VERSION "HNNBNNNYNNNNNNNNNNNNNNNNNNNNNNNNNNNNNNNNNN/4/%%%/4/'%**4NNN///"

NS_ :

BS_:

BU_: AWC BAP_Tester BMC_MLBevo BMS_MV BMS_NV DCDC_800V_PAG DCDC_HV DCDC_HV_02 DCDC_IHEV FCU_MLBevo_FCEV Gateway Gateway_PAG Ladegeraet_2 Ladegeraet_Konzern LE1 LE2 LE2_3_MLBevo_LB LE_MLBevo LE_MLBevo_LB Sub_Gateway TME

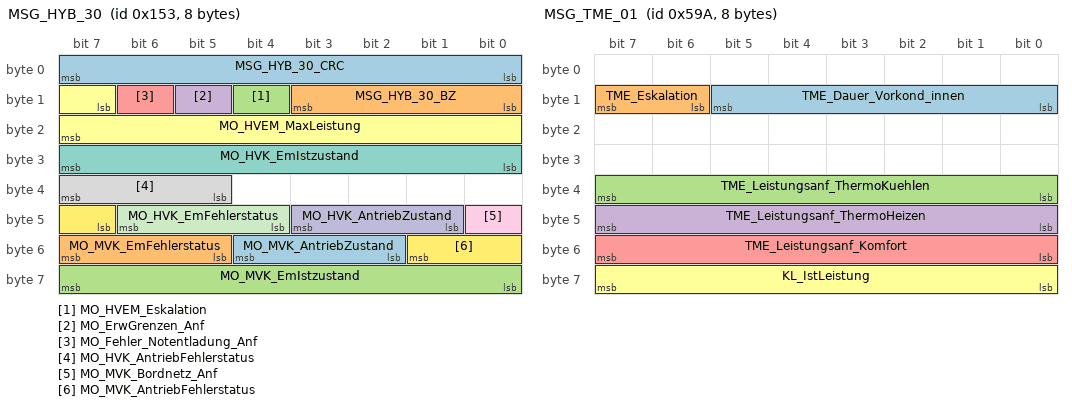
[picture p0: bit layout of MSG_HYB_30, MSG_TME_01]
BO_ 339 MSG_HYB_30: 8 Gateway
 SG_ MSG_HYB_30_CRC : 0|8@1+ (1,0) [0|255] ""  Ladegeraet_Konzern
 SG_ MSG_HYB_30_BZ : 8|4@1+ (1,0) [0|15] ""  Ladegeraet_Konzern
 SG_ MO_HVEM_Eskalation : 12|1@1+ (1,0) [0|1] "" Vector__XXX
 SG_ MO_ErwGrenzen_Anf : 13|1@1+ (1,0) [0|1] ""  BMC_MLBevo
 SG_ MO_Fehler_Notentladung_Anf : 14|1@1+ (1,0) [0|1] "" Vector__XXX
 SG_ MO_HVEM_MaxLeistung : 15|9@1+ (50,0) [0|25450] "Unit_Watt" Vector__XXX
 SG_ MO_HVK_EmIstzustand : 24|8@1+ (1,0) [0|255] "" Vector__XXX
 SG_ MO_HVK_AntriebFehlerstatus : 37|3@1+ (1,0) [0|7] "" Vector__XXX
 SG_ MO_MVK_Bordnetz_Anf : 40|1@1+ (1,0) [0|1] "" Vector__XXX
 SG_ MO_HVK_AntriebZustand : 41|3@1+ (1,0) [0|7] ""  TME
 SG_ MO_HVK_EmFehlerstatus : 44|3@1+ (1,0) [0|7] "" Vector__XXX
 SG_ MO_MVK_AntriebFehlerstatus : 47|3@1+ (1,0) [0|7] "" Vector__XXX
 SG_ MO_MVK_AntriebZustand : 50|3@1+ (1,0) [0|7] "" Vector__XXX
 SG_ MO_MVK_EmFehlerstatus : 53|3@1+ (1,0) [0|7] "" Vector__XXX
 SG_ MO_MVK_EmIstzustand : 56|8@1+ (1,0) [0|255] "" Vector__XXX

BO_ 1434 MSG_TME_01: 8 TME
 SG_ TME_Dauer_Vorkond_innen : 8|6@1+ (1,0) [0|60] "Unit_Minut"  Ladegeraet_Konzern
 SG_ TME_Eskalation : 14|2@1+ (1,0) [0|3] "" Vector__XXX
 SG_ TME_Leistungsanf_ThermoKuehlen : 32|8@1+ (50,0) [0|12650] "Unit_Watt" Vector__XXX
 SG_ TME_Leistungsanf_ThermoHeizen : 40|8@1+ (50,0) [0|12650] "Unit_Watt" Vector__XXX
 SG_ TME_Leistungsanf_Komfort : 48|8@1+ (50,0) [0|12650] "Unit_Watt" Vector__XXX
 SG_ KL_IstLeistung : 56|8@1+ (50,0) [0|12650] "Unit_Watt"  FCU_MLBevo_FCEV,Gateway,Gateway_PAG,Ladegeraet_Konzern

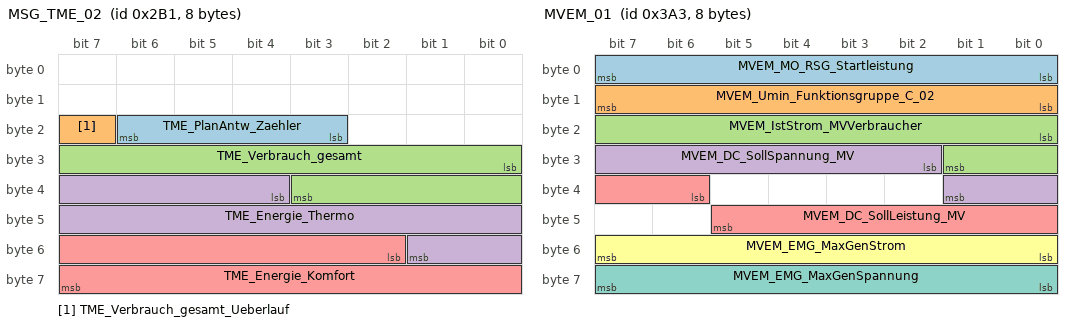
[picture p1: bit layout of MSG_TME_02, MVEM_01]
BO_ 689 MSG_TME_02: 8 TME
 SG_ TME_PlanAntw_Zaehler : 19|4@1+ (1,0) [0|13] "Unit_None"  Gateway,Gateway_PAG,Ladegeraet_2,Ladegeraet_Konzern
 SG_ TME_Verbrauch_gesamt_Ueberlauf : 23|1@1+ (1,0) [0|1] ""  Gateway,Gateway_PAG
 SG_ TME_Verbrauch_gesamt : 24|12@1+ (1,0) [0|4095] "Unit_WattSecond"  Gateway,Gateway_PAG
 SG_ TME_Energie_Thermo : 36|14@1+ (5,0) [0|63250] "Unit_WattHour"  Gateway,Gateway_PAG,Ladegeraet_Konzern
 SG_ TME_Energie_Komfort : 50|14@1+ (5,0) [0|63250] "Unit_WattHour"  Gateway,Gateway_PAG,Ladegeraet_Konzern

BO_ 931 MVEM_01: 8 Gateway
 SG_ MVEM_MO_RSG_Startleistung : 0|8@1+ (500,0) [0|126500] "Unit_Watt" Vector__XXX
 SG_ MVEM_Umin_Funktionsgruppe_C_02 : 8|8@1+ (0.25,0) [0|63.25] "Unit_Volt" Vector__XXX
 SG_ MVEM_IstStrom_MVVerbraucher : 16|10@1+ (1,-511) [-511|510] "Unit_Amper" Vector__XXX
 SG_ MVEM_DC_SollSpannung_MV : 26|8@1+ (0.25,0) [0|63.25] "Unit_Volt"  DCDC_800V_PAG,DCDC_IHEV
 SG_ MVEM_DC_SollLeistung_MV : 38|8@1+ (25,-6325) [-6325|0] "Unit_Watt"  DCDC_800V_PAG,DCDC_IHEV
 SG_ MVEM_EMG_MaxGenStrom : 48|8@1+ (2,0) [0|506] "Unit_Amper" Vector__XXX
 SG_ MVEM_EMG_MaxGenSpannung : 56|8@1+ (0.25,0) [0|63.25] "Unit_Volt" Vector__XXX

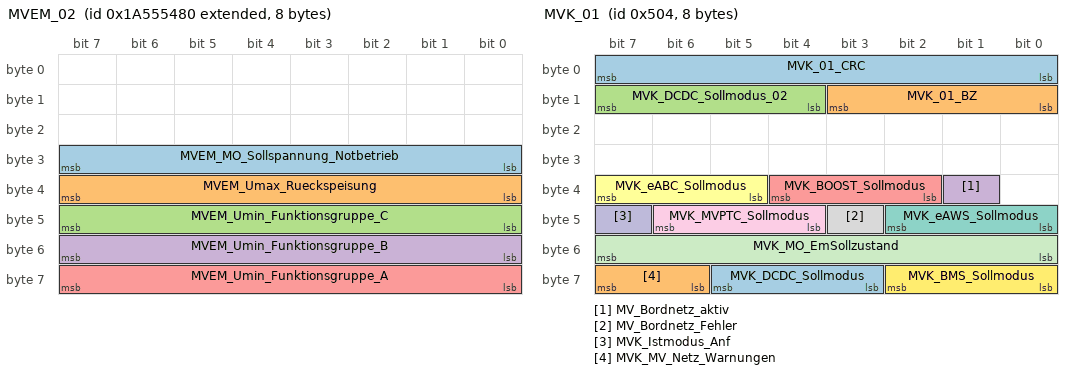
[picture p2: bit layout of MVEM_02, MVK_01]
BO_ 2589283456 MVEM_02: 8 Gateway
 SG_ MVEM_MO_Sollspannung_Notbetrieb : 24|8@1+ (0.25,0) [0|63.25] "Unit_Volt" Vector__XXX
 SG_ MVEM_Umax_Rueckspeisung : 32|8@1+ (0.25,0) [0|63.25] "Unit_Volt" Vector__XXX
 SG_ MVEM_Umin_Funktionsgruppe_C : 40|8@1+ (0.25,0) [0|63.25] "Unit_Volt" Vector__XXX
 SG_ MVEM_Umin_Funktionsgruppe_B : 48|8@1+ (0.25,0) [0|63.25] "Unit_Volt" Vector__XXX
 SG_ MVEM_Umin_Funktionsgruppe_A : 56|8@1+ (0.25,0) [0|63.25] "Unit_Volt"  DCDC_800V_PAG,DCDC_IHEV

BO_ 1284 MVK_01: 8 Gateway
 SG_ MVK_01_CRC : 0|8@1+ (1,0) [0|255] "" Vector__XXX
 SG_ MVK_01_BZ : 8|4@1+ (1,0) [0|15] "" Vector__XXX
 SG_ MVK_DCDC_Sollmodus_02 : 12|4@1+ (1,0) [0|15] ""  DCDC_IHEV
 SG_ MV_Bordnetz_aktiv : 33|1@1+ (1,0) [0|1] "" Vector__XXX
 SG_ MVK_BOOST_Sollmodus : 34|3@1+ (1,0) [0|7] "" Vector__XXX
 SG_ MVK_eABC_Sollmodus : 37|3@1+ (1,0) [0|7] "" Vector__XXX
 SG_ MVK_eAWS_Sollmodus : 40|3@1+ (1,0) [0|7] "" Vector__XXX
 SG_ MV_Bordnetz_Fehler : 43|1@1+ (1,0) [0|1] ""  TME
 SG_ MVK_MVPTC_Sollmodus : 44|3@1+ (1,0) [0|7] ""  TME
 SG_ MVK_Istmodus_Anf : 47|1@1+ (1,0) [0|1] ""  DCDC_IHEV
 SG_ MVK_MO_EmSollzustand : 48|8@1+ (1,0) [0|255] ""  DCDC_800V_PAG,DCDC_IHEV
 SG_ MVK_BMS_Sollmodus : 56|3@1+ (1,0) [0|7] "" Vector__XXX
 SG_ MVK_DCDC_Sollmodus : 59|3@1+ (1,0) [0|7] ""  DCDC_800V_PAG,DCDC_IHEV
 SG_ MVK_MV_Netz_Warnungen : 62|2@1+ (1,0) [0|3] "" Vector__XXX

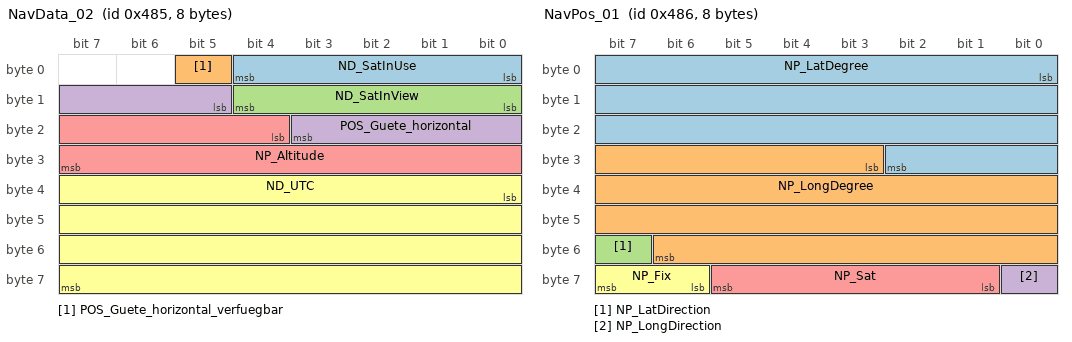
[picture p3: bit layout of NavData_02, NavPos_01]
BO_ 1157 NavData_02: 8 Gateway
 SG_ ND_SatInUse : 0|5@1+ (1,0) [0|29] ""  Sub_Gateway,TME
 SG_ POS_Guete_horizontal_verfuegbar : 5|1@1+ (1,0) [0|1] ""  Sub_Gateway
 SG_ ND_SatInView : 8|5@1+ (1,0) [0|29] ""  Sub_Gateway
 SG_ POS_Guete_horizontal : 13|7@1+ (2,0) [0|246] "Unit_Meter"  Sub_Gateway
 SG_ NP_Altitude : 20|12@1+ (2,-500) [-500|7686] "Unit_Meter"  Sub_Gateway,TME
 SG_ ND_UTC : 32|32@1+ (1,0) [0|4294967293] "Unit_Secon"  Ladegeraet_Konzern,Sub_Gateway

BO_ 1158 NavPos_01: 8 Gateway
 SG_ NP_LatDegree : 0|27@1+ (1E-006,0) [0|90] "Unit_DegreOfArc"  Sub_Gateway
 SG_ NP_LongDegree : 27|28@1+ (1E-006,0) [0|180] "Unit_DegreOfArc"  Sub_Gateway
 SG_ NP_LatDirection : 55|1@1+ (1,0) [0|1] ""  Sub_Gateway
 SG_ NP_LongDirection : 56|1@1+ (1,0) [0|1] ""  Sub_Gateway
 SG_ NP_Sat : 57|5@1+ (1,0) [0|29] ""  Sub_Gateway
 SG_ NP_Fix : 62|2@1+ (1,0) [0|3] ""  Sub_Gateway

BO_ 2589283496 NavPos_02_Map_Matched: 8 Gateway
 SG_ POS_MUX M : 0|2@1+ (1,0) [0|3] ""  Sub_Gateway
 SG_ POS_ODD_EVEN : 2|1@1+ (1,0) [0|1] ""  Sub_Gateway
 SG_ POS_PosStati m0 : 3|4@1+ (1,0) [0|15] ""  Sub_Gateway
 SG_ POS_Heading m1 : 4|12@1+ (0.1,0) [0|409.5] "Unit_DegreOfArc"  Sub_Gateway
 SG_ POS_LatDirection m0 : 7|1@1+ (1,0) [0|1] ""  Sub_Gateway
 SG_ POS_LatDegree m0 : 8|27@1+ (1E-006,0) [0|90] "Unit_DegreOfArc"  Sub_Gateway
 SG_ POS_Last_GPS_Sync m1 : 16|14@1+ (1,0) [0|16383] "Unit_Secon"  Sub_Gateway
 SG_ POS_Heading_Trust m1 : 30|2@1+ (1,0) [0|3] ""  Sub_Gateway
 SG_ POS_UTC_REF m1 : 32|32@1+ (1,0) [0|4294967295] "Unit_Secon"  Sub_Gateway
 SG_ POS_LongDirection m0 : 35|1@1+ (1,0) [0|1] ""  Sub_Gateway
 SG_ POS_LongDegree m0 : 36|28@1+ (1E-006,0) [0|180] "Unit_DegreOfArc"  Sub_Gateway

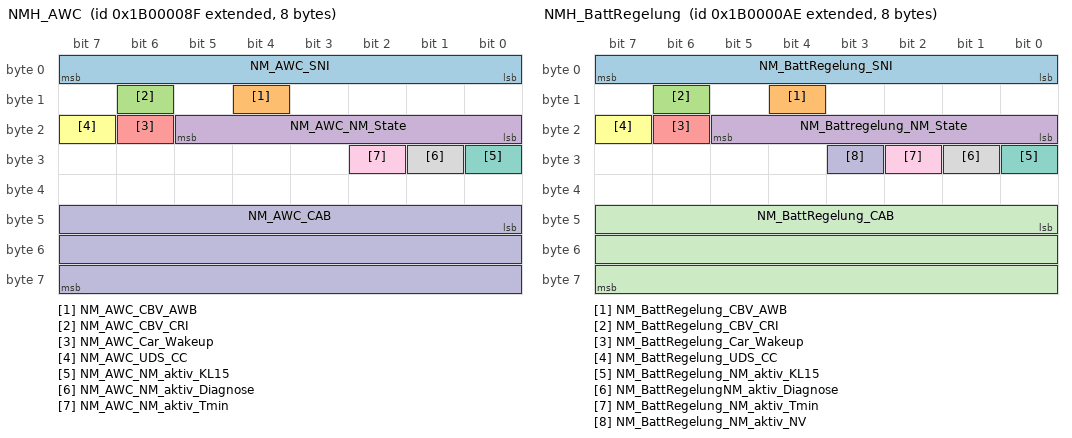
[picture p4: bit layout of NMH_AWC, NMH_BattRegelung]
BO_ 2600468623 NMH_AWC: 8 AWC
 SG_ NM_AWC_SNI : 0|8@1+ (1,0) [0|255] ""  BMC_MLBevo,BMS_MV,BMS_NV,DCDC_800V_PAG,DCDC_HV,DCDC_HV_02,DCDC_IHEV,FCU_MLBevo_FCEV,Gateway,Gateway_PAG,Ladegeraet_2,Ladegeraet_Konzern,LE1,LE2,LE_MLBevo,Sub_Gateway,TME
 SG_ NM_AWC_CBV_AWB : 12|1@1+ (1,0) [0|1] ""  Gateway,Gateway_PAG
 SG_ NM_AWC_CBV_CRI : 14|1@1+ (1,0) [0|1] ""  BMC_MLBevo,BMS_MV,BMS_NV,DCDC_800V_PAG,DCDC_HV,DCDC_HV_02,DCDC_IHEV,FCU_MLBevo_FCEV,Gateway,Gateway_PAG,Ladegeraet_2,Ladegeraet_Konzern,LE1,LE2,LE_MLBevo,Sub_Gateway,TME
 SG_ NM_AWC_NM_State : 16|6@1+ (1,0) [0|63] "" Vector__XXX
 SG_ NM_AWC_Car_Wakeup : 22|1@1+ (1,0) [0|1] ""  Gateway,Gateway_PAG
 SG_ NM_AWC_UDS_CC : 23|1@1+ (1,0) [0|1] "" Vector__XXX
 SG_ NM_AWC_NM_aktiv_KL15 : 24|1@1+ (1,0) [0|1] "" Vector__XXX
 SG_ NM_AWC_NM_aktiv_Diagnose : 25|1@1+ (1,0) [0|1] "" Vector__XXX
 SG_ NM_AWC_NM_aktiv_Tmin : 26|1@1+ (1,0) [0|1] "" Vector__XXX
 SG_ NM_AWC_CAB : 40|24@1+ (1,0) [0|16777215] ""  BMC_MLBevo,BMS_MV,BMS_NV,DCDC_800V_PAG,DCDC_HV,DCDC_HV_02,DCDC_IHEV,FCU_MLBevo_FCEV,Gateway,Gateway_PAG,Ladegeraet_2,Ladegeraet_Konzern,LE1,LE2,LE_MLBevo,Sub_Gateway,TME

BO_ 2600468654 NMH_BattRegelung: 8 BMS_NV
 SG_ NM_BattRegelung_SNI : 0|8@1+ (1,0) [0|255] ""  AWC,BMC_MLBevo,BMS_MV,DCDC_800V_PAG,DCDC_HV,DCDC_HV_02,DCDC_IHEV,FCU_MLBevo_FCEV,Gateway,Gateway_PAG,Ladegeraet_2,Ladegeraet_Konzern,LE1,LE2,LE2_3_MLBevo_LB,LE_MLBevo,Sub_Gateway,TME
 SG_ NM_BattRegelung_CBV_AWB : 12|1@1+ (1,0) [0|1] ""  Gateway,Gateway_PAG
 SG_ NM_BattRegelung_CBV_CRI : 14|1@1+ (1,0) [0|1] ""  AWC,BMC_MLBevo,BMS_MV,DCDC_800V_PAG,DCDC_HV,DCDC_HV_02,DCDC_IHEV,FCU_MLBevo_FCEV,Gateway,Gateway_PAG,Ladegeraet_2,Ladegeraet_Konzern,LE1,LE2,LE2_3_MLBevo_LB,LE_MLBevo,Sub_Gateway,TME
 SG_ NM_Battregelung_NM_State : 16|6@1+ (1,0) [0|63] "" Vector__XXX
 SG_ NM_BattRegelung_Car_Wakeup : 22|1@1+ (1,0) [0|1] ""  Gateway
 SG_ NM_BattRegelung_UDS_CC : 23|1@1+ (1,0) [0|1] "" Vector__XXX
 SG_ NM_BattRegelung_NM_aktiv_KL15 : 24|1@1+ (1,0) [0|1] "" Vector__XXX
 SG_ NM_BattRegelungNM_aktiv_Diagnose : 25|1@1+ (1,0) [0|1] "" Vector__XXX
 SG_ NM_BattRegelung_NM_aktiv_Tmin : 26|1@1+ (1,0) [0|1] "" Vector__XXX
 SG_ NM_BattRegelung_NM_aktiv_NV : 27|1@1+ (1,0) [0|1] "" Vector__XXX
 SG_ NM_BattRegelung_CAB : 40|24@1+ (1,0) [0|16777215] ""  AWC,BMC_MLBevo,BMS_MV,DCDC_800V_PAG,DCDC_HV,DCDC_HV_02,DCDC_IHEV,FCU_MLBevo_FCEV,Gateway,Gateway_PAG,Ladegeraet_2,Ladegeraet_Konzern,LE1,LE2,LE2_3_MLBevo_LB,LE_MLBevo,Sub_Gateway,TME

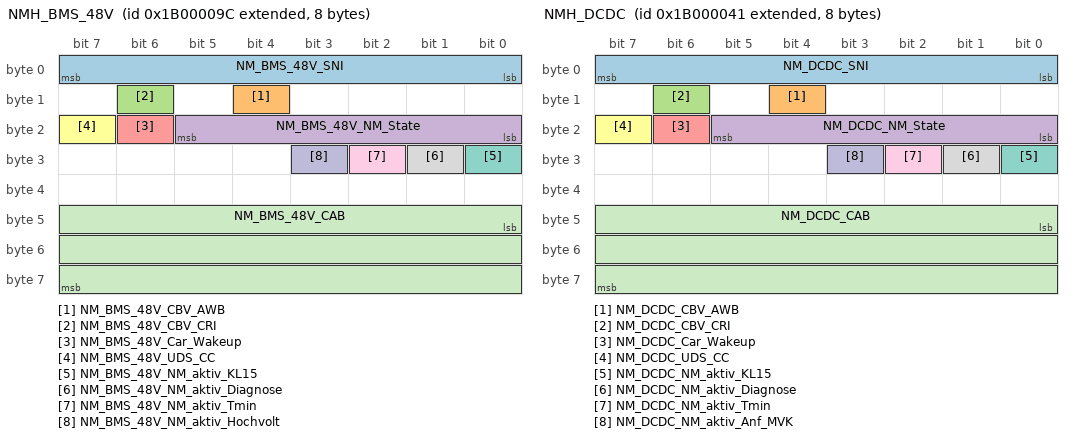
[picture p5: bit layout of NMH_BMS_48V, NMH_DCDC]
BO_ 2600468636 NMH_BMS_48V: 8 BMS_MV
 SG_ NM_BMS_48V_SNI : 0|8@1+ (1,0) [0|255] ""  AWC,BMC_MLBevo,BMS_NV,DCDC_800V_PAG,DCDC_HV,DCDC_HV_02,DCDC_IHEV,Gateway,Gateway_PAG,Ladegeraet_2,Ladegeraet_Konzern,LE1,LE2,LE2_3_MLBevo_LB,LE_MLBevo,Sub_Gateway,TME
 SG_ NM_BMS_48V_CBV_AWB : 12|1@1+ (1,0) [0|1] ""  Gateway,Gateway_PAG
 SG_ NM_BMS_48V_CBV_CRI : 14|1@1+ (1,0) [0|1] ""  AWC,BMC_MLBevo,BMS_NV,DCDC_800V_PAG,DCDC_HV,DCDC_HV_02,DCDC_IHEV,Gateway,Gateway_PAG,Ladegeraet_2,Ladegeraet_Konzern,LE1,LE2,LE2_3_MLBevo_LB,LE_MLBevo,Sub_Gateway,TME
 SG_ NM_BMS_48V_NM_State : 16|6@1+ (1,0) [0|63] "" Vector__XXX
 SG_ NM_BMS_48V_Car_Wakeup : 22|1@1+ (1,0) [0|1] ""  Gateway,Gateway_PAG
 SG_ NM_BMS_48V_UDS_CC : 23|1@1+ (1,0) [0|1] "" Vector__XXX
 SG_ NM_BMS_48V_NM_aktiv_KL15 : 24|1@1+ (1,0) [0|1] "" Vector__XXX
 SG_ NM_BMS_48V_NM_aktiv_Diagnose : 25|1@1+ (1,0) [0|1] "" Vector__XXX
 SG_ NM_BMS_48V_NM_aktiv_Tmin : 26|1@1+ (1,0) [0|1] "" Vector__XXX
 SG_ NM_BMS_48V_NM_aktiv_Hochvolt : 27|1@1+ (1,0) [0|1] "" Vector__XXX
 SG_ NM_BMS_48V_CAB : 40|24@1+ (1,0) [0|16777215] ""  AWC,BMC_MLBevo,BMS_NV,DCDC_800V_PAG,DCDC_HV,DCDC_HV_02,DCDC_IHEV,Gateway,Gateway_PAG,Ladegeraet_2,Ladegeraet_Konzern,LE1,LE2,LE2_3_MLBevo_LB,LE_MLBevo,Sub_Gateway,TME

BO_ 2600468545 NMH_DCDC: 8 DCDC_IHEV
 SG_ NM_DCDC_SNI : 0|8@1+ (1,0) [0|255] ""  AWC,BMC_MLBevo,BMS_MV,BMS_NV,DCDC_HV,DCDC_HV_02,FCU_MLBevo_FCEV,Gateway,Gateway_PAG,Ladegeraet_2,Ladegeraet_Konzern,LE1,LE2,LE2_3_MLBevo_LB,LE_MLBevo,Sub_Gateway,TME
 SG_ NM_DCDC_CBV_AWB : 12|1@1+ (1,0) [0|1] ""  Gateway,Gateway_PAG
 SG_ NM_DCDC_CBV_CRI : 14|1@1+ (1,0) [0|1] ""  AWC,BMC_MLBevo,BMS_MV,BMS_NV,DCDC_HV,DCDC_HV_02,FCU_MLBevo_FCEV,Gateway,Gateway_PAG,Ladegeraet_2,Ladegeraet_Konzern,LE1,LE2,LE2_3_MLBevo_LB,LE_MLBevo,Sub_Gateway,TME
 SG_ NM_DCDC_NM_State : 16|6@1+ (1,0) [0|63] "" Vector__XXX
 SG_ NM_DCDC_Car_Wakeup : 22|1@1+ (1,0) [0|1] ""  Gateway
 SG_ NM_DCDC_UDS_CC : 23|1@1+ (1,0) [0|1] "" Vector__XXX
 SG_ NM_DCDC_NM_aktiv_KL15 : 24|1@1+ (1,0) [0|1] "" Vector__XXX
 SG_ NM_DCDC_NM_aktiv_Diagnose : 25|1@1+ (1,0) [0|1] "" Vector__XXX
 SG_ NM_DCDC_NM_aktiv_Tmin : 26|1@1+ (1,0) [0|1] "" Vector__XXX
 SG_ NM_DCDC_NM_aktiv_Anf_MVK : 27|1@1+ (1,0) [0|1] "" Vector__XXX
 SG_ NM_DCDC_CAB : 40|24@1+ (1,0) [0|16777215] ""  AWC,BMC_MLBevo,BMS_MV,BMS_NV,DCDC_HV,DCDC_HV_02,FCU_MLBevo_FCEV,Gateway,Gateway_PAG,Ladegeraet_2,Ladegeraet_Konzern,LE1,LE2,LE2_3_MLBevo_LB,LE_MLBevo,Sub_Gateway,TME

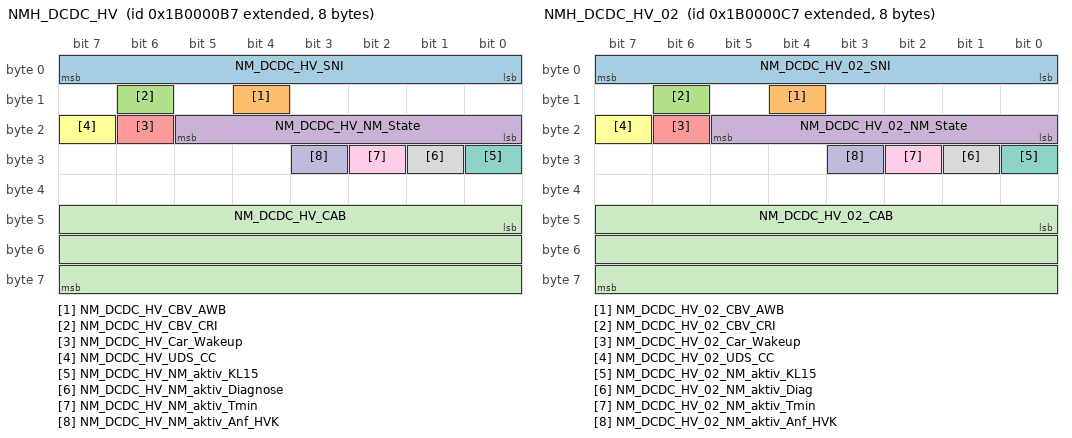
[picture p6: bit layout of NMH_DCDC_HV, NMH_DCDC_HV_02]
BO_ 2600468663 NMH_DCDC_HV: 8 DCDC_800V_PAG
 SG_ NM_DCDC_HV_SNI : 0|8@1+ (1,0) [0|255] ""  AWC,BMC_MLBevo,BMS_MV,BMS_NV,DCDC_HV_02,DCDC_IHEV,Gateway,Gateway_PAG,Ladegeraet_2,Ladegeraet_Konzern,LE1,LE2,LE2_3_MLBevo_LB,LE_MLBevo,Sub_Gateway,TME
 SG_ NM_DCDC_HV_CBV_AWB : 12|1@1+ (1,0) [0|1] ""  Gateway,Gateway_PAG
 SG_ NM_DCDC_HV_CBV_CRI : 14|1@1+ (1,0) [0|1] ""  AWC,BMC_MLBevo,BMS_MV,BMS_NV,DCDC_HV_02,DCDC_IHEV,Gateway,Gateway_PAG,Ladegeraet_2,Ladegeraet_Konzern,LE1,LE2,LE2_3_MLBevo_LB,LE_MLBevo,Sub_Gateway,TME
 SG_ NM_DCDC_HV_NM_State : 16|6@1+ (1,0) [0|63] "" Vector__XXX
 SG_ NM_DCDC_HV_Car_Wakeup : 22|1@1+ (1,0) [0|1] ""  Gateway,Gateway_PAG
 SG_ NM_DCDC_HV_UDS_CC : 23|1@1+ (1,0) [0|1] "" Vector__XXX
 SG_ NM_DCDC_HV_NM_aktiv_KL15 : 24|1@1+ (1,0) [0|1] "" Vector__XXX
 SG_ NM_DCDC_HV_NM_aktiv_Diagnose : 25|1@1+ (1,0) [0|1] "" Vector__XXX
 SG_ NM_DCDC_HV_NM_aktiv_Tmin : 26|1@1+ (1,0) [0|1] "" Vector__XXX
 SG_ NM_DCDC_HV_NM_aktiv_Anf_HVK : 27|1@1+ (1,0) [0|1] "" Vector__XXX
 SG_ NM_DCDC_HV_CAB : 40|24@1+ (1,0) [0|16777215] ""  AWC,BMC_MLBevo,BMS_MV,BMS_NV,DCDC_HV_02,DCDC_IHEV,Gateway,Gateway_PAG,Ladegeraet_2,Ladegeraet_Konzern,LE1,LE2,LE2_3_MLBevo_LB,LE_MLBevo,Sub_Gateway,TME

BO_ 2600468679 NMH_DCDC_HV_02: 8 DCDC_HV_02
 SG_ NM_DCDC_HV_02_SNI : 0|8@1+ (1,0) [0|255] ""  AWC,BMC_MLBevo,BMS_MV,BMS_NV,DCDC_800V_PAG,DCDC_HV,DCDC_IHEV,FCU_MLBevo_FCEV,Gateway,Gateway_PAG,Ladegeraet_2,Ladegeraet_Konzern,LE1,LE2,LE2_3_MLBevo_LB,LE_MLBevo,Sub_Gateway,TME
 SG_ NM_DCDC_HV_02_CBV_AWB : 12|1@1+ (1,0) [0|1] ""  Gateway,Gateway_PAG
 SG_ NM_DCDC_HV_02_CBV_CRI : 14|1@1+ (1,0) [0|1] ""  AWC,BMC_MLBevo,BMS_MV,BMS_NV,DCDC_800V_PAG,DCDC_HV,DCDC_IHEV,FCU_MLBevo_FCEV,Gateway,Gateway_PAG,Ladegeraet_2,Ladegeraet_Konzern,LE1,LE2,LE2_3_MLBevo_LB,LE_MLBevo,Sub_Gateway,TME
 SG_ NM_DCDC_HV_02_NM_State : 16|6@1+ (1,0) [0|63] "" Vector__XXX
 SG_ NM_DCDC_HV_02_Car_Wakeup : 22|1@1+ (1,0) [0|1] ""  Gateway,Gateway_PAG
 SG_ NM_DCDC_HV_02_UDS_CC : 23|1@1+ (1,0) [0|1] "" Vector__XXX
 SG_ NM_DCDC_HV_02_NM_aktiv_KL15 : 24|1@1+ (1,0) [0|1] "" Vector__XXX
 SG_ NM_DCDC_HV_02_NM_aktiv_Diag : 25|1@1+ (1,0) [0|1] "" Vector__XXX
 SG_ NM_DCDC_HV_02_NM_aktiv_Tmin : 26|1@1+ (1,0) [0|1] "" Vector__XXX
 SG_ NM_DCDC_HV_02_NM_aktiv_Anf_HVK : 27|1@1+ (1,0) [0|1] "" Vector__XXX
 SG_ NM_DCDC_HV_02_CAB : 40|24@1+ (1,0) [0|16777215] ""  AWC,BMC_MLBevo,BMS_MV,BMS_NV,DCDC_800V_PAG,DCDC_HV,DCDC_IHEV,FCU_MLBevo_FCEV,Gateway,Gateway_PAG,Ladegeraet_2,Ladegeraet_Konzern,LE1,LE2,LE2_3_MLBevo_LB,LE_MLBevo,Sub_Gateway,TME

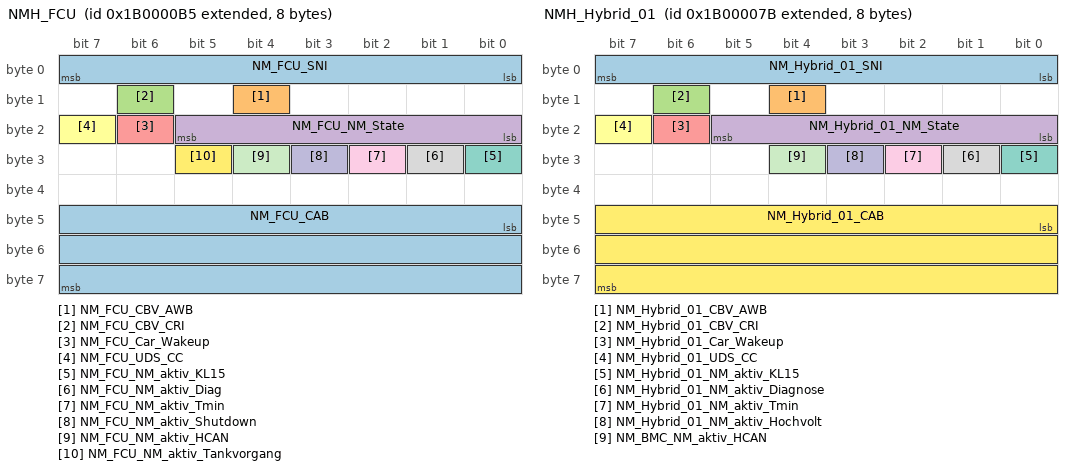
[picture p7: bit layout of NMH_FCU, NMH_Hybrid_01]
BO_ 2600468661 NMH_FCU: 8 FCU_MLBevo_FCEV
 SG_ NM_FCU_SNI : 0|8@1+ (1,0) [0|255] ""  Gateway
 SG_ NM_FCU_CBV_AWB : 12|1@1+ (1,0) [0|1] "" Vector__XXX
 SG_ NM_FCU_CBV_CRI : 14|1@1+ (1,0) [0|1] ""  Gateway
 SG_ NM_FCU_NM_State : 16|6@1+ (1,0) [0|63] "" Vector__XXX
 SG_ NM_FCU_Car_Wakeup : 22|1@1+ (1,0) [0|1] ""  Gateway
 SG_ NM_FCU_UDS_CC : 23|1@1+ (1,0) [0|1] "" Vector__XXX
 SG_ NM_FCU_NM_aktiv_KL15 : 24|1@1+ (1,0) [0|1] "" Vector__XXX
 SG_ NM_FCU_NM_aktiv_Diag : 25|1@1+ (1,0) [0|1] "" Vector__XXX
 SG_ NM_FCU_NM_aktiv_Tmin : 26|1@1+ (1,0) [0|1] "" Vector__XXX
 SG_ NM_FCU_NM_aktiv_Shutdown : 27|1@1+ (1,0) [0|1] "" Vector__XXX
 SG_ NM_FCU_NM_aktiv_HCAN : 28|1@1+ (1,0) [0|1] "" Vector__XXX
 SG_ NM_FCU_NM_aktiv_Tankvorgang : 29|1@1+ (1,0) [0|1] "" Vector__XXX
 SG_ NM_FCU_CAB : 40|24@1+ (1,0) [0|16777215] ""  Gateway

BO_ 2600468496 NMH_Gateway: 8 Gateway
 SG_ NM_Gateway_SNI : 0|8@1+ (1,0) [0|255] ""  AWC,BMC_MLBevo,BMS_MV,BMS_NV,DCDC_800V_PAG,DCDC_HV,DCDC_HV_02,DCDC_IHEV,FCU_MLBevo_FCEV,Ladegeraet_2,Ladegeraet_Konzern,LE1,LE2,LE2_3_MLBevo_LB,LE_MLBevo,Sub_Gateway,TME
 SG_ NM_Gateway_CBV_AWB : 12|1@1+ (1,0) [0|1] "" Vector__XXX
 SG_ NM_Gateway_CBV_CRI : 14|1@1+ (1,0) [0|1] ""  AWC,BMC_MLBevo,BMS_MV,BMS_NV,DCDC_800V_PAG,DCDC_HV,DCDC_HV_02,DCDC_IHEV,FCU_MLBevo_FCEV,Ladegeraet_2,Ladegeraet_Konzern,LE1,LE2,LE2_3_MLBevo_LB,LE_MLBevo,Sub_Gateway,TME
 SG_ NM_Gateway_NM_State : 16|6@1+ (1,0) [0|63] "" Vector__XXX
 SG_ NM_Gateway_Car_Wakeup : 22|1@1+ (1,0) [0|1] "" Vector__XXX
 SG_ NM_Gateway_UDS_CC : 23|1@1+ (1,0) [0|1] "" Vector__XXX
 SG_ NM_Gateway_NM_aktiv_KL15 : 24|1@1+ (1,0) [0|1] "" Vector__XXX
 SG_ NM_Gateway_NM_aktiv_Diagnose : 25|1@1+ (1,0) [0|1] "" Vector__XXX
 SG_ NM_Gateway_NM_aktiv_Tmin : 26|1@1+ (1,0) [0|1] "" Vector__XXX
 SG_ NM_Gateway_NM_aktiv_CWU : 27|1@1+ (1,0) [0|1] "" Vector__XXX
 SG_ NM_Gateway_NM_aktiv_FC : 28|1@1+ (1,0) [0|1] "" Vector__XXX
 SG_ NM_Gateway_NM_aktiv_Connect : 29|1@1+ (1,0) [0|1] "" Vector__XXX
 SG_ NM_Gateway_NM_aktiv_EM : 30|1@1+ (1,0) [0|1] "" Vector__XXX
 SG_ NM_Gateway_NM_aktiv_OBDC : 31|1@1+ (1,0) [0|1] "" Vector__XXX
 SG_ NM_Gateway_NM_aktiv_Buskopplung : 32|1@1+ (1,0) [0|1] "" Vector__XXX
 SG_ NM_Gateway_NM_aktiv_LIN2 : 33|1@1+ (1,0) [0|1] "" Vector__XXX
 SG_ NM_Gateway_CAB : 40|24@1+ (1,0) [0|16777215] ""  AWC,BMC_MLBevo,BMS_MV,BMS_NV,DCDC_800V_PAG,DCDC_HV,DCDC_HV_02,DCDC_IHEV,FCU_MLBevo_FCEV,Ladegeraet_2,Ladegeraet_Konzern,LE1,LE2,LE2_3_MLBevo_LB,LE_MLBevo,Sub_Gateway,TME

BO_ 2600468603 NMH_Hybrid_01: 8 BMC_MLBevo
 SG_ NM_Hybrid_01_SNI : 0|8@1+ (1,0) [0|255] ""  AWC,BMS_MV,BMS_NV,DCDC_800V_PAG,DCDC_HV,DCDC_HV_02,DCDC_IHEV,FCU_MLBevo_FCEV,Gateway,Gateway_PAG,Ladegeraet_2,Ladegeraet_Konzern,LE1,LE2,LE2_3_MLBevo_LB,LE_MLBevo,Sub_Gateway,TME
 SG_ NM_Hybrid_01_CBV_AWB : 12|1@1+ (1,0) [0|1] ""  Gateway,Gateway_PAG
 SG_ NM_Hybrid_01_CBV_CRI : 14|1@1+ (1,0) [0|1] ""  AWC,BMS_MV,BMS_NV,DCDC_800V_PAG,DCDC_HV,DCDC_HV_02,DCDC_IHEV,FCU_MLBevo_FCEV,Gateway,Gateway_PAG,Ladegeraet_2,Ladegeraet_Konzern,LE1,LE2,LE2_3_MLBevo_LB,LE_MLBevo,Sub_Gateway,TME
 SG_ NM_Hybrid_01_NM_State : 16|6@1+ (1,0) [0|63] "" Vector__XXX
 SG_ NM_Hybrid_01_Car_Wakeup : 22|1@1+ (1,0) [0|1] ""  Gateway
 SG_ NM_Hybrid_01_UDS_CC : 23|1@1+ (1,0) [0|1] "" Vector__XXX
 SG_ NM_Hybrid_01_NM_aktiv_KL15 : 24|1@1+ (1,0) [0|1] "" Vector__XXX
 SG_ NM_Hybrid_01_NM_aktiv_Diagnose : 25|1@1+ (1,0) [0|1] "" Vector__XXX
 SG_ NM_Hybrid_01_NM_aktiv_Tmin : 26|1@1+ (1,0) [0|1] "" Vector__XXX
 SG_ NM_Hybrid_01_NM_aktiv_Hochvolt : 27|1@1+ (1,0) [0|1] "" Vector__XXX
 SG_ NM_BMC_NM_aktiv_HCAN : 28|1@1+ (1,0) [0|1] "" Vector__XXX
 SG_ NM_Hybrid_01_CAB : 40|24@1+ (1,0) [0|16777215] ""  AWC,BMS_MV,BMS_NV,DCDC_800V_PAG,DCDC_HV,DCDC_HV_02,DCDC_IHEV,FCU_MLBevo_FCEV,Gateway,Gateway_PAG,Ladegeraet_2,Ladegeraet_Konzern,LE1,LE2,LE2_3_MLBevo_LB,LE_MLBevo,Sub_Gateway,TME

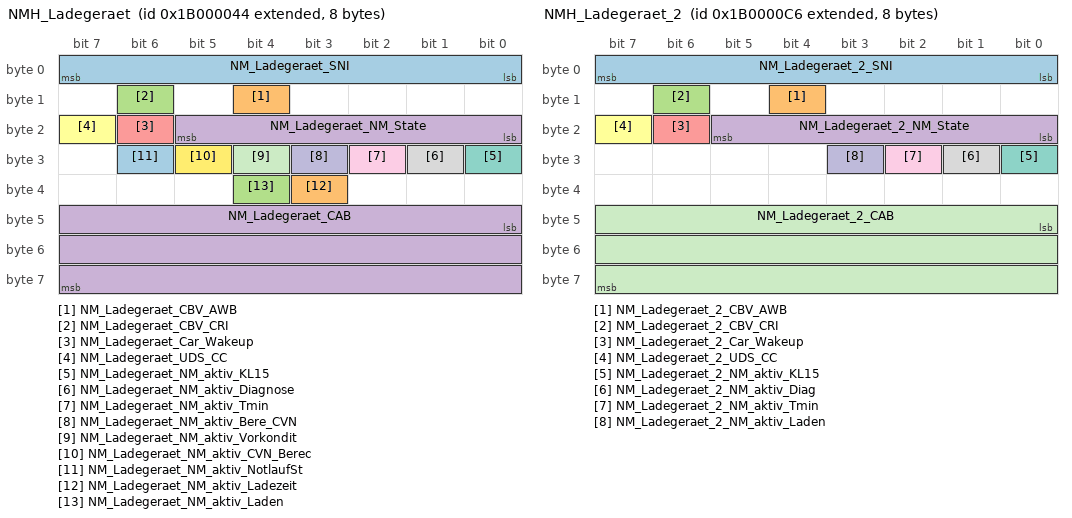
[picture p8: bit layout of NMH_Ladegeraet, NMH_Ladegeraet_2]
BO_ 2600468548 NMH_Ladegeraet: 8 Ladegeraet_Konzern
 SG_ NM_Ladegeraet_SNI : 0|8@1+ (1,0) [0|255] ""  AWC,BMC_MLBevo,BMS_MV,BMS_NV,DCDC_800V_PAG,DCDC_HV,DCDC_HV_02,DCDC_IHEV,FCU_MLBevo_FCEV,Gateway,Gateway_PAG,Ladegeraet_2,LE1,LE2,LE2_3_MLBevo_LB,LE_MLBevo,Sub_Gateway,TME
 SG_ NM_Ladegeraet_CBV_AWB : 12|1@1+ (1,0) [0|1] ""  Gateway,Gateway_PAG
 SG_ NM_Ladegeraet_CBV_CRI : 14|1@1+ (1,0) [0|1] ""  AWC,BMC_MLBevo,BMS_MV,BMS_NV,DCDC_800V_PAG,DCDC_HV,DCDC_HV_02,DCDC_IHEV,FCU_MLBevo_FCEV,Gateway,Gateway_PAG,Ladegeraet_2,LE1,LE2,LE2_3_MLBevo_LB,LE_MLBevo,Sub_Gateway,TME
 SG_ NM_Ladegeraet_NM_State : 16|6@1+ (1,0) [0|63] "" Vector__XXX
 SG_ NM_Ladegeraet_Car_Wakeup : 22|1@1+ (1,0) [0|1] ""  Gateway
 SG_ NM_Ladegeraet_UDS_CC : 23|1@1+ (1,0) [0|1] "" Vector__XXX
 SG_ NM_Ladegeraet_NM_aktiv_KL15 : 24|1@1+ (1,0) [0|1] "" Vector__XXX
 SG_ NM_Ladegeraet_NM_aktiv_Diagnose : 25|1@1+ (1,0) [0|1] "" Vector__XXX
 SG_ NM_Ladegeraet_NM_aktiv_Tmin : 26|1@1+ (1,0) [0|1] "" Vector__XXX
 SG_ NM_Ladegeraet_NM_aktiv_Bere_CVN : 27|1@1+ (1,0) [0|1] "" Vector__XXX
 SG_ NM_Ladegeraet_NM_aktiv_Vorkondit : 28|1@1+ (1,0) [0|1] "" Vector__XXX
 SG_ NM_Ladegeraet_NM_aktiv_CVN_Berec : 29|1@1+ (1,0) [0|1] "" Vector__XXX
 SG_ NM_Ladegeraet_NM_aktiv_NotlaufSt : 30|1@1+ (1,0) [0|1] "" Vector__XXX
 SG_ NM_Ladegeraet_NM_aktiv_Ladezeit : 35|1@1+ (1,0) [0|1] "" Vector__XXX
 SG_ NM_Ladegeraet_NM_aktiv_Laden : 36|1@1+ (1,0) [0|1] "" Vector__XXX
 SG_ NM_Ladegeraet_CAB : 40|24@1+ (1,0) [0|16777215] ""  AWC,BMC_MLBevo,BMS_MV,BMS_NV,DCDC_800V_PAG,DCDC_HV,DCDC_HV_02,DCDC_IHEV,FCU_MLBevo_FCEV,Gateway,Gateway_PAG,Ladegeraet_2,LE1,LE2,LE2_3_MLBevo_LB,LE_MLBevo,Sub_Gateway,TME

BO_ 2600468678 NMH_Ladegeraet_2: 8 Ladegeraet_2
 SG_ NM_Ladegeraet_2_SNI : 0|8@1+ (1,0) [0|255] ""  AWC,BMC_MLBevo,BMS_MV,BMS_NV,DCDC_800V_PAG,DCDC_HV,DCDC_HV_02,DCDC_IHEV,FCU_MLBevo_FCEV,Gateway,Gateway_PAG,Ladegeraet_2,Ladegeraet_Konzern,LE1,LE2,LE2_3_MLBevo_LB,LE_MLBevo,Sub_Gateway,TME
 SG_ NM_Ladegeraet_2_CBV_AWB : 12|1@1+ (1,0) [0|1] ""  Gateway,Gateway_PAG
 SG_ NM_Ladegeraet_2_CBV_CRI : 14|1@1+ (1,0) [0|1] ""  AWC,BMC_MLBevo,BMS_MV,BMS_NV,DCDC_800V_PAG,DCDC_HV,DCDC_HV_02,DCDC_IHEV,FCU_MLBevo_FCEV,Gateway,Gateway_PAG,Ladegeraet_2,Ladegeraet_Konzern,LE1,LE2,LE2_3_MLBevo_LB,LE_MLBevo,Sub_Gateway,TME
 SG_ NM_Ladegeraet_2_NM_State : 16|6@1+ (1,0) [0|63] "" Vector__XXX
 SG_ NM_Ladegeraet_2_Car_Wakeup : 22|1@1+ (1,0) [0|1] ""  Gateway,Gateway_PAG
 SG_ NM_Ladegeraet_2_UDS_CC : 23|1@1+ (1,0) [0|1] ""  Gateway,Gateway_PAG
 SG_ NM_Ladegeraet_2_NM_aktiv_KL15 : 24|1@1+ (1,0) [0|1] "" Vector__XXX
 SG_ NM_Ladegeraet_2_NM_aktiv_Diag : 25|1@1+ (1,0) [0|1] "" Vector__XXX
 SG_ NM_Ladegeraet_2_NM_aktiv_Tmin : 26|1@1+ (1,0) [0|1] ""  Gateway_PAG
 SG_ NM_Ladegeraet_2_NM_aktiv_Laden : 27|1@1+ (1,0) [0|1] "" Vector__XXX
 SG_ NM_Ladegeraet_2_CAB : 40|24@1+ (1,0) [0|16777215] ""  AWC,BMC_MLBevo,BMS_MV,BMS_NV,DCDC_800V_PAG,DCDC_HV,DCDC_HV_02,DCDC_IHEV,FCU_MLBevo_FCEV,Gateway,Gateway_PAG,Ladegeraet_2,Ladegeraet_Konzern,LE1,LE2,LE2_3_MLBevo_LB,LE_MLBevo,Sub_Gateway,TME

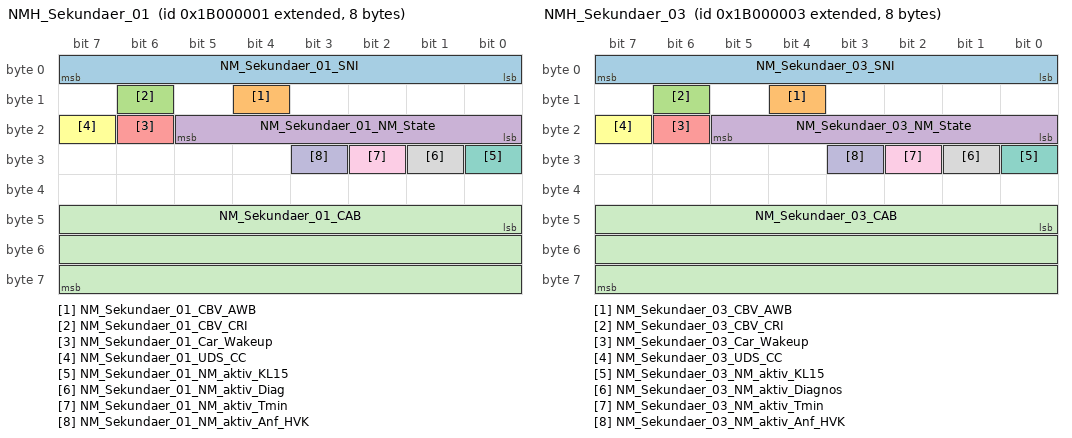
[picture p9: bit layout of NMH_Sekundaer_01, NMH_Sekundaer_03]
BO_ 2600468481 NMH_Sekundaer_01: 8 LE2
 SG_ NM_Sekundaer_01_SNI : 0|8@1+ (1,0) [0|255] ""  AWC,BMC_MLBevo,BMS_MV,BMS_NV,DCDC_800V_PAG,DCDC_HV,DCDC_HV_02,DCDC_IHEV,Gateway,Gateway_PAG,Ladegeraet_2,Ladegeraet_Konzern,LE1,LE_MLBevo,Sub_Gateway,TME
 SG_ NM_Sekundaer_01_CBV_AWB : 12|1@1+ (1,0) [0|1] ""  Gateway
 SG_ NM_Sekundaer_01_CBV_CRI : 14|1@1+ (1,0) [0|1] ""  AWC,BMC_MLBevo,BMS_MV,BMS_NV,DCDC_800V_PAG,DCDC_HV,DCDC_HV_02,DCDC_IHEV,Gateway,Gateway_PAG,Ladegeraet_2,Ladegeraet_Konzern,LE1,LE_MLBevo,Sub_Gateway,TME
 SG_ NM_Sekundaer_01_NM_State : 16|6@1+ (1,0) [0|63] "" Vector__XXX
 SG_ NM_Sekundaer_01_Car_Wakeup : 22|1@1+ (1,0) [0|1] ""  Gateway
 SG_ NM_Sekundaer_01_UDS_CC : 23|1@1+ (1,0) [0|1] "" Vector__XXX
 SG_ NM_Sekundaer_01_NM_aktiv_KL15 : 24|1@1+ (1,0) [0|1] "" Vector__XXX
 SG_ NM_Sekundaer_01_NM_aktiv_Diag : 25|1@1+ (1,0) [0|1] "" Vector__XXX
 SG_ NM_Sekundaer_01_NM_aktiv_Tmin : 26|1@1+ (1,0) [0|1] "" Vector__XXX
 SG_ NM_Sekundaer_01_NM_aktiv_Anf_HVK : 27|1@1+ (1,0) [0|1] "" Vector__XXX
 SG_ NM_Sekundaer_01_CAB : 40|24@1+ (1,0) [0|16777215] ""  AWC,BMC_MLBevo,BMS_MV,BMS_NV,DCDC_800V_PAG,DCDC_HV,DCDC_HV_02,DCDC_IHEV,Gateway,Gateway_PAG,Ladegeraet_2,Ladegeraet_Konzern,LE1,LE_MLBevo,Sub_Gateway,TME

BO_ 2600468483 NMH_Sekundaer_03: 8 LE1
 SG_ NM_Sekundaer_03_SNI : 0|8@1+ (1,0) [0|255] ""  AWC,BMC_MLBevo,BMS_MV,BMS_NV,DCDC_800V_PAG,DCDC_HV,DCDC_HV_02,DCDC_IHEV,Gateway,Gateway_PAG,Ladegeraet_2,Ladegeraet_Konzern,LE2,LE2_3_MLBevo_LB,Sub_Gateway,TME
 SG_ NM_Sekundaer_03_CBV_AWB : 12|1@1+ (1,0) [0|1] ""  Gateway,Gateway_PAG
 SG_ NM_Sekundaer_03_CBV_CRI : 14|1@1+ (1,0) [0|1] ""  AWC,BMC_MLBevo,BMS_MV,BMS_NV,DCDC_800V_PAG,DCDC_HV,DCDC_HV_02,DCDC_IHEV,Gateway,Gateway_PAG,Ladegeraet_2,Ladegeraet_Konzern,LE2,LE2_3_MLBevo_LB,Sub_Gateway,TME
 SG_ NM_Sekundaer_03_NM_State : 16|6@1+ (1,0) [0|63] "" Vector__XXX
 SG_ NM_Sekundaer_03_Car_Wakeup : 22|1@1+ (1,0) [0|1] "" Vector__XXX
 SG_ NM_Sekundaer_03_UDS_CC : 23|1@1+ (1,0) [0|1] "" Vector__XXX
 SG_ NM_Sekundaer_03_NM_aktiv_KL15 : 24|1@1+ (1,0) [0|1] "" Vector__XXX
 SG_ NM_Sekundaer_03_NM_aktiv_Diagnos : 25|1@1+ (1,0) [0|1] "" Vector__XXX
 SG_ NM_Sekundaer_03_NM_aktiv_Tmin : 26|1@1+ (1,0) [0|1] "" Vector__XXX
 SG_ NM_Sekundaer_03_NM_aktiv_Anf_HVK : 27|1@1+ (1,0) [0|1] "" Vector__XXX
 SG_ NM_Sekundaer_03_CAB : 40|24@1+ (1,0) [0|16777215] ""  AWC,BMC_MLBevo,BMS_MV,BMS_NV,DCDC_800V_PAG,DCDC_HV,DCDC_HV_02,DCDC_IHEV,Gateway,Gateway_PAG,Ladegeraet_2,Ladegeraet_Konzern,LE2,LE2_3_MLBevo_LB,Sub_Gateway,TME

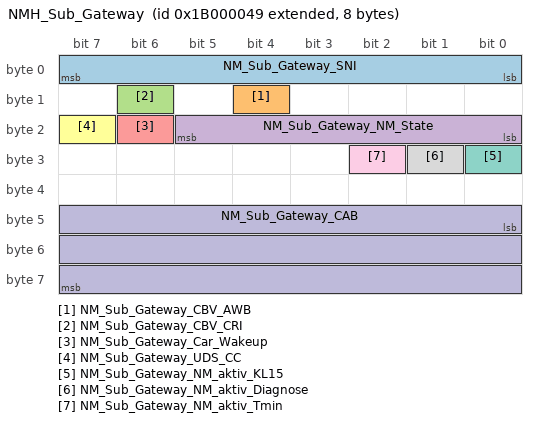
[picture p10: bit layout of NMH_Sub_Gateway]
BO_ 2600468553 NMH_Sub_Gateway: 8 Sub_Gateway
 SG_ NM_Sub_Gateway_SNI : 0|8@1+ (1,0) [0|255] ""  AWC,BMC_MLBevo,BMS_MV,BMS_NV,DCDC_800V_PAG,DCDC_HV,DCDC_HV_02,DCDC_IHEV,FCU_MLBevo_FCEV,Gateway,Ladegeraet_2,Ladegeraet_Konzern,LE1,LE2,LE2_3_MLBevo_LB,LE_MLBevo,TME
 SG_ NM_Sub_Gateway_CBV_AWB : 12|1@1+ (1,0) [0|1] ""  Gateway
 SG_ NM_Sub_Gateway_CBV_CRI : 14|1@1+ (1,0) [0|1] ""  AWC,BMC_MLBevo,BMS_MV,BMS_NV,DCDC_800V_PAG,DCDC_HV,DCDC_HV_02,DCDC_IHEV,FCU_MLBevo_FCEV,Gateway,Ladegeraet_2,Ladegeraet_Konzern,LE1,LE2,LE2_3_MLBevo_LB,LE_MLBevo,TME
 SG_ NM_Sub_Gateway_NM_State : 16|6@1+ (1,0) [0|63] "" Vector__XXX
 SG_ NM_Sub_Gateway_Car_Wakeup : 22|1@1+ (1,0) [0|1] ""  Gateway
 SG_ NM_Sub_Gateway_UDS_CC : 23|1@1+ (1,0) [0|1] "" Vector__XXX
 SG_ NM_Sub_Gateway_NM_aktiv_KL15 : 24|1@1+ (1,0) [0|1] "" Vector__XXX
 SG_ NM_Sub_Gateway_NM_aktiv_Diagnose : 25|1@1+ (1,0) [0|1] "" Vector__XXX
 SG_ NM_Sub_Gateway_NM_aktiv_Tmin : 26|1@1+ (1,0) [0|1] "" Vector__XXX
 SG_ NM_Sub_Gateway_CAB : 40|24@1+ (1,0) [0|16777215] ""  AWC,BMC_MLBevo,BMS_MV,BMS_NV,DCDC_800V_PAG,DCDC_HV,DCDC_HV_02,DCDC_IHEV,FCU_MLBevo_FCEV,Gateway,Ladegeraet_2,Ladegeraet_Konzern,LE1,LE2,LE2_3_MLBevo_LB,LE_MLBevo,TME

BO_TX_BU_ 339 : Gateway,Gateway_PAG;
BO_TX_BU_ 931 : Gateway,Gateway_PAG;
BO_TX_BU_ 2589283456 : Gateway,Gateway_PAG;
BO_TX_BU_ 1284 : Gateway,Gateway_PAG;
BO_TX_BU_ 1157 : Gateway,Gateway_PAG;
BO_TX_BU_ 1158 : Gateway,Gateway_PAG;
BO_TX_BU_ 2589283496 : Gateway,Gateway_PAG;
BO_TX_BU_ 2600468663 : DCDC_800V_PAG,DCDC_HV;
BO_TX_BU_ 2600468496 : Gateway,Gateway_PAG;
BO_TX_BU_ 2600468481 : LE2,LE2_3_MLBevo_LB;
BO_TX_BU_ 2600468483 : LE1,LE_MLBevo;
CM_ BO_ 339 "CAN-Botschaft";
CM_ SG_ 339 MSG_HYB_30_CRC "CRC für die Botschaft MSG_HYB_30";
CM_ SG_ 339 MSG_HYB_30_BZ "BZ für die Botschaft MSG_HYB_30
Botschaft asynchron geroutet. Zählerwert kann springen.";
CM_ SG_ 339 MO_HVEM_Eskalation "Eskalationsbit, mit diesem zusammen darf MO_HVEM_MaxLeistung < der minimal angeforderten Leistung sein und ist durch das HVEM durch Ergreifung aller Eskalationsmaßnahmen umzusetzen (Bei neg. Ladebilanz z.B. im Leerlauf nötig, um die HVBatt vor Entladung e";
CM_ SG_ 339 MO_ErwGrenzen_Anf "temporäre Anforderung erweiterter Leistungsgrenzen
0 = normaler Betrieb angefordert
1 = erweiterte Leistungsgrenzen angefordert
BMS und EMS liefern ggf. erweiterte Leistungsgrenzen, um VKM-Start auch unter schwierigen Bedingungen gewährleisten zu könne";
CM_ SG_ 339 MO_Fehler_Notentladung_Anf "Aufforderung zur schnellstmöglichen Entladeung des HV-Zwischenkreises aufgrund Crash-Erkennung / Abriss Pilotlinie";
CM_ SG_ 339 MO_HVEM_MaxLeistung "Maximal zulässige Leistung, die das HVEM einzustellen hat. 
Ohne Eskalationsbit ist diese Anforderung >= der Minimal benötigten Leistung des HVEM

Hinweis: Ehemaliger Fehlerwert 0x1FF wird senderseitig nicht unterstützt. Diesen Wert aus Kompatibilitäts";
CM_ SG_ 339 MO_HVK_EmIstzustand "Aktueller Istzustand der Elm_State
0 : HvOff              
1 : HvStbyReq          
2 : HvStbyOk         
3 : HvBattOnReq        
4 : HvBattOnOk       
10 : HvOnIdle          
18 : HvOnDrvReq        
19 : HvOnDrvOk       
20 : HvOnDrvRdy          ";
CM_ SG_ 339 MO_HVK_AntriebFehlerstatus "aktueller Fehlerstatus des Antriebs
0: Komponente IO (keine HVK relevanter Fehler)
1 - 5: reserve
6: Keine Komponentenfunktion (Aus)
7: Init";
CM_ SG_ 339 MO_MVK_Bordnetz_Anf "Explizite Anforderung des Motors zur Aktivierung bzw. Aufrechterhaltung des Mittelvolt-Bordnetzes für die Ausführung von Motorfunktionen";
CM_ SG_ 339 MO_HVK_AntriebZustand "Aktueller Zustand des Antriebs:
0 : Antrieb_AUS               
1 : Antrieb_Startphase        
2 : E-Fahren                  
3 : Hybrid-Fahren             
4 : reserve                   
5 : reserve                   
6 : Keine_Komponentenfunktion ";
CM_ SG_ 339 MO_HVK_EmFehlerstatus "aktueller Fehlerstatus des elektrischen Antriebes (E-Maschine und PWR)

0: Komponente IO (keine HVK relevanter Fehler)
1: Eingeschränkter Betrieb wg. Teilbetrieb
2: reserve
3: Eingeschr_KompFkt_Interlock
4 - 5: reserve
6: Keine Komponentenfunktion ";
CM_ SG_ 339 MO_MVK_AntriebFehlerstatus "aktueller Fehlerstatus des Antriebs
0: Komponente IO (keine MVK relevanter Fehler)
1 - 5: reserve
6: Keine Komponentenfunktion (Aus)
7: Init";
CM_ SG_ 339 MO_MVK_AntriebZustand "Aktueller Zustand des Antriebs:
0 : Antrieb_AUS               
1 : Antrieb_Startphase        
2 : FreilaufMotorAus                  
3 : reserve             
4 : reserve                   
5 : reserve                   
6 : Keine_Komponentenfunktio";
CM_ SG_ 339 MO_MVK_EmFehlerstatus "aktueller Fehlerstatus der elektrischen Maschine (RSG)

0: Komponente IO (keine MVK relevanter Fehler)
1: Eingeschränkter Betrieb wg. Teilbetrieb
2: reserve
3 - 5: reserve
6: Keine Komponentenfunktion (Aus)
7: Init";
CM_ SG_ 339 MO_MVK_EmIstzustand "Aktueller Istzustand der Elm_State
0 : MvOff              
1 : MvStbyReq          
2 : MvStbyOk         
3 : MvBattOnReq        
4 : MvBattOnOk       
10 : MvOnIdle          
18 : MvOnDrvReq        
19 : MvOnDrvOk       
20 : MvOnDrv           
";
CM_ SG_ 1434 TME_Dauer_Vorkond_innen "Geschätzte Dauer für die Vorkonditionierung";
CM_ SG_ 1434 TME_Eskalation "Anfrage um zusätzliche Leistung während des Ladens / Leistungsreduzierung des Komfortbereichs während der Fahrt zu erlauben ";
CM_ SG_ 1434 TME_Leistungsanf_ThermoKuehlen "Leistungsanforderung Thermomanagement für das Kühlen von Komponenten";
CM_ SG_ 1434 TME_Leistungsanf_ThermoHeizen "Leistungsanforderung Thermomanagement für das Heizen von Komponenten";
CM_ SG_ 1434 TME_Leistungsanf_Komfort "Leistungsanforderung für den Komfort-Bereich (Innenraum kühlen/heizen)";
CM_ SG_ 1434 KL_IstLeistung "Gesamt-Ist-Leistung für Komfort- und Thermomanagement";
CM_ SG_ 689 TME_PlanAntw_Zaehler "TME Antwort-Zähler der Ladeplan-Anfragen des ILF";
CM_ SG_ 689 TME_Verbrauch_gesamt_Ueberlauf "Überlauf-Bit für das Signal TME_Verbrauch_gesamt";
CM_ SG_ 689 TME_Verbrauch_gesamt "Energieverbrauch vom TME für Komfort- und Thermo-Bereich";
CM_ SG_ 689 TME_Energie_Thermo "Energieverbrauch für die Temperierung der Bauteile (beim Laden)";
CM_ SG_ 689 TME_Energie_Komfort "Energieverbrauch für die Vorkonditionierung des Innenraums (beim Laden)";
CM_ SG_ 931 MVEM_MO_RSG_Startleistung "Verfügbare Leistungvorgabe von MVEM an MSG:
Leistungsvorgabe für Freigabe Start-Stopp und Freilaufmotor-Aus";
CM_ SG_ 931 MVEM_Umin_Funktionsgruppe_C_02 "Systeme der Funktionsgruppe C müssen bei Unterschreitung der Spannungsgrenze ihren Leistungsbedarf dynamisch abregeln.";
CM_ SG_ 931 MVEM_IstStrom_MVVerbraucher "Iststrom-Aufnahme der 48V-Verbraucher (inkl 48V-DC/DC-Wandler) im 48V-Netz

Verbrauch - positiv
Rückspeisung - negativ";
CM_ SG_ 931 MVEM_DC_SollSpannung_MV "Soll-Ausgangspannung des DC/DC-Wandlers MV-Spannungssseitig (48V-seitig).";
CM_ SG_ 931 MVEM_DC_SollLeistung_MV "Soll-Leistung des DC/DC-Wandlers Höherspannungsseitig (48V-seitig).

Hochsetzen - negativ";
CM_ SG_ 931 MVEM_EMG_MaxGenStrom "Maximaler Strom des RSGs im spannungsgeregeltem Betrieb. ";
CM_ SG_ 931 MVEM_EMG_MaxGenSpannung "max. Spannung des 48V-RSG im generatorischen Betrieb.";
CM_ SG_ 2589283456 MVEM_MO_Sollspannung_Notbetrieb "Im eingeschränkten Betrieb des 48V Systems und Fehlerfälle der 48V Batterie.";
CM_ SG_ 2589283456 MVEM_Umax_Rueckspeisung "Systeme, die rückspeisefähig sind, müssen vor Erreichen der oberen Spannungsgrenze ihren Leistungsbedarf dynamisch abregeln.";
CM_ SG_ 2589283456 MVEM_Umin_Funktionsgruppe_C "Systeme der Funktionsgruppe C müssen bei Unterschreitung der Spannungsgrenze ihren Leistungsbedarf dynamisch abregeln.";
CM_ SG_ 2589283456 MVEM_Umin_Funktionsgruppe_B "Systeme der Funktionsgruppe B müssen bei Unterschreitung der Spannungsgrenze ihren Leistungsbedarf dynamisch abregeln.";
CM_ SG_ 2589283456 MVEM_Umin_Funktionsgruppe_A "Systeme der Funktionsgruppe A müssen bei Unterschreitung der Spannungsgrenze ihren Leistungsbedarf dynamisch abregeln.";
CM_ SG_ 1284 MVK_01_CRC "Für MLB:
Berechnung siehe Lastenheft 'Kommunikationsabsicherung für FlexRay und CAN'
Ab MQB und MLBevo:
Berechnung siehe Lastenheft 'End-to-End Kommunikationsabsicherung'

Endwerte siehe Begleitdokument 'S-PDU Kennungsfolgen'";
CM_ SG_ 1284 MVK_01_BZ "4bit Botschaftszähler, wird mit jeder Sendebotschaft inkrementiert";
CM_ SG_ 1284 MVK_DCDC_Sollmodus_02 "Angeforderte Soll-Betriebsart des 48V DC/DC-Wandlers: 
0: Standby; Kommunikation aktiv
1: MvOn (48V-Netz ist aktiv)
2: Tiefsetzen (48V --> BN12)
3: Hochsetzen (BN12 --> 48V)
4: Startunterstuetzung_48V (Stützung des 48V-BN im Startvorgang)
5: nicht v";
CM_ SG_ 1284 MV_Bordnetz_aktiv "Signalisiert ein aktives MV-Bordnetz. MV-Schütze geschlossen. Im Fehlerfall wird das Bit nicht gesetzt.(Klemmende Schütze)";
CM_ SG_ 1284 MVK_BOOST_Sollmodus "Sollmodus eBooster auf 48V
0 : keine Freigabe
1 : Freigabe
2 : nicht belegbar
3 : nicht belegbar
4 : nicht belegbar
5 : nicht belegbar
6 : nicht belegbar
7 : Init   (CAN-Initialisierung)   

Info: 'nicht belegbar' d.h. Sollmodus nicht relevant f";
CM_ SG_ 1284 MVK_eABC_Sollmodus "Sollmodus eABC auf 48V
0 : keine Freigabe
1 : Freigabe
2 : nicht belegbar
3 : nicht belegbar
4 : nicht belegbar
5 : nicht belegbar
6 : nicht belegbar
7 : Init   (CAN-Initialisierung)   

Info: 'nicht belegbar' d.h. Sollmodus nicht relevant für M";
CM_ SG_ 1284 MVK_eAWS_Sollmodus "Sollmodus eAWS auf 48V
0 : keine Freigabe
1 : Freigabe
2 : nicht belegbar
3 : nicht belegbar
4 : nicht belegbar
5 : nicht belegbar
6 : nicht belegbar
7 : Init   (CAN-Initialisierung)   

Info: 'nicht belegbar' d.h. Sollmodus nicht relevant für M";
CM_ SG_ 1284 MV_Bordnetz_Fehler "Status ob im  MV-Netz ein Fehler detektiert wurde.";
CM_ SG_ 1284 MVK_MVPTC_Sollmodus "Sollmodus MV-PTC
0 : keine Freigabe
1 : Freigabe
2 : nicht belegbar
3 : nicht belegbar
4 : nicht belegbar
5 : nicht belegbar
6 : nicht belegbar
7 : Init   (CAN-Initialisierung)   

Info: 'nicht belegbar' d.h. Sollmodus nicht relevant für MVK";
CM_ SG_ 1284 MVK_Istmodus_Anf "MVK-Anforderung an alle 48V-Komponenten deren Istmodus im schnellen Zyklus (Inhibitzeit) zu senden.";
CM_ SG_ 1284 MVK_MO_EmSollzustand "Anforderung vom MVK Sollzustand der Elm_State
0 = MvOff              
1 = MvStbyReq          
2 = MvStbyWait         
3 = MvBattOnReq        
4 = MvBattOnWait       
10 = MvOnIdle          
18 = MvOnDrvReq        
19 = MvOnDrvWait       
20 = MvO";
CM_ SG_ 1284 MVK_BMS_Sollmodus "Angeforderter Sollmodus der MV-Batterie:
0 : MV_Off                                
1 : MV_On (HS geschlossen)                
2 : nicht belegbar                        
3 : nicht belegbar                        
4 : nicht belegbar 
5 : nicht belegb";
CM_ SG_ 1284 MVK_DCDC_Sollmodus "angeforderte Soll-Betriebsart des 48V DC/DC-Wandlers: 
0: Standby; Kommunikation aktiv
1: MvOn (48V-Netz ist aktiv)
2: Tiefsetzen (48V --> BN 14,4V)
3: Hochsetzen (BN 14,4V --> 48V)
4: Startunterstuetzung_48V (Stützung des 48V-BN im Startvorgang)
5:";
CM_ SG_ 1284 MVK_MV_Netz_Warnungen "Anforderung Warnung/Fehler MV-System im Kombi
0: Keine Warnung/Init
1:Anforderung_Anzeige_Warnung_MV-Netz (gelbes Symbol)
2:Anforderung_Anzeige_Fehler_MV-Netz (rotes Symbol)
3:Anforderung_Anzeige_Warnung_Kein_Wiederstart_möglich";
CM_ SG_ 1157 ND_SatInUse "Anzahl der zur Berechnung verwendeten Satelliten";
CM_ SG_ 1157 POS_Guete_horizontal_verfuegbar "Bei gesetztem Bit wird das Signal POS_Guete_horizontal befüllt und ist verfügbar.";
CM_ SG_ 1157 ND_SatInView "Anzahl der sichtbaren Satelliten";
CM_ SG_ 1157 POS_Guete_horizontal "Horizontale Genauigkeit der Position in der Botschaft NavPos_02_MapMatched (Signale
POS_LatDegree, POS_LongDegree)

Abhängig vom Signal
POS_Guete_horizontal_verfuegbar";
CM_ SG_ 1157 NP_Altitude "Hoehe ueber NN
0xFFF = Fehler bei der Berechnung der Höhe über NN";
CM_ SG_ 1157 ND_UTC "UTC-Zeit, verstrichene Sekunden seit 01.01.1970 00:00
0xFFFFFFFE = Init
0xFFFFFFFF = Fehler bei Berechnung der UTC-Time";
CM_ SG_ 1158 NP_LatDegree "Latitude (Nord-Süd Wert)";
CM_ SG_ 1158 NP_LongDegree "Longitude (Ost-West Wert)";
CM_ SG_ 1158 NP_LatDirection "Hemisphäre Nord/Süd";
CM_ SG_ 1158 NP_LongDirection "Hemisphäre Ost/West";
CM_ SG_ 1158 NP_Sat "Nummer der verwendeten Sateliten beim letzten Fix";
CM_ SG_ 2589283496 POS_MUX "Multiplex-Signal zum schalten des Signals der Positionen von der Navigation.
MUX(0/1)";
CM_ SG_ 2589283496 POS_ODD_EVEN "Synchronisation der MUX Pos Signale
MUX(0/1)";
CM_ SG_ 2589283496 POS_PosStati "Aktueller Status der Navgation:
MUX(0)
0   init
1   no nav available (ready_4_nav)
2   no map available (sd_removed, not_enabled)
3   nav booting
4   nav error
5   nav calibrating
6   nav no gps resync since 1h
7   nav offroad  parkgarage ramp of";
CM_ SG_ 2589283496 POS_Heading "Heading of current position
MUX(1)";
CM_ SG_ 2589283496 POS_LatDirection "latitude direction nav position
MUX(0)";
CM_ SG_ 2589283496 POS_LatDegree "latitude - position data of navigation
MUX(0)";
CM_ SG_ 2589283496 POS_Last_GPS_Sync "Letztes bekannte GPS Sync in [s]
MUX(1)";
CM_ SG_ 2589283496 POS_Heading_Trust "Vertrauenswert Heading 
MUX(1) ";
CM_ SG_ 2589283496 POS_UTC_REF "Zeitstempel der Nav
MUX(1)

UTC-Zeit, verstrichene Sekunden seit 01.01.1970 00:00
0xFFFFFFFE = Init
0xFFFFFFFF = Fehler bei Berechnung der UTC-Time

Signal wird nur bei aktiver Navigation-Funktion zyklisch gesendet.";
CM_ SG_ 2589283496 POS_LongDirection "longitude direction nav position
MUX(0)";
CM_ SG_ 2589283496 POS_LongDegree "long - position data of navigation
MUX(0)";
CM_ SG_ 2600468623 NM_AWC_SNI "Source Node-Identifier (SNI) identifiziert den Sender der NM-Botschaft (Knotenadresse) eindeutig im Fahrzeug";
CM_ SG_ 2600468623 NM_AWC_CBV_AWB "Das Signal ist zu setzen, wenn das SG aktiv den Bus geweckt hat";
CM_ SG_ 2600468623 NM_AWC_CBV_CRI "Das Signal ist dauerhaft gesetzt, wenn das NM-Layout dem neuen NM-Layout für Teilnetzbetrieb entspricht";
CM_ SG_ 2600468623 NM_AWC_NM_State "1 = Zustand Repeat Message (<-- Bus-Sleep Mode)
2 = Zustand Repeat Message (<-- Prepare Bus-Sleep Mode)
4 = Zustand Normal Operation (<-- Repeat Message)
8 = Zustand Normal Operation (<-- Ready Sleep)
16 = Zustand Repeat Message (<-- Ready Sleep)
32 ";
CM_ SG_ 2600468623 NM_AWC_Car_Wakeup "Car Wakeup (Gateway wertet aus)";
CM_ SG_ 2600468623 NM_AWC_UDS_CC "Funktionseinschränkung aufgrund aktivem UDS-Communication Control; siehe VW80124";
CM_ SG_ 2600468623 NM_AWC_NM_aktiv_KL15 "Steuergeraet hat KL15-EIN erkannt";
CM_ SG_ 2600468623 NM_AWC_NM_aktiv_Diagnose "Diagnose befindet sich nach VW80124 in einer NonDefaultDiagnostic-Session, z.B. ExtendedDiagnostic-Session";
CM_ SG_ 2600468623 NM_AWC_NM_aktiv_Tmin "Mindestaktivzeit ist noch nicht abgelaufen (bei jedem Weckereignis wird die Mindestaktivzeit neu gestartet)";
CM_ SG_ 2600468623 NM_AWC_CAB "CAB = Clusteraktivbits";
CM_ SG_ 2600468654 NM_BattRegelung_SNI "Source Node-Identifier (SNI) identifiziert den Sender der NM-Botschaft (Knotenadresse) eindeutig im Fahrzeug";
CM_ SG_ 2600468654 NM_BattRegelung_CBV_AWB "Das Signal ist zu setzen, wenn das SG aktiv den Bus geweckt hat";
CM_ SG_ 2600468654 NM_BattRegelung_CBV_CRI "Das Signal ist dauerhaft gesetzt, wenn das NM-Layout dem neuen NM-Layout für Teilnetzbetrieb entspricht";
CM_ SG_ 2600468654 NM_Battregelung_NM_State "1 = Zustand Repeat Message (<-- Bus-Sleep Mode)
2 = Zustand Repeat Message (<-- Prepare Bus-Sleep Mode)
4 = Zustand Normal Operation (<-- Repeat Message)
8 = Zustand Normal Operation (<-- Ready Sleep)";
CM_ SG_ 2600468654 NM_BattRegelung_Car_Wakeup "Car Wakeup (Gateway wertet aus)";
CM_ SG_ 2600468654 NM_BattRegelung_UDS_CC "Funktionseinschränkung aufgrund aktivem UDS-Communication Control; siehe VW80124";
CM_ SG_ 2600468654 NM_BattRegelung_NM_aktiv_KL15 "Steuergerät hat KL15-EIN erkannt";
CM_ SG_ 2600468654 NM_BattRegelungNM_aktiv_Diagnose "Diagnose befindet sich nach VW80124 in einer NonDefaultDiagnostic-Session, z.B. ExtendedDiagnostic-Session";
CM_ SG_ 2600468654 NM_BattRegelung_NM_aktiv_Tmin "Mindestaktivzeit ist noch nicht abgelaufen (bei jedem Weckereignis wird die Mindestaktivzeit neu gestartet)";
CM_ SG_ 2600468654 NM_BattRegelung_NM_aktiv_NV "Niedervoltspeicher_angefordert";
CM_ SG_ 2600468654 NM_BattRegelung_CAB "CAB = Clusteraktivbits";
CM_ SG_ 2600468636 NM_BMS_48V_SNI "Source Node-Identifier (SNI) identifiziert den Sender der NM-Botschaft (Knotenadresse) eindeutig im Fahrzeug";
CM_ SG_ 2600468636 NM_BMS_48V_CBV_AWB "Das Signal ist zu setzen, wenn das SG aktiv den Bus geweckt hat";
CM_ SG_ 2600468636 NM_BMS_48V_CBV_CRI "Das Signal ist dauerhaft gesetzt, wenn das NM-Layout dem neuen NM-Layout für Teilnetzbetrieb entspricht";
CM_ SG_ 2600468636 NM_BMS_48V_NM_State "1 = Zustand Repeat Message (<-- Bus-Sleep Mode)
2 = Zustand Repeat Message (<-- Prepare Bus-Sleep Mode)
4 = Zustand Normal Operation (<-- Repeat Message)
8 = Zustand Normal Operation (<-- Ready Sleep)";
CM_ SG_ 2600468636 NM_BMS_48V_Car_Wakeup "Car Wakeup (Gateway wertet aus)";
CM_ SG_ 2600468636 NM_BMS_48V_UDS_CC "Funktionseinschraenkung aufgrund aktivem UDS-Communication Control; siehe VW80124";
CM_ SG_ 2600468636 NM_BMS_48V_NM_aktiv_KL15 "Steuergeraet hat KL15-EIN erkannt";
CM_ SG_ 2600468636 NM_BMS_48V_NM_aktiv_Diagnose "Diagnose befindet sich nach VW80124 in einer NonDefaultDiagnostic-Session, z.B. ExtendedDiagnostic-Session";
CM_ SG_ 2600468636 NM_BMS_48V_NM_aktiv_Tmin "Mindestaktivzeit ist noch nicht abgelaufen (bei jedem Weckereignis wird die Mindestaktivzeit neu gestartet)";
CM_ SG_ 2600468636 NM_BMS_48V_NM_aktiv_Hochvolt "Hochvolt aktiv";
CM_ SG_ 2600468636 NM_BMS_48V_CAB "CAB = Clusteraktivbits";
CM_ SG_ 2600468545 NM_DCDC_SNI "Source Node-Identifier (SNI) identifiziert den Sender der NM-Botschaft (Knotenadresse) eindeutig im Fahrzeug";
CM_ SG_ 2600468545 NM_DCDC_CBV_AWB "Das Signal ist zu setzen, wenn das SG aktiv den Bus geweckt hat";
CM_ SG_ 2600468545 NM_DCDC_CBV_CRI "Das Signal ist dauerhaft gesetzt, wenn das NM-Layout dem neuen NM-Layout für Teilnetzbetrieb entspricht";
CM_ SG_ 2600468545 NM_DCDC_NM_State "1 = Zustand Repeat Message (<-- Bus-Sleep Mode)
2 = Zustand Repeat Message (<-- Prepare Bus-Sleep Mode)
4 = Zustand Normal Operation (<-- Repeat Message)
8 = Zustand Normal Operation (<-- Ready Sleep)
16 = Zustand Repeat Message (<-- Ready Sleep)
32 ";
CM_ SG_ 2600468545 NM_DCDC_Car_Wakeup "Car Wakeup (Gateway wertet aus)
";
CM_ SG_ 2600468545 NM_DCDC_UDS_CC "Funktionseinschränkung aufgrund aktivem UDS-Communication Control; siehe VW80124";
CM_ SG_ 2600468545 NM_DCDC_NM_aktiv_KL15 "Steuergerät hat KL15-EIN erkannt";
CM_ SG_ 2600468545 NM_DCDC_NM_aktiv_Diagnose "Diagnose befindet sich nach VW80124 in einer NonDefaultDiagnostic-Session, z.B. ExtendedDiagnostic-Session";
CM_ SG_ 2600468545 NM_DCDC_NM_aktiv_Tmin "Mindestaktivzeit ist noch nicht abgelaufen (bei jedem Weckereignis wird die Mindestaktivzeit neu gestartet)";
CM_ SG_ 2600468545 NM_DCDC_NM_aktiv_Anf_MVK "Anforderung MVK (Nachlaufursache, SG nicht im NM-Zustand 'Ready to Sleep')";
CM_ SG_ 2600468545 NM_DCDC_CAB "CAB = Clusteraktivbits";
CM_ SG_ 2600468663 NM_DCDC_HV_SNI "Source Node-Identifier (SNI) identifiziert den Sender der NM-Botschaft (Knotenadresse) eindeutig im Fahrzeug";
CM_ SG_ 2600468663 NM_DCDC_HV_CBV_AWB "Das Signal ist zu setzen, wenn das SG aktiv den Bus geweckt hat";
CM_ SG_ 2600468663 NM_DCDC_HV_CBV_CRI "Das Signal ist dauerhaft gesetzt, wenn das NM-Layout dem neuen NM-Layout für Teilnetzbetrieb entspricht";
CM_ SG_ 2600468663 NM_DCDC_HV_NM_State "1 = Zustand Repeat Message (<-- Bus-Sleep Mode)
2 = Zustand Repeat Message (<-- Prepare Bus-Sleep Mode)
4 = Zustand Normal Operation (<-- Repeat Message)
8 = Zustand Normal Operation (<-- Ready Sleep)";
CM_ SG_ 2600468663 NM_DCDC_HV_Car_Wakeup "Car Wakeup (Gateway wertet aus)";
CM_ SG_ 2600468663 NM_DCDC_HV_UDS_CC "Funktionseinschränkung aufgrund aktivem UDS-Communication Control; siehe VW80124";
CM_ SG_ 2600468663 NM_DCDC_HV_NM_aktiv_KL15 "Steuergerät hat KL15-EIN erkannt";
CM_ SG_ 2600468663 NM_DCDC_HV_NM_aktiv_Diagnose "Diagnose befindet sich nach VW80124 in einer NonDefaultDiagnostic-Session, z.B. ExtendedDiagnostic-Session";
CM_ SG_ 2600468663 NM_DCDC_HV_NM_aktiv_Tmin "Mindestaktivzeit ist noch nicht abgelaufen (bei jedem Weckereignis wird die Mindestaktivzeit neu gestartet)";
CM_ SG_ 2600468663 NM_DCDC_HV_NM_aktiv_Anf_HVK "Anforderung HVK (Nachlaufursache, SG nicht im NM-Zustand 'Ready to Sleep')";
CM_ SG_ 2600468663 NM_DCDC_HV_CAB "CAB = Clusteraktivbits";
CM_ SG_ 2600468679 NM_DCDC_HV_02_SNI "Source Node-Identifier (SNI) identifiziert den Sender der NM-Botschaft (Knotenadresse) eindeutig im Fahrzeug";
CM_ SG_ 2600468679 NM_DCDC_HV_02_CBV_AWB "Das Signal ist zu setzen, wenn das SG aktiv den Bus geweckt hat";
CM_ SG_ 2600468679 NM_DCDC_HV_02_CBV_CRI "Das Signal ist dauerhaft gesetzt, wenn das NM-Layout dem neuen NM-Layout für Teilnetzbetrieb entspricht";
CM_ SG_ 2600468679 NM_DCDC_HV_02_NM_State "1 = Zustand Repeat Message (<-- Bus-Sleep Mode)
2 = Zustand Repeat Message (<-- Prepare Bus-Sleep Mode)
4 = Zustand Normal Operation (<-- Repeat Message)
8 = Zustand Normal Operation (<-- Ready Sleep)";
CM_ SG_ 2600468679 NM_DCDC_HV_02_Car_Wakeup "Car Wakeup (Gateway wertet aus)";
CM_ SG_ 2600468679 NM_DCDC_HV_02_UDS_CC "Funktionseinschränkung aufgrund aktivem UDS-Communication Control; siehe VW80124";
CM_ SG_ 2600468679 NM_DCDC_HV_02_NM_aktiv_KL15 "Steuergerät hat KL15-EIN erkannt";
CM_ SG_ 2600468679 NM_DCDC_HV_02_NM_aktiv_Diag "Diagnose befindet sich nach VW80124 in einer NonDefaultDiagnostic-Session, z.B. ExtendedDiagnostic-Session";
CM_ SG_ 2600468679 NM_DCDC_HV_02_NM_aktiv_Tmin "Mindestaktivzeit ist noch nicht abgelaufen (bei jedem Weckereignis wird die Mindestaktivzeit neu gestartet)";
CM_ SG_ 2600468679 NM_DCDC_HV_02_NM_aktiv_Anf_HVK "Anforderung HVK (Nachlaufursache, SG nicht im NM-Zustand 'Ready to Sleep')";
CM_ SG_ 2600468679 NM_DCDC_HV_02_CAB "CAB = Clusteraktivbits";
CM_ SG_ 2600468661 NM_FCU_SNI "Source Node-Identifier (SNI) identifiziert den Sender der NM-Botschaft (Knotenadresse) eindeutig im Fahrzeug";
CM_ SG_ 2600468661 NM_FCU_CBV_AWB "Das Signal ist zu setzen, wenn das SG aktiv den Bus geweckt hat";
CM_ SG_ 2600468661 NM_FCU_CBV_CRI "Das Signal ist dauerhaft gesetzt, wenn das NM-Layout dem neuen NM-Layout für Teilnetzbetrieb entspricht";
CM_ SG_ 2600468661 NM_FCU_NM_State "1 = Zustand Repeat Message (<-- Bus-Sleep Mode)
2 = Zustand Repeat Message (<-- Prepare Bus-Sleep Mode)
4 = Zustand Normal Operation (<-- Repeat Message)
8 = Zustand Normal Operation (<-- Ready Sleep)";
CM_ SG_ 2600468661 NM_FCU_Car_Wakeup "Car Wakeup (Gateway wertet aus)";
CM_ SG_ 2600468661 NM_FCU_UDS_CC "Funktionseinschränkung aufgrund aktivem UDS-Communication Control; siehe VW80124";
CM_ SG_ 2600468661 NM_FCU_NM_aktiv_KL15 "Steuergerät hat KL15-EIN erkannt";
CM_ SG_ 2600468661 NM_FCU_NM_aktiv_Diag "Diagnose befindet sich nach VW80124 in einer NonDefaultDiagnostic-Session, z.B. ExtendedDiagnostic-Session";
CM_ SG_ 2600468661 NM_FCU_NM_aktiv_Tmin "Mindestaktivzeit ist noch nicht abgelaufen (bei jedem Weckereignis wird die Mindestaktivzeit neu gestartet)";
CM_ SG_ 2600468661 NM_FCU_NM_aktiv_Shutdown "Beim Shutdown muss die Restenergie im System abgebaut werden. Bei kalten Temperaturen muss davor zunächst die Zelle getrocknet werden.";
CM_ SG_ 2600468661 NM_FCU_NM_aktiv_HCAN "Buskopplung - SubCAN aktiv wenn Hauptbus (HCAN) aktiv";
CM_ SG_ 2600468661 NM_FCU_NM_aktiv_Tankvorgang "Busnachlauf aufgrund aktivem Tankvorgang oder Tankvorbereitung";
CM_ SG_ 2600468661 NM_FCU_CAB "CAB = Clusteraktivbits";
CM_ SG_ 2600468496 NM_Gateway_SNI "Source Node-Identifier (SNI) identifiziert den Sender der NM-Botschaft (Knotenadresse) eindeutig im Fahrzeug";
CM_ SG_ 2600468496 NM_Gateway_CBV_AWB "Das Signal ist zu setzen, wenn das SG aktiv den Bus geweckt hat";
CM_ SG_ 2600468496 NM_Gateway_CBV_CRI "Das Signal ist dauerhaft gesetzt, wenn das NM-Layout dem neuen NM-Layout für Teilnetzbetrieb entspricht";
CM_ SG_ 2600468496 NM_Gateway_NM_State "1 = Zustand Repeat Message (<-- Bus-Sleep Mode)
2 = Zustand Repeat Message (<-- Prepare Bus-Sleep Mode)
4 = Zustand Normal Operation (<-- Repeat Message)
8 = Zustand Normal Operation (<-- Ready Sleep)
16 = Zustand Repeat Message (<-- Ready Sleep)
32 ";
CM_ SG_ 2600468496 NM_Gateway_Car_Wakeup "Car Wakeup (Subbusmaster wertet aus)

MQB: 
-Diagnose- oder Komponentenschutzmaster-Funktion weckt den schlafenden Subbus (z.B. MOST)

E3_1_1:
- Diagnose aktiv -aktive Diagnosekommunikation am OBD-Stecker

E3_1_2:
- Diagnose aktiv -aktive Diagnos";
CM_ SG_ 2600468496 NM_Gateway_UDS_CC "Funktionseinschränkung aufgrund aktivem UDS-Communication Control; siehe VW80124";
CM_ SG_ 2600468496 NM_Gateway_NM_aktiv_KL15 "Steuergerät hat KL15-EIN erkannt";
CM_ SG_ 2600468496 NM_Gateway_NM_aktiv_Diagnose "Diagnose befindet sich nach VW80124 in einer NonDefaultDiagnostic-Session, z.B. ExtendedDiagnostic-Session";
CM_ SG_ 2600468496 NM_Gateway_NM_aktiv_Tmin "Mindestaktivzeit ist noch nicht abgelaufen (bei jedem Weckereignis wird die Mindestaktivzeit neu gestartet)";
CM_ SG_ 2600468496 NM_Gateway_NM_aktiv_CWU "Nachlauf aufgrund CWU Anforderung";
CM_ SG_ 2600468496 NM_Gateway_NM_aktiv_FC "Nachlauf aufgrund Funktionscluster Anforderung";
CM_ SG_ 2600468496 NM_Gateway_NM_aktiv_Connect "Nachlauf aufgrund Connect";
CM_ SG_ 2600468496 NM_Gateway_NM_aktiv_EM "Nachlauf aufgrund Energiemanagement";
CM_ SG_ 2600468496 NM_Gateway_NM_aktiv_OBDC "Nachlauf aufgrund OBDC";
CM_ SG_ 2600468496 NM_Gateway_NM_aktiv_Buskopplung "Nachlauf aufgrund Kopplung zweier Busse. z.B. K-CAN und K2-CAN";
CM_ SG_ 2600468496 NM_Gateway_NM_aktiv_LIN2 "Bus aktiv aufgrund aktivem LIN2 (Hupe betätigt)";
CM_ SG_ 2600468496 NM_Gateway_CAB "CAB = Clusteraktivbits";
CM_ SG_ 2600468603 NM_Hybrid_01_SNI "Source Node-Identifier (SNI) identifiziert den Sender der NM-Botschaft (Knotenadresse) eindeutig im Fahrzeug";
CM_ SG_ 2600468603 NM_Hybrid_01_CBV_AWB "Das Signal ist zu setzen, wenn das SG aktiv den Bus geweckt hat";
CM_ SG_ 2600468603 NM_Hybrid_01_CBV_CRI "Das Signal ist dauerhaft gesetzt, wenn das NM-Layout dem neuen NM-Layout für Teilnetzbetrieb entspricht";
CM_ SG_ 2600468603 NM_Hybrid_01_NM_State "1 = Zustand Repeat Message (<-- Bus-Sleep Mode)
2 = Zustand Repeat Message (<-- Prepare Bus-Sleep Mode)
4 = Zustand Normal Operation (<-- Repeat Message)
8 = Zustand Normal Operation (<-- Ready Sleep)";
CM_ SG_ 2600468603 NM_Hybrid_01_Car_Wakeup "Car Wakeup (Gateway wertet aus)
";
CM_ SG_ 2600468603 NM_Hybrid_01_UDS_CC "Funktionseinschränkung aufgrund aktivem UDS-Communication Control; siehe VW80124";
CM_ SG_ 2600468603 NM_Hybrid_01_NM_aktiv_KL15 "Steuergerät hat KL15-EIN erkannt";
CM_ SG_ 2600468603 NM_Hybrid_01_NM_aktiv_Diagnose "Diagnose befindet sich nach VW80124 in einer NonDefaultDiagnostic-Session, z.B. ExtendedDiagnostic-Session";
CM_ SG_ 2600468603 NM_Hybrid_01_NM_aktiv_Tmin "Mindestaktivzeit ist noch nicht abgelaufen (bei jedem Weckereignis wird die Mindestaktivzeit neu gestartet)";
CM_ SG_ 2600468603 NM_Hybrid_01_NM_aktiv_Hochvolt "Hochvolt aktiv";
CM_ SG_ 2600468603 NM_BMC_NM_aktiv_HCAN "BMC-Subcan wird wachhgehalten, solange H-CAN aktiv ist.";
CM_ SG_ 2600468603 NM_Hybrid_01_CAB "CAB = Clusteraktivbits";
CM_ SG_ 2600468548 NM_Ladegeraet_SNI "Source Node-Identifier (SNI) identifiziert den Sender der NM-Botschaft (Knotenadresse) eindeutig im Fahrzeug";
CM_ SG_ 2600468548 NM_Ladegeraet_CBV_AWB "Das Signal ist zu setzen, wenn das SG aktiv den Bus geweckt hat";
CM_ SG_ 2600468548 NM_Ladegeraet_CBV_CRI "Das Signal ist dauerhaft gesetzt, wenn das NM-Layout dem neuen NM-Layout für Teilnetzbetrieb entspricht";
CM_ SG_ 2600468548 NM_Ladegeraet_NM_State "1 = Zustand Repeat Message (<-- Bus-Sleep Mode)
2 = Zustand Repeat Message (<-- Prepare Bus-Sleep Mode)
4 = Zustand Normal Operation (<-- Repeat Message)
8 = Zustand Normal Operation (<-- Ready Sleep)";
CM_ SG_ 2600468548 NM_Ladegeraet_Car_Wakeup "Car Wakeup (Gateway wertet aus)
MQB: Ladestecker gesteckt, entfernt, verriegelt oder entriegelt";
CM_ SG_ 2600468548 NM_Ladegeraet_UDS_CC "Funktionseinschränkung aufgrund aktivem UDS-Communication Control; siehe VW80124";
CM_ SG_ 2600468548 NM_Ladegeraet_NM_aktiv_KL15 "Steuergerät hat KL15-EIN erkannt";
CM_ SG_ 2600468548 NM_Ladegeraet_NM_aktiv_Diagnose "Diagnose befindet sich nach VW80124 in einer NonDefaultDiagnostic-Session, z.B. ExtendedDiagnostic-Session";
CM_ SG_ 2600468548 NM_Ladegeraet_NM_aktiv_Tmin "Mindestaktivzeit ist noch nicht abgelaufen (bei jedem Weckereignis wird die Mindestaktivzeit neu gestartet)";
CM_ SG_ 2600468548 NM_Ladegeraet_NM_aktiv_Bere_CVN "Aktiver Nachlauf aufgrund Berechnung des CVN, bei jedem Klemme 15 Wechsel von AUS-->AN 
Dauer ca. 30s";
CM_ SG_ 2600468548 NM_Ladegeraet_NM_aktiv_Vorkondit "Wachhalten aufgrund Vorkonditionierung";
CM_ SG_ 2600468548 NM_Ladegeraet_NM_aktiv_CVN_Berec "Berechnung CVN ist aktiv";
CM_ SG_ 2600468548 NM_Ladegeraet_NM_aktiv_NotlaufSt "Lokaler Nachlauf bei Kl15EIN durch aktivierten Notlauf bei gestecktem oder defekten Steckerkontakt";
CM_ SG_ 2600468548 NM_Ladegeraet_NM_aktiv_Ladezeit "Bus gefordert bei Ladezeitberechnung";
CM_ SG_ 2600468548 NM_Ladegeraet_NM_aktiv_Laden "Bus gefordert bei aktivem Ladevorgang";
CM_ SG_ 2600468548 NM_Ladegeraet_CAB "CAB = Clusteraktivbits";
CM_ SG_ 2600468678 NM_Ladegeraet_2_SNI "Source Node-Identifier (SNI) identifiziert den Sender der NM-Botschaft (Knotenadresse) eindeutig im Fahrzeug";
CM_ SG_ 2600468678 NM_Ladegeraet_2_CBV_AWB "Das Signal ist zu setzen, wenn das SG aktiv den Bus geweckt hat";
CM_ SG_ 2600468678 NM_Ladegeraet_2_CBV_CRI "Das Signal ist dauerhaft gesetzt, wenn das NM-Layout dem neuen NM-Layout für Teilnetzbetrieb entspricht";
CM_ SG_ 2600468678 NM_Ladegeraet_2_NM_State "1 = Zustand Repeat Message (<-- Bus-Sleep Mode)
2 = Zustand Repeat Message (<-- Prepare Bus-Sleep Mode)
4 = Zustand Normal Operation (<-- Repeat Message)
8 = Zustand Normal Operation (<-- Ready Sleep)";
CM_ SG_ 2600468678 NM_Ladegeraet_2_Car_Wakeup "Car Wakeup (Gateway wertet aus)
MQB: Ladestecker gesteckt, entfernt, verriegelt oder entriegelt";
CM_ SG_ 2600468678 NM_Ladegeraet_2_UDS_CC "Funktionseinschränkung aufgrund aktivem UDS-Communication Control; siehe VW80124";
CM_ SG_ 2600468678 NM_Ladegeraet_2_NM_aktiv_KL15 "Steuergerät hat KL15-EIN erkannt";
CM_ SG_ 2600468678 NM_Ladegeraet_2_NM_aktiv_Diag "Diagnose befindet sich nach VW80124 in einer NonDefaultDiagnostic-Session, z.B. ExtendedDiagnostic-Session";
CM_ SG_ 2600468678 NM_Ladegeraet_2_NM_aktiv_Tmin "Mindestaktivzeit ist noch nicht abgelaufen (bei jedem Weckereignis wird die Mindestaktivzeit neu gestartet)";
CM_ SG_ 2600468678 NM_Ladegeraet_2_NM_aktiv_Laden "Bus gefordert bei aktivem Ladevorgang";
CM_ SG_ 2600468678 NM_Ladegeraet_2_CAB "CAB = Clusteraktivbits";
CM_ SG_ 2600468481 NM_Sekundaer_01_SNI "Source Node-Identifier (SNI) identifiziert den Sender der NM-Botschaft (Knotenadresse) eindeutig im Fahrzeug";
CM_ SG_ 2600468481 NM_Sekundaer_01_CBV_AWB "Das Signal ist zu setzen, wenn das SG aktiv den Bus geweckt hat";
CM_ SG_ 2600468481 NM_Sekundaer_01_CBV_CRI "Das Signal ist dauerhaft gesetzt, wenn das NM-Layout dem neuen NM-Layout für Teilnetzbetrieb entspricht";
CM_ SG_ 2600468481 NM_Sekundaer_01_NM_State "1 = Zustand Repeat Message (<-- Bus-Sleep Mode)
2 = Zustand Repeat Message (<-- Prepare Bus-Sleep Mode)
4 = Zustand Normal Operation (<-- Repeat Message)
8 = Zustand Normal Operation (<-- Ready Sleep)
16 = Zustand Repeat Message (<-- Normal Operation)";
CM_ SG_ 2600468481 NM_Sekundaer_01_Car_Wakeup "Car Wakeup (Gateway wertet aus)";
CM_ SG_ 2600468481 NM_Sekundaer_01_UDS_CC "Funktionseinschränkung aufgrund aktivem UDS-Communication Control; siehe VW80124";
CM_ SG_ 2600468481 NM_Sekundaer_01_NM_aktiv_KL15 "Steuergerät hat KL15-EIN erkannt";
CM_ SG_ 2600468481 NM_Sekundaer_01_NM_aktiv_Diag "Diagnose befindet sich nach VW80124 in einer NonDefaultDiagnostic-Session, z.B. ExtendedDiagnostic-Session";
CM_ SG_ 2600468481 NM_Sekundaer_01_NM_aktiv_Tmin "Mindestaktivzeit ist noch nicht abgelaufen (bei jedem Weckereignis wird die Mindestaktivzeit neu gestartet)";
CM_ SG_ 2600468481 NM_Sekundaer_01_NM_aktiv_Anf_HVK "Anforderung HVK (Nachlaufursache, SG nicht im NM-Zustand 'Ready to Sleep')";
CM_ SG_ 2600468481 NM_Sekundaer_01_CAB "CAB = Clusteraktivbits";
CM_ SG_ 2600468483 NM_Sekundaer_03_SNI "Source Node-Identifier (SNI) identifiziert den Sender der NM-Botschaft (Knotenadresse) eindeutig im Fahrzeug";
CM_ SG_ 2600468483 NM_Sekundaer_03_CBV_AWB "Das Signal ist zu setzen, wenn das SG aktiv den Bus geweckt hat";
CM_ SG_ 2600468483 NM_Sekundaer_03_CBV_CRI "Das Signal ist dauerhaft gesetzt, wenn das NM-Layout dem neuen NM-Layout für Teilnetzbetrieb entspricht";
CM_ SG_ 2600468483 NM_Sekundaer_03_NM_State "1 = Zustand Repeat Message (<-- Bus-Sleep Mode)
2 = Zustand Repeat Message (<-- Prepare Bus-Sleep Mode)
4 = Zustand Normal Operation (<-- Repeat Message)
8 = Zustand Normal Operation (<-- Ready Sleep)
16 = Zustand Repeat Message (<-- Normal Operation)";
CM_ SG_ 2600468483 NM_Sekundaer_03_Car_Wakeup "Car Wakeup (Gateway wertet aus)";
CM_ SG_ 2600468483 NM_Sekundaer_03_UDS_CC "Funktionseinschränkung aufgrund aktivem UDS-Communication Control; siehe VW80124";
CM_ SG_ 2600468483 NM_Sekundaer_03_NM_aktiv_KL15 "Steuergerät hat KL15-EIN erkannt";
CM_ SG_ 2600468483 NM_Sekundaer_03_NM_aktiv_Diagnos "Diagnose befindet sich nach VW80124 in einer NonDefaultDiagnostic-Session, z.B. ExtendedDiagnostic-Session";
CM_ SG_ 2600468483 NM_Sekundaer_03_NM_aktiv_Tmin "Mindestaktivzeit ist noch nicht abgelaufen (bei jedem Weckereignis wird die Mindestaktivzeit neu gestartet)";
CM_ SG_ 2600468483 NM_Sekundaer_03_NM_aktiv_Anf_HVK "Anforderung HVK (Nachlaufursache, SG nicht im NM-Zustand 'Ready to Sleep')";
CM_ SG_ 2600468483 NM_Sekundaer_03_CAB "CAB = Clusteraktivbits";
CM_ SG_ 2600468553 NM_Sub_Gateway_SNI "Source Node-Identifier (SNI) identifiziert den Sender der NM-Botschaft (Knotenadresse) eindeutig im Fahrzeug";
CM_ SG_ 2600468553 NM_Sub_Gateway_CBV_AWB "Das Signal ist zu setzen, wenn das SG aktiv den Bus geweckt hat";
CM_ SG_ 2600468553 NM_Sub_Gateway_CBV_CRI "Das Signal ist dauerhaft gesetzt, wenn das NM-Layout dem neuen NM-Layout für Teilnetzbetrieb entspricht";
CM_ SG_ 2600468553 NM_Sub_Gateway_NM_State "1 = Zustand Repeat Message (<-- Bus-Sleep Mode)
2 = Zustand Repeat Message (<-- Prepare Bus-Sleep Mode)
4 = Zustand Normal Operation (<-- Repeat Message)
8 = Zustand Normal Operation (<-- Ready Sleep)
16 = Zustand Repeat Message (<-- Ready Sleep)
32 ";
CM_ SG_ 2600468553 NM_Sub_Gateway_Car_Wakeup "Car Wakeup (Gateway wertet aus)";
CM_ SG_ 2600468553 NM_Sub_Gateway_UDS_CC "Funktionseinschränkung aufgrund aktivem UDS-Communication Control; siehe VW80124";
CM_ SG_ 2600468553 NM_Sub_Gateway_NM_aktiv_KL15 "Steuergerät hat KL15-EIN erkannt";
CM_ SG_ 2600468553 NM_Sub_Gateway_NM_aktiv_Diagnose "Diagnose befindet sich nach VW80124 in einer NonDefaultDiagnostic-Session, z.B. ExtendedDiagnostic-Session";
CM_ SG_ 2600468553 NM_Sub_Gateway_NM_aktiv_Tmin "Mindestaktivzeit ist noch nicht abgelaufen (bei jedem Weckereignis wird die Mindestaktivzeit neu gestartet)";
CM_ SG_ 2600468553 NM_Sub_Gateway_CAB "CAB = Clusteraktivbits";
BA_DEF_ BO_  "DiagRequest" ENUM  "No","Yes";
BA_DEF_ BO_  "DiagResponse" ENUM  "No","Yes";
BA_DEF_ BO_  "DiagState" ENUM  "No","Yes";
BA_DEF_ BO_  "GenMsgChkConstant" HEX 0 4095;
BA_DEF_ BO_  "GenMsgCycleTime" INT 0 65535;
BA_DEF_ BO_  "GenMsgCycleTimeFast" INT 0 65535;
BA_DEF_ BO_  "GenMsgDelayTime" INT 0 100000;
BA_DEF_ BO_  "GenMsgILSupport" ENUM  "No","Yes";
BA_DEF_ BO_  "GenMsgNrOfRepetition" INT 0 100;
BA_DEF_ BO_  "GenMsgPDUConstants" STRING ;
BA_DEF_ BO_  "GenMsgSendType" ENUM  "Cyclic","not_used","not_used","not_used","not_used","not_used","not_used","IfActive","NoMsgSendType";
BA_DEF_ BO_  "GenMsgStartDelayTime" INT 0 100000;
BA_DEF_ BO_  "NmMessage" ENUM  "No","Yes";
BA_DEF_ BO_  "NmhMessage" ENUM  "No","Yes";
BA_DEF_ BO_  "MsgType" ENUM  "Application","NM ","NMH","TP2.0","ISO-TP ","BAP","EID","KS","XCP_PRE_CONFIGURED","XCP_RUNTIME_CONFIGURED";
BA_DEF_ BO_  "VAGTP20_API" HEX 0 255;
BA_DEF_ BO_  "VAGTP20_DynConnection" ENUM  "No","Yes";
BA_DEF_ BO_  "VAGTP20_DynSetup" ENUM  "No","Yes";
BA_DEF_ BO_  "VAGTP20_StatConnection" ENUM  "No","Yes";
BA_DEF_ SG_  "GenSigActiveRepetitions" INT -2147483648 2147483647;
BA_DEF_ SG_  "GenSigInactiveValue" INT -2147483648 2147483647;
BA_DEF_ SG_  "GenSigSendType" ENUM  "Cyclic","OnWrite","OnWriteWithRepetition","OnChange","OnChangeWithRepetition","IfActive","IfActiveWithRepetition","NoSigSendType","OnChangeAndIfActive","OnChangeAndIfActiveWithRepetition";
BA_DEF_ SG_  "GenSigStartValue" INT -2147483648 2147483647;
BA_DEF_ SG_  "NWM-WakeupAllowed" ENUM  "No","Yes";
BA_DEF_ SG_  "GenSigFuncType" ENUM  "NoFunction","MsgCounter","CRC-8","XOR","XOR-2","DatedBit","SW-Kl15","CHK","Constant","Protocol","CRC-8-SAE_J1850","CRC-32","DataLength","DataID","MsgCounter16","SOK-Signatur","Cluster";
BA_DEF_ SG_  "GenSigSwitchedByIgnition" ENUM  "No","Yes";
BA_DEF_ SG_  "Fehlerwert" HEX 0 2147483647;
BA_DEF_ SG_  "GenSigMissingSourceValue" HEX 0 2147483647;
BA_DEF_REL_ BU_SG_REL_  "GenSigTimeoutTime" INT 0 65535;
BA_DEF_DEF_REL_ "GenSigTimeoutTime" 0;
BA_DEF_DEF_  "DiagRequest" "No";
BA_DEF_DEF_  "DiagResponse" "No";
BA_DEF_DEF_  "DiagState" "No";
BA_DEF_DEF_  "GenMsgChkConstant" 0;
BA_DEF_DEF_  "GenMsgCycleTime" 0;
BA_DEF_DEF_  "GenMsgCycleTimeFast" 0;
BA_DEF_DEF_  "GenMsgDelayTime" 0;
BA_DEF_DEF_  "GenMsgILSupport" "No";
BA_DEF_DEF_  "GenMsgNrOfRepetition" 0;
BA_DEF_DEF_  "GenMsgPDUConstants" "";
BA_DEF_DEF_  "GenMsgSendType" "NoMsgSendType";
BA_DEF_DEF_  "GenMsgStartDelayTime" 0;
BA_DEF_DEF_  "NmMessage" "No";
BA_DEF_DEF_  "NmhMessage" "No";
BA_DEF_DEF_  "MsgType" "Application";
BA_DEF_DEF_  "VAGTP20_API" 0;
BA_DEF_DEF_  "VAGTP20_DynConnection" "No";
BA_DEF_DEF_  "VAGTP20_DynSetup" "No";
BA_DEF_DEF_  "VAGTP20_StatConnection" "No";
BA_DEF_DEF_  "GenSigActiveRepetitions" 0;
BA_DEF_DEF_  "GenSigInactiveValue" 0;
BA_DEF_DEF_  "GenSigSendType" "NoSigSendType";
BA_DEF_DEF_  "GenSigStartValue" 0;
BA_DEF_DEF_  "NWM-WakeupAllowed" "No";
BA_DEF_DEF_  "GenSigFuncType" "NoFunction";
BA_DEF_DEF_  "GenSigSwitchedByIgnition" "Yes";
BA_DEF_DEF_  "Fehlerwert" 0;
BA_DEF_DEF_  "GenSigMissingSourceValue" 0;
BA_ "GenMsgStartDelayTime" BO_ 339 20;
BA_ "GenMsgSendType" BO_ 339 0;
BA_ "GenMsgPDUConstants" BO_ 339 "0x03,0x13,0x23,0x7a,0x40,0x51,0x68,0xba,0xa8,0xbe,0x55,0x02,0x11,0x31,0x76,0xec";
BA_ "GenMsgILSupport" BO_ 339 1;
BA_ "GenMsgDelayTime" BO_ 339 10;
BA_ "GenMsgCycleTime" BO_ 339 200;
BA_ "GenMsgSendType" BO_ 1434 0;
BA_ "GenMsgILSupport" BO_ 1434 1;
BA_ "GenMsgCycleTime" BO_ 1434 80;
BA_ "GenMsgSendType" BO_ 689 0;
BA_ "GenMsgILSupport" BO_ 689 1;
BA_ "GenMsgCycleTime" BO_ 689 40;
BA_ "GenMsgStartDelayTime" BO_ 931 320;
BA_ "GenMsgSendType" BO_ 931 0;
BA_ "GenMsgILSupport" BO_ 931 1;
BA_ "GenMsgCycleTime" BO_ 931 80;
BA_ "GenMsgStartDelayTime" BO_ 2589283456 50;
BA_ "GenMsgSendType" BO_ 2589283456 0;
BA_ "GenMsgILSupport" BO_ 2589283456 1;
BA_ "GenMsgCycleTime" BO_ 2589283456 320;
BA_ "GenMsgStartDelayTime" BO_ 1284 10;
BA_ "GenMsgSendType" BO_ 1284 0;
BA_ "GenMsgPDUConstants" BO_ 1284 "0x03,0x63,0x3e,0x04,0xf9,0xb4,0x4f,0x32,0x25,0x56,0x1e,0xc1,0x83,0xfa,0x31,0x97";
BA_ "GenMsgILSupport" BO_ 1284 1;
BA_ "GenMsgDelayTime" BO_ 1284 10;
BA_ "GenMsgCycleTime" BO_ 1284 100;
BA_ "GenMsgSendType" BO_ 1157 0;
BA_ "GenMsgILSupport" BO_ 1157 1;
BA_ "GenMsgCycleTime" BO_ 1157 1000;
BA_ "GenMsgSendType" BO_ 1158 0;
BA_ "GenMsgILSupport" BO_ 1158 1;
BA_ "GenMsgCycleTime" BO_ 1158 1000;
BA_ "GenMsgSendType" BO_ 2589283496 0;
BA_ "GenMsgILSupport" BO_ 2589283496 1;
BA_ "GenMsgCycleTime" BO_ 2589283496 500;
BA_ "MsgType" BO_ 2600468623 2;
BA_ "NmhMessage" BO_ 2600468623 1;
BA_ "GenMsgSendType" BO_ 2600468623 7;
BA_ "GenMsgCycleTimeFast" BO_ 2600468623 10;
BA_ "GenMsgCycleTime" BO_ 2600468623 200;
BA_ "MsgType" BO_ 2600468654 2;
BA_ "NmhMessage" BO_ 2600468654 1;
BA_ "GenMsgSendType" BO_ 2600468654 7;
BA_ "GenMsgCycleTimeFast" BO_ 2600468654 10;
BA_ "GenMsgCycleTime" BO_ 2600468654 200;
BA_ "MsgType" BO_ 2600468636 2;
BA_ "NmhMessage" BO_ 2600468636 1;
BA_ "GenMsgSendType" BO_ 2600468636 7;
BA_ "GenMsgCycleTimeFast" BO_ 2600468636 10;
BA_ "GenMsgCycleTime" BO_ 2600468636 200;
BA_ "MsgType" BO_ 2600468545 2;
BA_ "NmhMessage" BO_ 2600468545 1;
BA_ "GenMsgSendType" BO_ 2600468545 7;
BA_ "GenMsgCycleTimeFast" BO_ 2600468545 10;
BA_ "GenMsgCycleTime" BO_ 2600468545 200;
BA_ "MsgType" BO_ 2600468663 2;
BA_ "NmhMessage" BO_ 2600468663 1;
BA_ "GenMsgSendType" BO_ 2600468663 7;
BA_ "GenMsgCycleTimeFast" BO_ 2600468663 10;
BA_ "GenMsgCycleTime" BO_ 2600468663 200;
BA_ "MsgType" BO_ 2600468679 2;
BA_ "NmhMessage" BO_ 2600468679 1;
BA_ "GenMsgSendType" BO_ 2600468679 7;
BA_ "GenMsgCycleTimeFast" BO_ 2600468679 10;
BA_ "GenMsgCycleTime" BO_ 2600468679 200;
BA_ "MsgType" BO_ 2600468661 2;
BA_ "NmhMessage" BO_ 2600468661 1;
BA_ "GenMsgSendType" BO_ 2600468661 7;
BA_ "GenMsgCycleTimeFast" BO_ 2600468661 10;
BA_ "GenMsgCycleTime" BO_ 2600468661 200;
BA_ "MsgType" BO_ 2600468496 2;
BA_ "NmhMessage" BO_ 2600468496 1;
BA_ "GenMsgSendType" BO_ 2600468496 7;
BA_ "GenMsgCycleTimeFast" BO_ 2600468496 10;
BA_ "GenMsgCycleTime" BO_ 2600468496 200;
BA_ "MsgType" BO_ 2600468603 2;
BA_ "NmhMessage" BO_ 2600468603 1;
BA_ "GenMsgSendType" BO_ 2600468603 7;
BA_ "GenMsgCycleTimeFast" BO_ 2600468603 10;
BA_ "GenMsgCycleTime" BO_ 2600468603 200;
BA_ "MsgType" BO_ 2600468548 2;
BA_ "NmhMessage" BO_ 2600468548 1;
BA_ "GenMsgSendType" BO_ 2600468548 7;
BA_ "GenMsgCycleTimeFast" BO_ 2600468548 10;
BA_ "GenMsgCycleTime" BO_ 2600468548 200;
BA_ "MsgType" BO_ 2600468678 2;
BA_ "NmhMessage" BO_ 2600468678 1;
BA_ "GenMsgSendType" BO_ 2600468678 7;
BA_ "GenMsgCycleTimeFast" BO_ 2600468678 10;
BA_ "GenMsgCycleTime" BO_ 2600468678 200;
BA_ "MsgType" BO_ 2600468481 2;
BA_ "NmhMessage" BO_ 2600468481 1;
BA_ "GenMsgSendType" BO_ 2600468481 7;
BA_ "GenMsgCycleTimeFast" BO_ 2600468481 10;
BA_ "GenMsgCycleTime" BO_ 2600468481 200;
BA_ "MsgType" BO_ 2600468483 2;
BA_ "NmhMessage" BO_ 2600468483 1;
BA_ "GenMsgSendType" BO_ 2600468483 7;
BA_ "GenMsgCycleTimeFast" BO_ 2600468483 10;
BA_ "GenMsgCycleTime" BO_ 2600468483 200;
BA_ "MsgType" BO_ 2600468553 2;
BA_ "NmhMessage" BO_ 2600468553 1;
BA_ "GenMsgSendType" BO_ 2600468553 7;
BA_ "GenMsgCycleTimeFast" BO_ 2600468553 10;
BA_ "GenMsgCycleTime" BO_ 2600468553 200;
BA_ "GenSigSwitchedByIgnition" SG_ 339 MSG_HYB_30_CRC 0;
BA_ "GenSigFuncType" SG_ 339 MSG_HYB_30_CRC 2;
BA_ "GenSigSendType" SG_ 339 MSG_HYB_30_CRC 0;
BA_ "GenSigSwitchedByIgnition" SG_ 339 MSG_HYB_30_BZ 0;
BA_ "GenSigFuncType" SG_ 339 MSG_HYB_30_BZ 1;
BA_ "GenSigSendType" SG_ 339 MSG_HYB_30_BZ 0;
BA_ "GenSigSwitchedByIgnition" SG_ 339 MO_HVEM_Eskalation 0;
BA_ "GenSigSendType" SG_ 339 MO_HVEM_Eskalation 0;
BA_ "GenSigSwitchedByIgnition" SG_ 339 MO_ErwGrenzen_Anf 0;
BA_ "GenSigSendType" SG_ 339 MO_ErwGrenzen_Anf 3;
BA_ "GenSigSwitchedByIgnition" SG_ 339 MO_Fehler_Notentladung_Anf 0;
BA_ "GenSigSendType" SG_ 339 MO_Fehler_Notentladung_Anf 0;
BA_ "GenSigSwitchedByIgnition" SG_ 339 MO_HVEM_MaxLeistung 0;
BA_ "GenSigStartValue" SG_ 339 MO_HVEM_MaxLeistung 510;
BA_ "GenSigSendType" SG_ 339 MO_HVEM_MaxLeistung 0;
BA_ "GenSigSwitchedByIgnition" SG_ 339 MO_HVK_EmIstzustand 0;
BA_ "GenSigStartValue" SG_ 339 MO_HVK_EmIstzustand 255;
BA_ "GenSigSendType" SG_ 339 MO_HVK_EmIstzustand 0;
BA_ "GenSigSwitchedByIgnition" SG_ 339 MO_HVK_AntriebFehlerstatus 0;
BA_ "GenSigStartValue" SG_ 339 MO_HVK_AntriebFehlerstatus 7;
BA_ "GenSigSendType" SG_ 339 MO_HVK_AntriebFehlerstatus 0;
BA_ "GenSigSwitchedByIgnition" SG_ 339 MO_MVK_Bordnetz_Anf 0;
BA_ "GenSigSendType" SG_ 339 MO_MVK_Bordnetz_Anf 0;
BA_ "GenSigSwitchedByIgnition" SG_ 339 MO_HVK_AntriebZustand 0;
BA_ "GenSigStartValue" SG_ 339 MO_HVK_AntriebZustand 7;
BA_ "GenSigSendType" SG_ 339 MO_HVK_AntriebZustand 3;
BA_ "GenSigSwitchedByIgnition" SG_ 339 MO_HVK_EmFehlerstatus 0;
BA_ "GenSigStartValue" SG_ 339 MO_HVK_EmFehlerstatus 7;
BA_ "GenSigSendType" SG_ 339 MO_HVK_EmFehlerstatus 0;
BA_ "GenSigSwitchedByIgnition" SG_ 339 MO_MVK_AntriebFehlerstatus 0;
BA_ "GenSigStartValue" SG_ 339 MO_MVK_AntriebFehlerstatus 7;
BA_ "GenSigSendType" SG_ 339 MO_MVK_AntriebFehlerstatus 0;
BA_ "GenSigSwitchedByIgnition" SG_ 339 MO_MVK_AntriebZustand 0;
BA_ "GenSigStartValue" SG_ 339 MO_MVK_AntriebZustand 7;
BA_ "GenSigSendType" SG_ 339 MO_MVK_AntriebZustand 0;
BA_ "GenSigSwitchedByIgnition" SG_ 339 MO_MVK_EmFehlerstatus 0;
BA_ "GenSigStartValue" SG_ 339 MO_MVK_EmFehlerstatus 7;
BA_ "GenSigSendType" SG_ 339 MO_MVK_EmFehlerstatus 0;
BA_ "GenSigSwitchedByIgnition" SG_ 339 MO_MVK_EmIstzustand 0;
BA_ "GenSigStartValue" SG_ 339 MO_MVK_EmIstzustand 255;
BA_ "GenSigSendType" SG_ 339 MO_MVK_EmIstzustand 0;
BA_ "Fehlerwert" SG_ 1434 TME_Dauer_Vorkond_innen 63;
BA_ "GenSigSwitchedByIgnition" SG_ 1434 TME_Dauer_Vorkond_innen 0;
BA_ "GenSigStartValue" SG_ 1434 TME_Dauer_Vorkond_innen 62;
BA_ "GenSigSendType" SG_ 1434 TME_Dauer_Vorkond_innen 0;
BA_ "Fehlerwert" SG_ 1434 TME_Eskalation 3;
BA_ "GenSigStartValue" SG_ 1434 TME_Eskalation 2;
BA_ "GenSigSendType" SG_ 1434 TME_Eskalation 0;
BA_ "Fehlerwert" SG_ 1434 TME_Leistungsanf_ThermoKuehlen 255;
BA_ "GenSigStartValue" SG_ 1434 TME_Leistungsanf_ThermoKuehlen 254;
BA_ "GenSigSendType" SG_ 1434 TME_Leistungsanf_ThermoKuehlen 0;
BA_ "Fehlerwert" SG_ 1434 TME_Leistungsanf_ThermoHeizen 255;
BA_ "GenSigStartValue" SG_ 1434 TME_Leistungsanf_ThermoHeizen 254;
BA_ "GenSigSendType" SG_ 1434 TME_Leistungsanf_ThermoHeizen 0;
BA_ "Fehlerwert" SG_ 1434 TME_Leistungsanf_Komfort 255;
BA_ "GenSigStartValue" SG_ 1434 TME_Leistungsanf_Komfort 254;
BA_ "GenSigSendType" SG_ 1434 TME_Leistungsanf_Komfort 0;
BA_ "Fehlerwert" SG_ 1434 KL_IstLeistung 255;
BA_ "GenSigSwitchedByIgnition" SG_ 1434 KL_IstLeistung 0;
BA_ "GenSigStartValue" SG_ 1434 KL_IstLeistung 254;
BA_ "GenSigSendType" SG_ 1434 KL_IstLeistung 0;
BA_ "Fehlerwert" SG_ 689 TME_PlanAntw_Zaehler 15;
BA_ "GenSigSwitchedByIgnition" SG_ 689 TME_PlanAntw_Zaehler 0;
BA_ "GenSigStartValue" SG_ 689 TME_PlanAntw_Zaehler 14;
BA_ "GenSigSendType" SG_ 689 TME_PlanAntw_Zaehler 0;
BA_ "GenSigSwitchedByIgnition" SG_ 689 TME_Verbrauch_gesamt_Ueberlauf 0;
BA_ "GenSigSendType" SG_ 689 TME_Verbrauch_gesamt_Ueberlauf 0;
BA_ "GenSigSwitchedByIgnition" SG_ 689 TME_Verbrauch_gesamt 0;
BA_ "GenSigSendType" SG_ 689 TME_Verbrauch_gesamt 0;
BA_ "Fehlerwert" SG_ 689 TME_Energie_Thermo 16383;
BA_ "GenSigSwitchedByIgnition" SG_ 689 TME_Energie_Thermo 0;
BA_ "GenSigStartValue" SG_ 689 TME_Energie_Thermo 16382;
BA_ "GenSigSendType" SG_ 689 TME_Energie_Thermo 0;
BA_ "Fehlerwert" SG_ 689 TME_Energie_Komfort 16383;
BA_ "GenSigSwitchedByIgnition" SG_ 689 TME_Energie_Komfort 0;
BA_ "GenSigStartValue" SG_ 689 TME_Energie_Komfort 16382;
BA_ "GenSigSendType" SG_ 689 TME_Energie_Komfort 0;
BA_ "Fehlerwert" SG_ 931 MVEM_MO_RSG_Startleistung 255;
BA_ "GenSigSwitchedByIgnition" SG_ 931 MVEM_MO_RSG_Startleistung 0;
BA_ "GenSigStartValue" SG_ 931 MVEM_MO_RSG_Startleistung 254;
BA_ "GenSigSendType" SG_ 931 MVEM_MO_RSG_Startleistung 0;
BA_ "Fehlerwert" SG_ 931 MVEM_Umin_Funktionsgruppe_C_02 255;
BA_ "GenSigSwitchedByIgnition" SG_ 931 MVEM_Umin_Funktionsgruppe_C_02 0;
BA_ "GenSigStartValue" SG_ 931 MVEM_Umin_Funktionsgruppe_C_02 254;
BA_ "GenSigSendType" SG_ 931 MVEM_Umin_Funktionsgruppe_C_02 0;
BA_ "Fehlerwert" SG_ 931 MVEM_IstStrom_MVVerbraucher 1023;
BA_ "GenSigSwitchedByIgnition" SG_ 931 MVEM_IstStrom_MVVerbraucher 0;
BA_ "GenSigStartValue" SG_ 931 MVEM_IstStrom_MVVerbraucher 1022;
BA_ "GenSigSendType" SG_ 931 MVEM_IstStrom_MVVerbraucher 0;
BA_ "Fehlerwert" SG_ 931 MVEM_DC_SollSpannung_MV 255;
BA_ "GenSigSwitchedByIgnition" SG_ 931 MVEM_DC_SollSpannung_MV 0;
BA_ "GenSigStartValue" SG_ 931 MVEM_DC_SollSpannung_MV 254;
BA_ "GenSigSendType" SG_ 931 MVEM_DC_SollSpannung_MV 0;
BA_ "Fehlerwert" SG_ 931 MVEM_DC_SollLeistung_MV 255;
BA_ "GenSigSwitchedByIgnition" SG_ 931 MVEM_DC_SollLeistung_MV 0;
BA_ "GenSigStartValue" SG_ 931 MVEM_DC_SollLeistung_MV 254;
BA_ "GenSigSendType" SG_ 931 MVEM_DC_SollLeistung_MV 0;
BA_ "Fehlerwert" SG_ 931 MVEM_EMG_MaxGenStrom 255;
BA_ "GenSigSwitchedByIgnition" SG_ 931 MVEM_EMG_MaxGenStrom 0;
BA_ "GenSigStartValue" SG_ 931 MVEM_EMG_MaxGenStrom 254;
BA_ "GenSigSendType" SG_ 931 MVEM_EMG_MaxGenStrom 0;
BA_ "Fehlerwert" SG_ 931 MVEM_EMG_MaxGenSpannung 255;
BA_ "GenSigSwitchedByIgnition" SG_ 931 MVEM_EMG_MaxGenSpannung 0;
BA_ "GenSigStartValue" SG_ 931 MVEM_EMG_MaxGenSpannung 254;
BA_ "GenSigSendType" SG_ 931 MVEM_EMG_MaxGenSpannung 0;
BA_ "Fehlerwert" SG_ 2589283456 MVEM_MO_Sollspannung_Notbetrieb 255;
BA_ "GenSigSwitchedByIgnition" SG_ 2589283456 MVEM_MO_Sollspannung_Notbetrieb 0;
BA_ "GenSigStartValue" SG_ 2589283456 MVEM_MO_Sollspannung_Notbetrieb 254;
BA_ "GenSigSendType" SG_ 2589283456 MVEM_MO_Sollspannung_Notbetrieb 0;
BA_ "Fehlerwert" SG_ 2589283456 MVEM_Umax_Rueckspeisung 255;
BA_ "GenSigSwitchedByIgnition" SG_ 2589283456 MVEM_Umax_Rueckspeisung 0;
BA_ "GenSigStartValue" SG_ 2589283456 MVEM_Umax_Rueckspeisung 254;
BA_ "GenSigSendType" SG_ 2589283456 MVEM_Umax_Rueckspeisung 0;
BA_ "Fehlerwert" SG_ 2589283456 MVEM_Umin_Funktionsgruppe_C 255;
BA_ "GenSigSwitchedByIgnition" SG_ 2589283456 MVEM_Umin_Funktionsgruppe_C 0;
BA_ "GenSigStartValue" SG_ 2589283456 MVEM_Umin_Funktionsgruppe_C 254;
BA_ "GenSigSendType" SG_ 2589283456 MVEM_Umin_Funktionsgruppe_C 0;
BA_ "Fehlerwert" SG_ 2589283456 MVEM_Umin_Funktionsgruppe_B 255;
BA_ "GenSigSwitchedByIgnition" SG_ 2589283456 MVEM_Umin_Funktionsgruppe_B 0;
BA_ "GenSigStartValue" SG_ 2589283456 MVEM_Umin_Funktionsgruppe_B 254;
BA_ "GenSigSendType" SG_ 2589283456 MVEM_Umin_Funktionsgruppe_B 0;
BA_ "Fehlerwert" SG_ 2589283456 MVEM_Umin_Funktionsgruppe_A 255;
BA_ "GenSigSwitchedByIgnition" SG_ 2589283456 MVEM_Umin_Funktionsgruppe_A 0;
BA_ "GenSigStartValue" SG_ 2589283456 MVEM_Umin_Funktionsgruppe_A 254;
BA_ "GenSigSendType" SG_ 2589283456 MVEM_Umin_Funktionsgruppe_A 0;
BA_ "GenSigSwitchedByIgnition" SG_ 1284 MVK_01_CRC 0;
BA_ "GenSigFuncType" SG_ 1284 MVK_01_CRC 2;
BA_ "GenSigSendType" SG_ 1284 MVK_01_CRC 0;
BA_ "GenSigSwitchedByIgnition" SG_ 1284 MVK_01_BZ 0;
BA_ "GenSigFuncType" SG_ 1284 MVK_01_BZ 1;
BA_ "GenSigSendType" SG_ 1284 MVK_01_BZ 0;
BA_ "GenSigSwitchedByIgnition" SG_ 1284 MVK_DCDC_Sollmodus_02 0;
BA_ "GenSigStartValue" SG_ 1284 MVK_DCDC_Sollmodus_02 7;
BA_ "GenSigSendType" SG_ 1284 MVK_DCDC_Sollmodus_02 3;
BA_ "GenSigSwitchedByIgnition" SG_ 1284 MV_Bordnetz_aktiv 0;
BA_ "GenSigSendType" SG_ 1284 MV_Bordnetz_aktiv 0;
BA_ "GenSigSwitchedByIgnition" SG_ 1284 MVK_BOOST_Sollmodus 0;
BA_ "GenSigStartValue" SG_ 1284 MVK_BOOST_Sollmodus 7;
BA_ "GenSigSendType" SG_ 1284 MVK_BOOST_Sollmodus 3;
BA_ "GenSigSwitchedByIgnition" SG_ 1284 MVK_eABC_Sollmodus 0;
BA_ "GenSigStartValue" SG_ 1284 MVK_eABC_Sollmodus 7;
BA_ "GenSigSendType" SG_ 1284 MVK_eABC_Sollmodus 3;
BA_ "GenSigSwitchedByIgnition" SG_ 1284 MVK_eAWS_Sollmodus 0;
BA_ "GenSigStartValue" SG_ 1284 MVK_eAWS_Sollmodus 7;
BA_ "GenSigSendType" SG_ 1284 MVK_eAWS_Sollmodus 3;
BA_ "Fehlerwert" SG_ 1284 MV_Bordnetz_Fehler 1;
BA_ "GenSigSwitchedByIgnition" SG_ 1284 MV_Bordnetz_Fehler 0;
BA_ "GenSigSendType" SG_ 1284 MV_Bordnetz_Fehler 3;
BA_ "GenSigSwitchedByIgnition" SG_ 1284 MVK_MVPTC_Sollmodus 0;
BA_ "GenSigStartValue" SG_ 1284 MVK_MVPTC_Sollmodus 7;
BA_ "GenSigSendType" SG_ 1284 MVK_MVPTC_Sollmodus 3;
BA_ "GenSigSwitchedByIgnition" SG_ 1284 MVK_Istmodus_Anf 0;
BA_ "GenSigSendType" SG_ 1284 MVK_Istmodus_Anf 3;
BA_ "GenSigSwitchedByIgnition" SG_ 1284 MVK_MO_EmSollzustand 0;
BA_ "GenSigStartValue" SG_ 1284 MVK_MO_EmSollzustand 255;
BA_ "GenSigSendType" SG_ 1284 MVK_MO_EmSollzustand 3;
BA_ "GenSigSwitchedByIgnition" SG_ 1284 MVK_BMS_Sollmodus 0;
BA_ "GenSigStartValue" SG_ 1284 MVK_BMS_Sollmodus 7;
BA_ "GenSigSendType" SG_ 1284 MVK_BMS_Sollmodus 3;
BA_ "GenSigSwitchedByIgnition" SG_ 1284 MVK_DCDC_Sollmodus 0;
BA_ "GenSigStartValue" SG_ 1284 MVK_DCDC_Sollmodus 7;
BA_ "GenSigSendType" SG_ 1284 MVK_DCDC_Sollmodus 3;
BA_ "GenSigSwitchedByIgnition" SG_ 1284 MVK_MV_Netz_Warnungen 0;
BA_ "GenSigSendType" SG_ 1284 MVK_MV_Netz_Warnungen 3;
BA_ "Fehlerwert" SG_ 1157 ND_SatInUse 31;
BA_ "GenSigSwitchedByIgnition" SG_ 1157 ND_SatInUse 0;
BA_ "GenSigStartValue" SG_ 1157 ND_SatInUse 30;
BA_ "GenSigSendType" SG_ 1157 ND_SatInUse 0;
BA_ "GenSigSwitchedByIgnition" SG_ 1157 POS_Guete_horizontal_verfuegbar 0;
BA_ "GenSigSendType" SG_ 1157 POS_Guete_horizontal_verfuegbar 0;
BA_ "Fehlerwert" SG_ 1157 ND_SatInView 31;
BA_ "GenSigSwitchedByIgnition" SG_ 1157 ND_SatInView 0;
BA_ "GenSigStartValue" SG_ 1157 ND_SatInView 30;
BA_ "GenSigSendType" SG_ 1157 ND_SatInView 0;
BA_ "Fehlerwert" SG_ 1157 POS_Guete_horizontal 127;
BA_ "GenSigSwitchedByIgnition" SG_ 1157 POS_Guete_horizontal 0;
BA_ "GenSigStartValue" SG_ 1157 POS_Guete_horizontal 126;
BA_ "GenSigSendType" SG_ 1157 POS_Guete_horizontal 0;
BA_ "Fehlerwert" SG_ 1157 NP_Altitude 4095;
BA_ "GenSigSwitchedByIgnition" SG_ 1157 NP_Altitude 0;
BA_ "GenSigStartValue" SG_ 1157 NP_Altitude 4094;
BA_ "GenSigSendType" SG_ 1157 NP_Altitude 0;
BA_ "GenSigSwitchedByIgnition" SG_ 1157 ND_UTC 0;
BA_ "GenSigSendType" SG_ 1157 ND_UTC 0;
BA_ "Fehlerwert" SG_ 1158 NP_LatDegree 134217727;
BA_ "GenSigSwitchedByIgnition" SG_ 1158 NP_LatDegree 0;
BA_ "GenSigStartValue" SG_ 1158 NP_LatDegree 134217726;
BA_ "GenSigSendType" SG_ 1158 NP_LatDegree 0;
BA_ "Fehlerwert" SG_ 1158 NP_LongDegree 268435455;
BA_ "GenSigSwitchedByIgnition" SG_ 1158 NP_LongDegree 0;
BA_ "GenSigStartValue" SG_ 1158 NP_LongDegree 268435454;
BA_ "GenSigSendType" SG_ 1158 NP_LongDegree 0;
BA_ "GenSigSwitchedByIgnition" SG_ 1158 NP_LatDirection 0;
BA_ "GenSigStartValue" SG_ 1158 NP_LatDirection 1;
BA_ "GenSigSendType" SG_ 1158 NP_LatDirection 0;
BA_ "GenSigSwitchedByIgnition" SG_ 1158 NP_LongDirection 0;
BA_ "GenSigStartValue" SG_ 1158 NP_LongDirection 1;
BA_ "GenSigSendType" SG_ 1158 NP_LongDirection 0;
BA_ "Fehlerwert" SG_ 1158 NP_Sat 31;
BA_ "GenSigSwitchedByIgnition" SG_ 1158 NP_Sat 0;
BA_ "GenSigStartValue" SG_ 1158 NP_Sat 30;
BA_ "GenSigSendType" SG_ 1158 NP_Sat 0;
BA_ "GenSigSwitchedByIgnition" SG_ 1158 NP_Fix 0;
BA_ "GenSigSendType" SG_ 1158 NP_Fix 0;
BA_ "GenSigSwitchedByIgnition" SG_ 2589283496 POS_MUX 0;
BA_ "GenSigStartValue" SG_ 2589283496 POS_MUX 3;
BA_ "GenSigSendType" SG_ 2589283496 POS_MUX 0;
BA_ "GenSigSwitchedByIgnition" SG_ 2589283496 POS_ODD_EVEN 0;
BA_ "GenSigSendType" SG_ 2589283496 POS_ODD_EVEN 0;
BA_ "GenSigSwitchedByIgnition" SG_ 2589283496 POS_PosStati 0;
BA_ "GenSigSwitchedByIgnition" SG_ 2589283496 POS_Heading 0;
BA_ "GenSigSwitchedByIgnition" SG_ 2589283496 POS_LatDirection 0;
BA_ "Fehlerwert" SG_ 2589283496 POS_LatDegree 134217727;
BA_ "GenSigSwitchedByIgnition" SG_ 2589283496 POS_LatDegree 0;
BA_ "GenSigStartValue" SG_ 2589283496 POS_LatDegree 134217726;
BA_ "GenSigSwitchedByIgnition" SG_ 2589283496 POS_Last_GPS_Sync 0;
BA_ "Fehlerwert" SG_ 2589283496 POS_Heading_Trust 3;
BA_ "GenSigSwitchedByIgnition" SG_ 2589283496 POS_Heading_Trust 0;
BA_ "GenSigSwitchedByIgnition" SG_ 2589283496 POS_UTC_REF 0;
BA_ "GenSigSwitchedByIgnition" SG_ 2589283496 POS_LongDirection 0;
BA_ "Fehlerwert" SG_ 2589283496 POS_LongDegree 268435455;
BA_ "GenSigSwitchedByIgnition" SG_ 2589283496 POS_LongDegree 0;
BA_ "GenSigStartValue" SG_ 2589283496 POS_LongDegree 268435454;
BA_ "GenSigSwitchedByIgnition" SG_ 2600468623 NM_AWC_SNI 0;
BA_ "GenSigStartValue" SG_ 2600468623 NM_AWC_SNI 143;
BA_ "GenSigSwitchedByIgnition" SG_ 2600468623 NM_AWC_CBV_AWB 0;
BA_ "GenSigSwitchedByIgnition" SG_ 2600468623 NM_AWC_CBV_CRI 0;
BA_ "GenSigFuncType" SG_ 2600468623 NM_AWC_CBV_CRI 8;
BA_ "GenSigSwitchedByIgnition" SG_ 2600468623 NM_AWC_NM_State 0;
BA_ "GenSigSwitchedByIgnition" SG_ 2600468623 NM_AWC_Car_Wakeup 0;
BA_ "GenSigSendType" SG_ 2600468623 NM_AWC_Car_Wakeup 3;
BA_ "GenSigSwitchedByIgnition" SG_ 2600468623 NM_AWC_UDS_CC 0;
BA_ "GenSigSwitchedByIgnition" SG_ 2600468623 NM_AWC_NM_aktiv_KL15 0;
BA_ "GenSigSwitchedByIgnition" SG_ 2600468623 NM_AWC_NM_aktiv_Diagnose 0;
BA_ "GenSigSwitchedByIgnition" SG_ 2600468623 NM_AWC_NM_aktiv_Tmin 0;
BA_ "GenSigSwitchedByIgnition" SG_ 2600468623 NM_AWC_CAB 0;
BA_ "GenSigSendType" SG_ 2600468623 NM_AWC_CAB 4;
BA_ "GenSigActiveRepetitions" SG_ 2600468623 NM_AWC_CAB 3;
BA_ "GenSigSwitchedByIgnition" SG_ 2600468654 NM_BattRegelung_SNI 0;
BA_ "GenSigStartValue" SG_ 2600468654 NM_BattRegelung_SNI 174;
BA_ "GenSigSwitchedByIgnition" SG_ 2600468654 NM_BattRegelung_CBV_AWB 0;
BA_ "GenSigSwitchedByIgnition" SG_ 2600468654 NM_BattRegelung_CBV_CRI 0;
BA_ "GenSigSwitchedByIgnition" SG_ 2600468654 NM_Battregelung_NM_State 0;
BA_ "GenSigSwitchedByIgnition" SG_ 2600468654 NM_BattRegelung_Car_Wakeup 0;
BA_ "GenSigSendType" SG_ 2600468654 NM_BattRegelung_Car_Wakeup 3;
BA_ "GenSigSwitchedByIgnition" SG_ 2600468654 NM_BattRegelung_UDS_CC 0;
BA_ "GenSigSwitchedByIgnition" SG_ 2600468654 NM_BattRegelung_NM_aktiv_KL15 0;
BA_ "GenSigSwitchedByIgnition" SG_ 2600468654 NM_BattRegelungNM_aktiv_Diagnose 0;
BA_ "GenSigSwitchedByIgnition" SG_ 2600468654 NM_BattRegelung_NM_aktiv_Tmin 0;
BA_ "GenSigSwitchedByIgnition" SG_ 2600468654 NM_BattRegelung_NM_aktiv_NV 0;
BA_ "GenSigSwitchedByIgnition" SG_ 2600468654 NM_BattRegelung_CAB 0;
BA_ "GenSigSendType" SG_ 2600468654 NM_BattRegelung_CAB 4;
BA_ "GenSigActiveRepetitions" SG_ 2600468654 NM_BattRegelung_CAB 3;
BA_ "GenSigSwitchedByIgnition" SG_ 2600468636 NM_BMS_48V_SNI 0;
BA_ "GenSigStartValue" SG_ 2600468636 NM_BMS_48V_SNI 156;
BA_ "GenSigSwitchedByIgnition" SG_ 2600468636 NM_BMS_48V_CBV_AWB 0;
BA_ "GenSigSwitchedByIgnition" SG_ 2600468636 NM_BMS_48V_CBV_CRI 0;
BA_ "GenSigFuncType" SG_ 2600468636 NM_BMS_48V_CBV_CRI 8;
BA_ "GenSigSwitchedByIgnition" SG_ 2600468636 NM_BMS_48V_NM_State 0;
BA_ "GenSigSwitchedByIgnition" SG_ 2600468636 NM_BMS_48V_Car_Wakeup 0;
BA_ "GenSigSendType" SG_ 2600468636 NM_BMS_48V_Car_Wakeup 3;
BA_ "GenSigSwitchedByIgnition" SG_ 2600468636 NM_BMS_48V_UDS_CC 0;
BA_ "GenSigSwitchedByIgnition" SG_ 2600468636 NM_BMS_48V_NM_aktiv_KL15 0;
BA_ "GenSigSwitchedByIgnition" SG_ 2600468636 NM_BMS_48V_NM_aktiv_Diagnose 0;
BA_ "GenSigSwitchedByIgnition" SG_ 2600468636 NM_BMS_48V_NM_aktiv_Tmin 0;
BA_ "GenSigSwitchedByIgnition" SG_ 2600468636 NM_BMS_48V_NM_aktiv_Hochvolt 0;
BA_ "GenSigSwitchedByIgnition" SG_ 2600468636 NM_BMS_48V_CAB 0;
BA_ "GenSigSendType" SG_ 2600468636 NM_BMS_48V_CAB 4;
BA_ "GenSigActiveRepetitions" SG_ 2600468636 NM_BMS_48V_CAB 3;
BA_ "GenSigSwitchedByIgnition" SG_ 2600468545 NM_DCDC_SNI 0;
BA_ "GenSigStartValue" SG_ 2600468545 NM_DCDC_SNI 65;
BA_ "GenSigSwitchedByIgnition" SG_ 2600468545 NM_DCDC_CBV_AWB 0;
BA_ "GenSigSwitchedByIgnition" SG_ 2600468545 NM_DCDC_CBV_CRI 0;
BA_ "GenSigFuncType" SG_ 2600468545 NM_DCDC_CBV_CRI 8;
BA_ "GenSigSwitchedByIgnition" SG_ 2600468545 NM_DCDC_NM_State 0;
BA_ "GenSigSwitchedByIgnition" SG_ 2600468545 NM_DCDC_Car_Wakeup 0;
BA_ "GenSigSendType" SG_ 2600468545 NM_DCDC_Car_Wakeup 3;
BA_ "GenSigSwitchedByIgnition" SG_ 2600468545 NM_DCDC_UDS_CC 0;
BA_ "GenSigSwitchedByIgnition" SG_ 2600468545 NM_DCDC_NM_aktiv_KL15 0;
BA_ "GenSigSwitchedByIgnition" SG_ 2600468545 NM_DCDC_NM_aktiv_Diagnose 0;
BA_ "GenSigSwitchedByIgnition" SG_ 2600468545 NM_DCDC_NM_aktiv_Tmin 0;
BA_ "GenSigSwitchedByIgnition" SG_ 2600468545 NM_DCDC_NM_aktiv_Anf_MVK 0;
BA_ "GenSigSwitchedByIgnition" SG_ 2600468545 NM_DCDC_CAB 0;
BA_ "GenSigSendType" SG_ 2600468545 NM_DCDC_CAB 4;
BA_ "GenSigActiveRepetitions" SG_ 2600468545 NM_DCDC_CAB 3;
BA_ "GenSigSwitchedByIgnition" SG_ 2600468663 NM_DCDC_HV_SNI 0;
BA_ "GenSigStartValue" SG_ 2600468663 NM_DCDC_HV_SNI 183;
BA_ "GenSigSwitchedByIgnition" SG_ 2600468663 NM_DCDC_HV_CBV_AWB 0;
BA_ "GenSigSwitchedByIgnition" SG_ 2600468663 NM_DCDC_HV_CBV_CRI 0;
BA_ "GenSigFuncType" SG_ 2600468663 NM_DCDC_HV_CBV_CRI 8;
BA_ "GenSigSwitchedByIgnition" SG_ 2600468663 NM_DCDC_HV_NM_State 0;
BA_ "GenSigSwitchedByIgnition" SG_ 2600468663 NM_DCDC_HV_Car_Wakeup 0;
BA_ "GenSigSendType" SG_ 2600468663 NM_DCDC_HV_Car_Wakeup 3;
BA_ "GenSigSwitchedByIgnition" SG_ 2600468663 NM_DCDC_HV_UDS_CC 0;
BA_ "GenSigSwitchedByIgnition" SG_ 2600468663 NM_DCDC_HV_NM_aktiv_KL15 0;
BA_ "GenSigSwitchedByIgnition" SG_ 2600468663 NM_DCDC_HV_NM_aktiv_Diagnose 0;
BA_ "GenSigSwitchedByIgnition" SG_ 2600468663 NM_DCDC_HV_NM_aktiv_Tmin 0;
BA_ "GenSigSwitchedByIgnition" SG_ 2600468663 NM_DCDC_HV_NM_aktiv_Anf_HVK 0;
BA_ "GenSigSwitchedByIgnition" SG_ 2600468663 NM_DCDC_HV_CAB 0;
BA_ "GenSigSendType" SG_ 2600468663 NM_DCDC_HV_CAB 4;
BA_ "GenSigActiveRepetitions" SG_ 2600468663 NM_DCDC_HV_CAB 3;
BA_ "GenSigSwitchedByIgnition" SG_ 2600468679 NM_DCDC_HV_02_SNI 0;
BA_ "GenSigStartValue" SG_ 2600468679 NM_DCDC_HV_02_SNI 199;
BA_ "GenSigSwitchedByIgnition" SG_ 2600468679 NM_DCDC_HV_02_CBV_AWB 0;
BA_ "GenSigSwitchedByIgnition" SG_ 2600468679 NM_DCDC_HV_02_CBV_CRI 0;
BA_ "GenSigSwitchedByIgnition" SG_ 2600468679 NM_DCDC_HV_02_NM_State 0;
BA_ "GenSigSwitchedByIgnition" SG_ 2600468679 NM_DCDC_HV_02_Car_Wakeup 0;
BA_ "GenSigSendType" SG_ 2600468679 NM_DCDC_HV_02_Car_Wakeup 3;
BA_ "GenSigSwitchedByIgnition" SG_ 2600468679 NM_DCDC_HV_02_UDS_CC 0;
BA_ "GenSigSwitchedByIgnition" SG_ 2600468679 NM_DCDC_HV_02_NM_aktiv_KL15 0;
BA_ "GenSigSwitchedByIgnition" SG_ 2600468679 NM_DCDC_HV_02_NM_aktiv_Diag 0;
BA_ "GenSigSwitchedByIgnition" SG_ 2600468679 NM_DCDC_HV_02_NM_aktiv_Tmin 0;
BA_ "GenSigSwitchedByIgnition" SG_ 2600468679 NM_DCDC_HV_02_NM_aktiv_Anf_HVK 0;
BA_ "GenSigSwitchedByIgnition" SG_ 2600468679 NM_DCDC_HV_02_CAB 0;
BA_ "GenSigSendType" SG_ 2600468679 NM_DCDC_HV_02_CAB 4;
BA_ "GenSigActiveRepetitions" SG_ 2600468679 NM_DCDC_HV_02_CAB 3;
BA_ "GenSigSwitchedByIgnition" SG_ 2600468661 NM_FCU_SNI 0;
BA_ "GenSigStartValue" SG_ 2600468661 NM_FCU_SNI 181;
BA_ "GenSigSwitchedByIgnition" SG_ 2600468661 NM_FCU_CBV_AWB 0;
BA_ "GenSigSwitchedByIgnition" SG_ 2600468661 NM_FCU_CBV_CRI 0;
BA_ "GenSigSwitchedByIgnition" SG_ 2600468661 NM_FCU_NM_State 0;
BA_ "GenSigSwitchedByIgnition" SG_ 2600468661 NM_FCU_Car_Wakeup 0;
BA_ "GenSigSendType" SG_ 2600468661 NM_FCU_Car_Wakeup 3;
BA_ "GenSigSwitchedByIgnition" SG_ 2600468661 NM_FCU_UDS_CC 0;
BA_ "GenSigSwitchedByIgnition" SG_ 2600468661 NM_FCU_NM_aktiv_KL15 0;
BA_ "GenSigSwitchedByIgnition" SG_ 2600468661 NM_FCU_NM_aktiv_Diag 0;
BA_ "GenSigSwitchedByIgnition" SG_ 2600468661 NM_FCU_NM_aktiv_Tmin 0;
BA_ "GenSigSwitchedByIgnition" SG_ 2600468661 NM_FCU_NM_aktiv_Shutdown 0;
BA_ "GenSigSwitchedByIgnition" SG_ 2600468661 NM_FCU_NM_aktiv_HCAN 0;
BA_ "GenSigSwitchedByIgnition" SG_ 2600468661 NM_FCU_NM_aktiv_Tankvorgang 0;
BA_ "GenSigSwitchedByIgnition" SG_ 2600468661 NM_FCU_CAB 0;
BA_ "GenSigSendType" SG_ 2600468661 NM_FCU_CAB 4;
BA_ "GenSigActiveRepetitions" SG_ 2600468661 NM_FCU_CAB 3;
BA_ "GenSigSwitchedByIgnition" SG_ 2600468496 NM_Gateway_SNI 0;
BA_ "GenSigStartValue" SG_ 2600468496 NM_Gateway_SNI 16;
BA_ "GenSigSwitchedByIgnition" SG_ 2600468496 NM_Gateway_CBV_AWB 0;
BA_ "GenSigSwitchedByIgnition" SG_ 2600468496 NM_Gateway_CBV_CRI 0;
BA_ "GenSigSwitchedByIgnition" SG_ 2600468496 NM_Gateway_NM_State 0;
BA_ "GenSigSwitchedByIgnition" SG_ 2600468496 NM_Gateway_Car_Wakeup 0;
BA_ "GenSigSendType" SG_ 2600468496 NM_Gateway_Car_Wakeup 3;
BA_ "GenSigSwitchedByIgnition" SG_ 2600468496 NM_Gateway_UDS_CC 0;
BA_ "GenSigSwitchedByIgnition" SG_ 2600468496 NM_Gateway_NM_aktiv_KL15 0;
BA_ "GenSigSwitchedByIgnition" SG_ 2600468496 NM_Gateway_NM_aktiv_Diagnose 0;
BA_ "GenSigSwitchedByIgnition" SG_ 2600468496 NM_Gateway_NM_aktiv_Tmin 0;
BA_ "GenSigSwitchedByIgnition" SG_ 2600468496 NM_Gateway_NM_aktiv_CWU 0;
BA_ "GenSigSwitchedByIgnition" SG_ 2600468496 NM_Gateway_NM_aktiv_FC 0;
BA_ "GenSigSwitchedByIgnition" SG_ 2600468496 NM_Gateway_NM_aktiv_Connect 0;
BA_ "GenSigSwitchedByIgnition" SG_ 2600468496 NM_Gateway_NM_aktiv_EM 0;
BA_ "GenSigSwitchedByIgnition" SG_ 2600468496 NM_Gateway_NM_aktiv_OBDC 0;
BA_ "GenSigSwitchedByIgnition" SG_ 2600468496 NM_Gateway_NM_aktiv_Buskopplung 0;
BA_ "GenSigSwitchedByIgnition" SG_ 2600468496 NM_Gateway_NM_aktiv_LIN2 0;
BA_ "GenSigSwitchedByIgnition" SG_ 2600468496 NM_Gateway_CAB 0;
BA_ "GenSigSendType" SG_ 2600468496 NM_Gateway_CAB 4;
BA_ "GenSigActiveRepetitions" SG_ 2600468496 NM_Gateway_CAB 3;
BA_ "GenSigSwitchedByIgnition" SG_ 2600468603 NM_Hybrid_01_SNI 0;
BA_ "GenSigStartValue" SG_ 2600468603 NM_Hybrid_01_SNI 123;
BA_ "GenSigSwitchedByIgnition" SG_ 2600468603 NM_Hybrid_01_CBV_AWB 0;
BA_ "GenSigSwitchedByIgnition" SG_ 2600468603 NM_Hybrid_01_CBV_CRI 0;
BA_ "GenSigFuncType" SG_ 2600468603 NM_Hybrid_01_CBV_CRI 8;
BA_ "GenSigSwitchedByIgnition" SG_ 2600468603 NM_Hybrid_01_NM_State 0;
BA_ "GenSigSwitchedByIgnition" SG_ 2600468603 NM_Hybrid_01_Car_Wakeup 0;
BA_ "GenSigSendType" SG_ 2600468603 NM_Hybrid_01_Car_Wakeup 3;
BA_ "GenSigSwitchedByIgnition" SG_ 2600468603 NM_Hybrid_01_UDS_CC 0;
BA_ "GenSigSwitchedByIgnition" SG_ 2600468603 NM_Hybrid_01_NM_aktiv_KL15 0;
BA_ "GenSigSwitchedByIgnition" SG_ 2600468603 NM_Hybrid_01_NM_aktiv_Diagnose 0;
BA_ "GenSigSwitchedByIgnition" SG_ 2600468603 NM_Hybrid_01_NM_aktiv_Tmin 0;
BA_ "GenSigSwitchedByIgnition" SG_ 2600468603 NM_Hybrid_01_NM_aktiv_Hochvolt 0;
BA_ "GenSigSwitchedByIgnition" SG_ 2600468603 NM_BMC_NM_aktiv_HCAN 0;
BA_ "GenSigSwitchedByIgnition" SG_ 2600468603 NM_Hybrid_01_CAB 0;
BA_ "GenSigSendType" SG_ 2600468603 NM_Hybrid_01_CAB 4;
BA_ "GenSigActiveRepetitions" SG_ 2600468603 NM_Hybrid_01_CAB 3;
BA_ "GenSigSwitchedByIgnition" SG_ 2600468548 NM_Ladegeraet_SNI 0;
BA_ "GenSigStartValue" SG_ 2600468548 NM_Ladegeraet_SNI 68;
BA_ "GenSigSwitchedByIgnition" SG_ 2600468548 NM_Ladegeraet_CBV_AWB 0;
BA_ "GenSigSwitchedByIgnition" SG_ 2600468548 NM_Ladegeraet_CBV_CRI 0;
BA_ "GenSigFuncType" SG_ 2600468548 NM_Ladegeraet_CBV_CRI 8;
BA_ "GenSigSwitchedByIgnition" SG_ 2600468548 NM_Ladegeraet_NM_State 0;
BA_ "GenSigSwitchedByIgnition" SG_ 2600468548 NM_Ladegeraet_Car_Wakeup 0;
BA_ "GenSigSendType" SG_ 2600468548 NM_Ladegeraet_Car_Wakeup 3;
BA_ "GenSigSwitchedByIgnition" SG_ 2600468548 NM_Ladegeraet_UDS_CC 0;
BA_ "GenSigSwitchedByIgnition" SG_ 2600468548 NM_Ladegeraet_NM_aktiv_Diagnose 0;
BA_ "GenSigSwitchedByIgnition" SG_ 2600468548 NM_Ladegeraet_NM_aktiv_Tmin 0;
BA_ "GenSigSwitchedByIgnition" SG_ 2600468548 NM_Ladegeraet_NM_aktiv_Bere_CVN 0;
BA_ "GenSigSwitchedByIgnition" SG_ 2600468548 NM_Ladegeraet_NM_aktiv_Vorkondit 0;
BA_ "GenSigSwitchedByIgnition" SG_ 2600468548 NM_Ladegeraet_NM_aktiv_CVN_Berec 0;
BA_ "GenSigSwitchedByIgnition" SG_ 2600468548 NM_Ladegeraet_NM_aktiv_NotlaufSt 0;
BA_ "GenSigSwitchedByIgnition" SG_ 2600468548 NM_Ladegeraet_NM_aktiv_Ladezeit 0;
BA_ "GenSigSwitchedByIgnition" SG_ 2600468548 NM_Ladegeraet_NM_aktiv_Laden 0;
BA_ "GenSigSwitchedByIgnition" SG_ 2600468548 NM_Ladegeraet_CAB 0;
BA_ "GenSigSendType" SG_ 2600468548 NM_Ladegeraet_CAB 4;
BA_ "GenSigActiveRepetitions" SG_ 2600468548 NM_Ladegeraet_CAB 3;
BA_ "GenSigSwitchedByIgnition" SG_ 2600468678 NM_Ladegeraet_2_SNI 0;
BA_ "GenSigStartValue" SG_ 2600468678 NM_Ladegeraet_2_SNI 198;
BA_ "GenSigSwitchedByIgnition" SG_ 2600468678 NM_Ladegeraet_2_CBV_AWB 0;
BA_ "GenSigSwitchedByIgnition" SG_ 2600468678 NM_Ladegeraet_2_CBV_CRI 0;
BA_ "GenSigSwitchedByIgnition" SG_ 2600468678 NM_Ladegeraet_2_NM_State 0;
BA_ "GenSigSwitchedByIgnition" SG_ 2600468678 NM_Ladegeraet_2_Car_Wakeup 0;
BA_ "GenSigSendType" SG_ 2600468678 NM_Ladegeraet_2_Car_Wakeup 3;
BA_ "GenSigSwitchedByIgnition" SG_ 2600468678 NM_Ladegeraet_2_UDS_CC 0;
BA_ "GenSigSwitchedByIgnition" SG_ 2600468678 NM_Ladegeraet_2_NM_aktiv_KL15 0;
BA_ "GenSigSwitchedByIgnition" SG_ 2600468678 NM_Ladegeraet_2_NM_aktiv_Diag 0;
BA_ "GenSigSwitchedByIgnition" SG_ 2600468678 NM_Ladegeraet_2_NM_aktiv_Tmin 0;
BA_ "GenSigSwitchedByIgnition" SG_ 2600468678 NM_Ladegeraet_2_NM_aktiv_Laden 0;
BA_ "GenSigSwitchedByIgnition" SG_ 2600468678 NM_Ladegeraet_2_CAB 0;
BA_ "GenSigSendType" SG_ 2600468678 NM_Ladegeraet_2_CAB 4;
BA_ "GenSigActiveRepetitions" SG_ 2600468678 NM_Ladegeraet_2_CAB 3;
BA_ "GenSigSwitchedByIgnition" SG_ 2600468481 NM_Sekundaer_01_SNI 0;
BA_ "GenSigStartValue" SG_ 2600468481 NM_Sekundaer_01_SNI 1;
BA_ "GenSigSwitchedByIgnition" SG_ 2600468481 NM_Sekundaer_01_CBV_AWB 0;
BA_ "GenSigSwitchedByIgnition" SG_ 2600468481 NM_Sekundaer_01_CBV_CRI 0;
BA_ "GenSigSwitchedByIgnition" SG_ 2600468481 NM_Sekundaer_01_NM_State 0;
BA_ "GenSigSwitchedByIgnition" SG_ 2600468481 NM_Sekundaer_01_Car_Wakeup 0;
BA_ "GenSigSendType" SG_ 2600468481 NM_Sekundaer_01_Car_Wakeup 3;
BA_ "GenSigSwitchedByIgnition" SG_ 2600468481 NM_Sekundaer_01_UDS_CC 0;
BA_ "GenSigSwitchedByIgnition" SG_ 2600468481 NM_Sekundaer_01_NM_aktiv_KL15 0;
BA_ "GenSigSwitchedByIgnition" SG_ 2600468481 NM_Sekundaer_01_NM_aktiv_Diag 0;
BA_ "GenSigSwitchedByIgnition" SG_ 2600468481 NM_Sekundaer_01_NM_aktiv_Tmin 0;
BA_ "GenSigSwitchedByIgnition" SG_ 2600468481 NM_Sekundaer_01_NM_aktiv_Anf_HVK 0;
BA_ "GenSigSwitchedByIgnition" SG_ 2600468481 NM_Sekundaer_01_CAB 0;
BA_ "GenSigSendType" SG_ 2600468481 NM_Sekundaer_01_CAB 4;
BA_ "GenSigActiveRepetitions" SG_ 2600468481 NM_Sekundaer_01_CAB 3;
BA_ "GenSigSwitchedByIgnition" SG_ 2600468483 NM_Sekundaer_03_SNI 0;
BA_ "GenSigStartValue" SG_ 2600468483 NM_Sekundaer_03_SNI 3;
BA_ "GenSigSwitchedByIgnition" SG_ 2600468483 NM_Sekundaer_03_CBV_AWB 0;
BA_ "GenSigSwitchedByIgnition" SG_ 2600468483 NM_Sekundaer_03_CBV_CRI 0;
BA_ "GenSigSwitchedByIgnition" SG_ 2600468483 NM_Sekundaer_03_NM_State 0;
BA_ "GenSigSwitchedByIgnition" SG_ 2600468483 NM_Sekundaer_03_Car_Wakeup 0;
BA_ "GenSigSendType" SG_ 2600468483 NM_Sekundaer_03_Car_Wakeup 3;
BA_ "GenSigSwitchedByIgnition" SG_ 2600468483 NM_Sekundaer_03_UDS_CC 0;
BA_ "GenSigSwitchedByIgnition" SG_ 2600468483 NM_Sekundaer_03_NM_aktiv_KL15 0;
BA_ "GenSigSwitchedByIgnition" SG_ 2600468483 NM_Sekundaer_03_NM_aktiv_Diagnos 0;
BA_ "GenSigSwitchedByIgnition" SG_ 2600468483 NM_Sekundaer_03_NM_aktiv_Tmin 0;
BA_ "GenSigSwitchedByIgnition" SG_ 2600468483 NM_Sekundaer_03_NM_aktiv_Anf_HVK 0;
BA_ "GenSigSwitchedByIgnition" SG_ 2600468483 NM_Sekundaer_03_CAB 0;
BA_ "GenSigSendType" SG_ 2600468483 NM_Sekundaer_03_CAB 4;
BA_ "GenSigActiveRepetitions" SG_ 2600468483 NM_Sekundaer_03_CAB 3;
BA_ "GenSigSwitchedByIgnition" SG_ 2600468553 NM_Sub_Gateway_SNI 0;
BA_ "GenSigStartValue" SG_ 2600468553 NM_Sub_Gateway_SNI 73;
BA_ "GenSigSwitchedByIgnition" SG_ 2600468553 NM_Sub_Gateway_CBV_AWB 0;
BA_ "GenSigSwitchedByIgnition" SG_ 2600468553 NM_Sub_Gateway_CBV_CRI 0;
BA_ "GenSigSwitchedByIgnition" SG_ 2600468553 NM_Sub_Gateway_NM_State 0;
BA_ "GenSigSwitchedByIgnition" SG_ 2600468553 NM_Sub_Gateway_Car_Wakeup 0;
BA_ "GenSigSendType" SG_ 2600468553 NM_Sub_Gateway_Car_Wakeup 3;
BA_ "GenSigSwitchedByIgnition" SG_ 2600468553 NM_Sub_Gateway_UDS_CC 0;
BA_ "GenSigSwitchedByIgnition" SG_ 2600468553 NM_Sub_Gateway_NM_aktiv_KL15 0;
BA_ "GenSigSwitchedByIgnition" SG_ 2600468553 NM_Sub_Gateway_NM_aktiv_Diagnose 0;
BA_ "GenSigSwitchedByIgnition" SG_ 2600468553 NM_Sub_Gateway_NM_aktiv_Tmin 0;
BA_ "GenSigSwitchedByIgnition" SG_ 2600468553 NM_Sub_Gateway_CAB 0;
BA_ "GenSigSendType" SG_ 2600468553 NM_Sub_Gateway_CAB 4;
BA_ "GenSigActiveRepetitions" SG_ 2600468553 NM_Sub_Gateway_CAB 3;
BA_REL_ "GenSigTimeoutTime" BU_SG_REL_ Ladegeraet_Konzern SG_ 339 MSG_HYB_30_CRC 2000;
BA_REL_ "GenSigTimeoutTime" BU_SG_REL_ Ladegeraet_Konzern SG_ 339 MSG_HYB_30_BZ 2000;
BA_REL_ "GenSigTimeoutTime" BU_SG_REL_ BMC_MLBevo SG_ 339 MO_ErwGrenzen_Anf 2000;
BA_REL_ "GenSigTimeoutTime" BU_SG_REL_ TME SG_ 339 MO_HVK_AntriebZustand 2000;
BA_REL_ "GenSigTimeoutTime" BU_SG_REL_ Ladegeraet_Konzern SG_ 1434 TME_Dauer_Vorkond_innen 800;
BA_REL_ "GenSigTimeoutTime" BU_SG_REL_ FCU_MLBevo_FCEV SG_ 1434 KL_IstLeistung 800;
BA_REL_ "GenSigTimeoutTime" BU_SG_REL_ Gateway SG_ 1434 KL_IstLeistung 800;
BA_REL_ "GenSigTimeoutTime" BU_SG_REL_ Gateway_PAG SG_ 1434 KL_IstLeistung 800;
BA_REL_ "GenSigTimeoutTime" BU_SG_REL_ Ladegeraet_Konzern SG_ 1434 KL_IstLeistung 800;
BA_REL_ "GenSigTimeoutTime" BU_SG_REL_ Ladegeraet_2 SG_ 689 TME_PlanAntw_Zaehler 500;
BA_REL_ "GenSigTimeoutTime" BU_SG_REL_ Ladegeraet_Konzern SG_ 689 TME_PlanAntw_Zaehler 500;
BA_REL_ "GenSigTimeoutTime" BU_SG_REL_ Gateway SG_ 689 TME_Verbrauch_gesamt_Ueberlauf 500;
BA_REL_ "GenSigTimeoutTime" BU_SG_REL_ Gateway_PAG SG_ 689 TME_Verbrauch_gesamt_Ueberlauf 500;
BA_REL_ "GenSigTimeoutTime" BU_SG_REL_ Gateway SG_ 689 TME_Verbrauch_gesamt 500;
BA_REL_ "GenSigTimeoutTime" BU_SG_REL_ Gateway_PAG SG_ 689 TME_Verbrauch_gesamt 500;
BA_REL_ "GenSigTimeoutTime" BU_SG_REL_ Ladegeraet_Konzern SG_ 689 TME_Energie_Thermo 500;
BA_REL_ "GenSigTimeoutTime" BU_SG_REL_ Ladegeraet_Konzern SG_ 689 TME_Energie_Komfort 500;
BA_REL_ "GenSigTimeoutTime" BU_SG_REL_ DCDC_800V_PAG SG_ 931 MVEM_DC_SollSpannung_MV 800;
BA_REL_ "GenSigTimeoutTime" BU_SG_REL_ DCDC_IHEV SG_ 931 MVEM_DC_SollSpannung_MV 800;
BA_REL_ "GenSigTimeoutTime" BU_SG_REL_ DCDC_800V_PAG SG_ 931 MVEM_DC_SollLeistung_MV 800;
BA_REL_ "GenSigTimeoutTime" BU_SG_REL_ DCDC_IHEV SG_ 931 MVEM_DC_SollLeistung_MV 800;
BA_REL_ "GenSigTimeoutTime" BU_SG_REL_ DCDC_800V_PAG SG_ 2589283456 MVEM_Umin_Funktionsgruppe_A 3200;
BA_REL_ "GenSigTimeoutTime" BU_SG_REL_ DCDC_IHEV SG_ 2589283456 MVEM_Umin_Funktionsgruppe_A 3200;
BA_REL_ "GenSigTimeoutTime" BU_SG_REL_ DCDC_IHEV SG_ 1284 MVK_DCDC_Sollmodus_02 1000;
BA_REL_ "GenSigTimeoutTime" BU_SG_REL_ TME SG_ 1284 MV_Bordnetz_Fehler 1000;
BA_REL_ "GenSigTimeoutTime" BU_SG_REL_ TME SG_ 1284 MVK_MVPTC_Sollmodus 1000;
BA_REL_ "GenSigTimeoutTime" BU_SG_REL_ DCDC_IHEV SG_ 1284 MVK_Istmodus_Anf 1000;
BA_REL_ "GenSigTimeoutTime" BU_SG_REL_ DCDC_800V_PAG SG_ 1284 MVK_MO_EmSollzustand 1000;
BA_REL_ "GenSigTimeoutTime" BU_SG_REL_ DCDC_IHEV SG_ 1284 MVK_MO_EmSollzustand 1000;
BA_REL_ "GenSigTimeoutTime" BU_SG_REL_ DCDC_800V_PAG SG_ 1284 MVK_DCDC_Sollmodus 1000;
BA_REL_ "GenSigTimeoutTime" BU_SG_REL_ DCDC_IHEV SG_ 1284 MVK_DCDC_Sollmodus 1000;
BA_REL_ "GenSigTimeoutTime" BU_SG_REL_ TME SG_ 1157 ND_SatInUse 5000;
BA_REL_ "GenSigTimeoutTime" BU_SG_REL_ TME SG_ 1157 NP_Altitude 5000;
BA_REL_ "GenSigTimeoutTime" BU_SG_REL_ Ladegeraet_Konzern SG_ 1157 ND_UTC 5000;
BA_REL_ "GenSigTimeoutTime" BU_SG_REL_ BMC_MLBevo SG_ 2600468623 NM_AWC_SNI 2000;
BA_REL_ "GenSigTimeoutTime" BU_SG_REL_ BMS_MV SG_ 2600468623 NM_AWC_SNI 2000;
BA_REL_ "GenSigTimeoutTime" BU_SG_REL_ BMS_NV SG_ 2600468623 NM_AWC_SNI 2000;
BA_REL_ "GenSigTimeoutTime" BU_SG_REL_ DCDC_800V_PAG SG_ 2600468623 NM_AWC_SNI 2000;
BA_REL_ "GenSigTimeoutTime" BU_SG_REL_ DCDC_HV SG_ 2600468623 NM_AWC_SNI 2000;
BA_REL_ "GenSigTimeoutTime" BU_SG_REL_ DCDC_HV_02 SG_ 2600468623 NM_AWC_SNI 2000;
BA_REL_ "GenSigTimeoutTime" BU_SG_REL_ DCDC_IHEV SG_ 2600468623 NM_AWC_SNI 2000;
BA_REL_ "GenSigTimeoutTime" BU_SG_REL_ FCU_MLBevo_FCEV SG_ 2600468623 NM_AWC_SNI 2000;
BA_REL_ "GenSigTimeoutTime" BU_SG_REL_ Gateway SG_ 2600468623 NM_AWC_SNI 2000;
BA_REL_ "GenSigTimeoutTime" BU_SG_REL_ Gateway_PAG SG_ 2600468623 NM_AWC_SNI 2000;
BA_REL_ "GenSigTimeoutTime" BU_SG_REL_ Ladegeraet_2 SG_ 2600468623 NM_AWC_SNI 2000;
BA_REL_ "GenSigTimeoutTime" BU_SG_REL_ Ladegeraet_Konzern SG_ 2600468623 NM_AWC_SNI 2000;
BA_REL_ "GenSigTimeoutTime" BU_SG_REL_ LE1 SG_ 2600468623 NM_AWC_SNI 2000;
BA_REL_ "GenSigTimeoutTime" BU_SG_REL_ LE2 SG_ 2600468623 NM_AWC_SNI 2000;
BA_REL_ "GenSigTimeoutTime" BU_SG_REL_ LE_MLBevo SG_ 2600468623 NM_AWC_SNI 2000;
BA_REL_ "GenSigTimeoutTime" BU_SG_REL_ Sub_Gateway SG_ 2600468623 NM_AWC_SNI 2000;
BA_REL_ "GenSigTimeoutTime" BU_SG_REL_ TME SG_ 2600468623 NM_AWC_SNI 2000;
BA_REL_ "GenSigTimeoutTime" BU_SG_REL_ Gateway SG_ 2600468623 NM_AWC_CBV_AWB 2000;
BA_REL_ "GenSigTimeoutTime" BU_SG_REL_ Gateway_PAG SG_ 2600468623 NM_AWC_CBV_AWB 2000;
BA_REL_ "GenSigTimeoutTime" BU_SG_REL_ BMC_MLBevo SG_ 2600468623 NM_AWC_CBV_CRI 2000;
BA_REL_ "GenSigTimeoutTime" BU_SG_REL_ BMS_MV SG_ 2600468623 NM_AWC_CBV_CRI 2000;
BA_REL_ "GenSigTimeoutTime" BU_SG_REL_ BMS_NV SG_ 2600468623 NM_AWC_CBV_CRI 2000;
BA_REL_ "GenSigTimeoutTime" BU_SG_REL_ DCDC_800V_PAG SG_ 2600468623 NM_AWC_CBV_CRI 2000;
BA_REL_ "GenSigTimeoutTime" BU_SG_REL_ DCDC_HV SG_ 2600468623 NM_AWC_CBV_CRI 2000;
BA_REL_ "GenSigTimeoutTime" BU_SG_REL_ DCDC_HV_02 SG_ 2600468623 NM_AWC_CBV_CRI 2000;
BA_REL_ "GenSigTimeoutTime" BU_SG_REL_ DCDC_IHEV SG_ 2600468623 NM_AWC_CBV_CRI 2000;
BA_REL_ "GenSigTimeoutTime" BU_SG_REL_ FCU_MLBevo_FCEV SG_ 2600468623 NM_AWC_CBV_CRI 2000;
BA_REL_ "GenSigTimeoutTime" BU_SG_REL_ Gateway SG_ 2600468623 NM_AWC_CBV_CRI 2000;
BA_REL_ "GenSigTimeoutTime" BU_SG_REL_ Gateway_PAG SG_ 2600468623 NM_AWC_CBV_CRI 2000;
BA_REL_ "GenSigTimeoutTime" BU_SG_REL_ Ladegeraet_2 SG_ 2600468623 NM_AWC_CBV_CRI 2000;
BA_REL_ "GenSigTimeoutTime" BU_SG_REL_ Ladegeraet_Konzern SG_ 2600468623 NM_AWC_CBV_CRI 2000;
BA_REL_ "GenSigTimeoutTime" BU_SG_REL_ LE1 SG_ 2600468623 NM_AWC_CBV_CRI 2000;
BA_REL_ "GenSigTimeoutTime" BU_SG_REL_ LE2 SG_ 2600468623 NM_AWC_CBV_CRI 2000;
BA_REL_ "GenSigTimeoutTime" BU_SG_REL_ LE_MLBevo SG_ 2600468623 NM_AWC_CBV_CRI 2000;
BA_REL_ "GenSigTimeoutTime" BU_SG_REL_ Sub_Gateway SG_ 2600468623 NM_AWC_CBV_CRI 2000;
BA_REL_ "GenSigTimeoutTime" BU_SG_REL_ TME SG_ 2600468623 NM_AWC_CBV_CRI 2000;
BA_REL_ "GenSigTimeoutTime" BU_SG_REL_ Gateway SG_ 2600468623 NM_AWC_Car_Wakeup 2000;
BA_REL_ "GenSigTimeoutTime" BU_SG_REL_ Gateway_PAG SG_ 2600468623 NM_AWC_Car_Wakeup 2000;
BA_REL_ "GenSigTimeoutTime" BU_SG_REL_ BMC_MLBevo SG_ 2600468623 NM_AWC_CAB 2000;
BA_REL_ "GenSigTimeoutTime" BU_SG_REL_ BMS_MV SG_ 2600468623 NM_AWC_CAB 2000;
BA_REL_ "GenSigTimeoutTime" BU_SG_REL_ BMS_NV SG_ 2600468623 NM_AWC_CAB 2000;
BA_REL_ "GenSigTimeoutTime" BU_SG_REL_ DCDC_800V_PAG SG_ 2600468623 NM_AWC_CAB 2000;
BA_REL_ "GenSigTimeoutTime" BU_SG_REL_ DCDC_HV SG_ 2600468623 NM_AWC_CAB 2000;
BA_REL_ "GenSigTimeoutTime" BU_SG_REL_ DCDC_HV_02 SG_ 2600468623 NM_AWC_CAB 2000;
BA_REL_ "GenSigTimeoutTime" BU_SG_REL_ DCDC_IHEV SG_ 2600468623 NM_AWC_CAB 2000;
BA_REL_ "GenSigTimeoutTime" BU_SG_REL_ FCU_MLBevo_FCEV SG_ 2600468623 NM_AWC_CAB 2000;
BA_REL_ "GenSigTimeoutTime" BU_SG_REL_ Gateway SG_ 2600468623 NM_AWC_CAB 2000;
BA_REL_ "GenSigTimeoutTime" BU_SG_REL_ Gateway_PAG SG_ 2600468623 NM_AWC_CAB 2000;
BA_REL_ "GenSigTimeoutTime" BU_SG_REL_ Ladegeraet_2 SG_ 2600468623 NM_AWC_CAB 2000;
BA_REL_ "GenSigTimeoutTime" BU_SG_REL_ Ladegeraet_Konzern SG_ 2600468623 NM_AWC_CAB 2000;
BA_REL_ "GenSigTimeoutTime" BU_SG_REL_ LE1 SG_ 2600468623 NM_AWC_CAB 2000;
BA_REL_ "GenSigTimeoutTime" BU_SG_REL_ LE2 SG_ 2600468623 NM_AWC_CAB 2000;
BA_REL_ "GenSigTimeoutTime" BU_SG_REL_ LE_MLBevo SG_ 2600468623 NM_AWC_CAB 2000;
BA_REL_ "GenSigTimeoutTime" BU_SG_REL_ Sub_Gateway SG_ 2600468623 NM_AWC_CAB 2000;
BA_REL_ "GenSigTimeoutTime" BU_SG_REL_ TME SG_ 2600468623 NM_AWC_CAB 2000;
BA_REL_ "GenSigTimeoutTime" BU_SG_REL_ AWC SG_ 2600468654 NM_BattRegelung_SNI 2000;
BA_REL_ "GenSigTimeoutTime" BU_SG_REL_ BMC_MLBevo SG_ 2600468654 NM_BattRegelung_SNI 2000;
BA_REL_ "GenSigTimeoutTime" BU_SG_REL_ BMS_MV SG_ 2600468654 NM_BattRegelung_SNI 2000;
BA_REL_ "GenSigTimeoutTime" BU_SG_REL_ DCDC_800V_PAG SG_ 2600468654 NM_BattRegelung_SNI 2000;
BA_REL_ "GenSigTimeoutTime" BU_SG_REL_ DCDC_HV SG_ 2600468654 NM_BattRegelung_SNI 2000;
BA_REL_ "GenSigTimeoutTime" BU_SG_REL_ DCDC_HV_02 SG_ 2600468654 NM_BattRegelung_SNI 2000;
BA_REL_ "GenSigTimeoutTime" BU_SG_REL_ DCDC_IHEV SG_ 2600468654 NM_BattRegelung_SNI 2000;
BA_REL_ "GenSigTimeoutTime" BU_SG_REL_ FCU_MLBevo_FCEV SG_ 2600468654 NM_BattRegelung_SNI 2000;
BA_REL_ "GenSigTimeoutTime" BU_SG_REL_ Gateway SG_ 2600468654 NM_BattRegelung_SNI 2000;
BA_REL_ "GenSigTimeoutTime" BU_SG_REL_ Gateway_PAG SG_ 2600468654 NM_BattRegelung_SNI 2000;
BA_REL_ "GenSigTimeoutTime" BU_SG_REL_ Ladegeraet_2 SG_ 2600468654 NM_BattRegelung_SNI 2000;
BA_REL_ "GenSigTimeoutTime" BU_SG_REL_ Ladegeraet_Konzern SG_ 2600468654 NM_BattRegelung_SNI 2000;
BA_REL_ "GenSigTimeoutTime" BU_SG_REL_ LE1 SG_ 2600468654 NM_BattRegelung_SNI 2000;
BA_REL_ "GenSigTimeoutTime" BU_SG_REL_ LE2 SG_ 2600468654 NM_BattRegelung_SNI 2000;
BA_REL_ "GenSigTimeoutTime" BU_SG_REL_ LE2_3_MLBevo_LB SG_ 2600468654 NM_BattRegelung_SNI 2000;
BA_REL_ "GenSigTimeoutTime" BU_SG_REL_ LE_MLBevo SG_ 2600468654 NM_BattRegelung_SNI 2000;
BA_REL_ "GenSigTimeoutTime" BU_SG_REL_ Sub_Gateway SG_ 2600468654 NM_BattRegelung_SNI 2000;
BA_REL_ "GenSigTimeoutTime" BU_SG_REL_ TME SG_ 2600468654 NM_BattRegelung_SNI 2000;
BA_REL_ "GenSigTimeoutTime" BU_SG_REL_ Gateway SG_ 2600468654 NM_BattRegelung_CBV_AWB 2000;
BA_REL_ "GenSigTimeoutTime" BU_SG_REL_ Gateway_PAG SG_ 2600468654 NM_BattRegelung_CBV_AWB 2000;
BA_REL_ "GenSigTimeoutTime" BU_SG_REL_ AWC SG_ 2600468654 NM_BattRegelung_CBV_CRI 2000;
BA_REL_ "GenSigTimeoutTime" BU_SG_REL_ BMC_MLBevo SG_ 2600468654 NM_BattRegelung_CBV_CRI 2000;
BA_REL_ "GenSigTimeoutTime" BU_SG_REL_ BMS_MV SG_ 2600468654 NM_BattRegelung_CBV_CRI 2000;
BA_REL_ "GenSigTimeoutTime" BU_SG_REL_ DCDC_800V_PAG SG_ 2600468654 NM_BattRegelung_CBV_CRI 2000;
BA_REL_ "GenSigTimeoutTime" BU_SG_REL_ DCDC_HV SG_ 2600468654 NM_BattRegelung_CBV_CRI 2000;
BA_REL_ "GenSigTimeoutTime" BU_SG_REL_ DCDC_HV_02 SG_ 2600468654 NM_BattRegelung_CBV_CRI 2000;
BA_REL_ "GenSigTimeoutTime" BU_SG_REL_ DCDC_IHEV SG_ 2600468654 NM_BattRegelung_CBV_CRI 2000;
BA_REL_ "GenSigTimeoutTime" BU_SG_REL_ FCU_MLBevo_FCEV SG_ 2600468654 NM_BattRegelung_CBV_CRI 2000;
BA_REL_ "GenSigTimeoutTime" BU_SG_REL_ Gateway SG_ 2600468654 NM_BattRegelung_CBV_CRI 2000;
BA_REL_ "GenSigTimeoutTime" BU_SG_REL_ Gateway_PAG SG_ 2600468654 NM_BattRegelung_CBV_CRI 2000;
BA_REL_ "GenSigTimeoutTime" BU_SG_REL_ Ladegeraet_2 SG_ 2600468654 NM_BattRegelung_CBV_CRI 2000;
BA_REL_ "GenSigTimeoutTime" BU_SG_REL_ Ladegeraet_Konzern SG_ 2600468654 NM_BattRegelung_CBV_CRI 2000;
BA_REL_ "GenSigTimeoutTime" BU_SG_REL_ LE1 SG_ 2600468654 NM_BattRegelung_CBV_CRI 2000;
BA_REL_ "GenSigTimeoutTime" BU_SG_REL_ LE2 SG_ 2600468654 NM_BattRegelung_CBV_CRI 2000;
BA_REL_ "GenSigTimeoutTime" BU_SG_REL_ LE2_3_MLBevo_LB SG_ 2600468654 NM_BattRegelung_CBV_CRI 2000;
BA_REL_ "GenSigTimeoutTime" BU_SG_REL_ LE_MLBevo SG_ 2600468654 NM_BattRegelung_CBV_CRI 2000;
BA_REL_ "GenSigTimeoutTime" BU_SG_REL_ Sub_Gateway SG_ 2600468654 NM_BattRegelung_CBV_CRI 2000;
BA_REL_ "GenSigTimeoutTime" BU_SG_REL_ TME SG_ 2600468654 NM_BattRegelung_CBV_CRI 2000;
BA_REL_ "GenSigTimeoutTime" BU_SG_REL_ Gateway SG_ 2600468654 NM_BattRegelung_Car_Wakeup 2000;
BA_REL_ "GenSigTimeoutTime" BU_SG_REL_ AWC SG_ 2600468654 NM_BattRegelung_CAB 2000;
BA_REL_ "GenSigTimeoutTime" BU_SG_REL_ BMC_MLBevo SG_ 2600468654 NM_BattRegelung_CAB 2000;
BA_REL_ "GenSigTimeoutTime" BU_SG_REL_ BMS_MV SG_ 2600468654 NM_BattRegelung_CAB 2000;
BA_REL_ "GenSigTimeoutTime" BU_SG_REL_ DCDC_800V_PAG SG_ 2600468654 NM_BattRegelung_CAB 2000;
BA_REL_ "GenSigTimeoutTime" BU_SG_REL_ DCDC_HV SG_ 2600468654 NM_BattRegelung_CAB 2000;
BA_REL_ "GenSigTimeoutTime" BU_SG_REL_ DCDC_HV_02 SG_ 2600468654 NM_BattRegelung_CAB 2000;
BA_REL_ "GenSigTimeoutTime" BU_SG_REL_ DCDC_IHEV SG_ 2600468654 NM_BattRegelung_CAB 2000;
BA_REL_ "GenSigTimeoutTime" BU_SG_REL_ FCU_MLBevo_FCEV SG_ 2600468654 NM_BattRegelung_CAB 2000;
BA_REL_ "GenSigTimeoutTime" BU_SG_REL_ Gateway SG_ 2600468654 NM_BattRegelung_CAB 2000;
BA_REL_ "GenSigTimeoutTime" BU_SG_REL_ Gateway_PAG SG_ 2600468654 NM_BattRegelung_CAB 2000;
BA_REL_ "GenSigTimeoutTime" BU_SG_REL_ Ladegeraet_2 SG_ 2600468654 NM_BattRegelung_CAB 2000;
BA_REL_ "GenSigTimeoutTime" BU_SG_REL_ Ladegeraet_Konzern SG_ 2600468654 NM_BattRegelung_CAB 2000;
BA_REL_ "GenSigTimeoutTime" BU_SG_REL_ LE1 SG_ 2600468654 NM_BattRegelung_CAB 2000;
BA_REL_ "GenSigTimeoutTime" BU_SG_REL_ LE2 SG_ 2600468654 NM_BattRegelung_CAB 2000;
BA_REL_ "GenSigTimeoutTime" BU_SG_REL_ LE2_3_MLBevo_LB SG_ 2600468654 NM_BattRegelung_CAB 2000;
BA_REL_ "GenSigTimeoutTime" BU_SG_REL_ LE_MLBevo SG_ 2600468654 NM_BattRegelung_CAB 2000;
BA_REL_ "GenSigTimeoutTime" BU_SG_REL_ Sub_Gateway SG_ 2600468654 NM_BattRegelung_CAB 2000;
BA_REL_ "GenSigTimeoutTime" BU_SG_REL_ TME SG_ 2600468654 NM_BattRegelung_CAB 2000;
BA_REL_ "GenSigTimeoutTime" BU_SG_REL_ AWC SG_ 2600468636 NM_BMS_48V_SNI 2000;
BA_REL_ "GenSigTimeoutTime" BU_SG_REL_ BMC_MLBevo SG_ 2600468636 NM_BMS_48V_SNI 2000;
BA_REL_ "GenSigTimeoutTime" BU_SG_REL_ BMS_NV SG_ 2600468636 NM_BMS_48V_SNI 2000;
BA_REL_ "GenSigTimeoutTime" BU_SG_REL_ DCDC_800V_PAG SG_ 2600468636 NM_BMS_48V_SNI 2000;
BA_REL_ "GenSigTimeoutTime" BU_SG_REL_ DCDC_HV SG_ 2600468636 NM_BMS_48V_SNI 2000;
BA_REL_ "GenSigTimeoutTime" BU_SG_REL_ DCDC_HV_02 SG_ 2600468636 NM_BMS_48V_SNI 2000;
BA_REL_ "GenSigTimeoutTime" BU_SG_REL_ DCDC_IHEV SG_ 2600468636 NM_BMS_48V_SNI 2000;
BA_REL_ "GenSigTimeoutTime" BU_SG_REL_ Gateway SG_ 2600468636 NM_BMS_48V_SNI 2000;
BA_REL_ "GenSigTimeoutTime" BU_SG_REL_ Gateway_PAG SG_ 2600468636 NM_BMS_48V_SNI 2000;
BA_REL_ "GenSigTimeoutTime" BU_SG_REL_ Ladegeraet_2 SG_ 2600468636 NM_BMS_48V_SNI 2000;
BA_REL_ "GenSigTimeoutTime" BU_SG_REL_ Ladegeraet_Konzern SG_ 2600468636 NM_BMS_48V_SNI 2000;
BA_REL_ "GenSigTimeoutTime" BU_SG_REL_ LE1 SG_ 2600468636 NM_BMS_48V_SNI 2000;
BA_REL_ "GenSigTimeoutTime" BU_SG_REL_ LE2 SG_ 2600468636 NM_BMS_48V_SNI 2000;
BA_REL_ "GenSigTimeoutTime" BU_SG_REL_ LE2_3_MLBevo_LB SG_ 2600468636 NM_BMS_48V_SNI 2000;
BA_REL_ "GenSigTimeoutTime" BU_SG_REL_ LE_MLBevo SG_ 2600468636 NM_BMS_48V_SNI 2000;
BA_REL_ "GenSigTimeoutTime" BU_SG_REL_ Sub_Gateway SG_ 2600468636 NM_BMS_48V_SNI 2000;
BA_REL_ "GenSigTimeoutTime" BU_SG_REL_ TME SG_ 2600468636 NM_BMS_48V_SNI 2000;
BA_REL_ "GenSigTimeoutTime" BU_SG_REL_ Gateway SG_ 2600468636 NM_BMS_48V_CBV_AWB 2000;
BA_REL_ "GenSigTimeoutTime" BU_SG_REL_ Gateway_PAG SG_ 2600468636 NM_BMS_48V_CBV_AWB 2000;
BA_REL_ "GenSigTimeoutTime" BU_SG_REL_ AWC SG_ 2600468636 NM_BMS_48V_CBV_CRI 2000;
BA_REL_ "GenSigTimeoutTime" BU_SG_REL_ BMC_MLBevo SG_ 2600468636 NM_BMS_48V_CBV_CRI 2000;
BA_REL_ "GenSigTimeoutTime" BU_SG_REL_ BMS_NV SG_ 2600468636 NM_BMS_48V_CBV_CRI 2000;
BA_REL_ "GenSigTimeoutTime" BU_SG_REL_ DCDC_800V_PAG SG_ 2600468636 NM_BMS_48V_CBV_CRI 2000;
BA_REL_ "GenSigTimeoutTime" BU_SG_REL_ DCDC_HV SG_ 2600468636 NM_BMS_48V_CBV_CRI 2000;
BA_REL_ "GenSigTimeoutTime" BU_SG_REL_ DCDC_HV_02 SG_ 2600468636 NM_BMS_48V_CBV_CRI 2000;
BA_REL_ "GenSigTimeoutTime" BU_SG_REL_ DCDC_IHEV SG_ 2600468636 NM_BMS_48V_CBV_CRI 2000;
BA_REL_ "GenSigTimeoutTime" BU_SG_REL_ Gateway SG_ 2600468636 NM_BMS_48V_CBV_CRI 2000;
BA_REL_ "GenSigTimeoutTime" BU_SG_REL_ Gateway_PAG SG_ 2600468636 NM_BMS_48V_CBV_CRI 2000;
BA_REL_ "GenSigTimeoutTime" BU_SG_REL_ Ladegeraet_2 SG_ 2600468636 NM_BMS_48V_CBV_CRI 2000;
BA_REL_ "GenSigTimeoutTime" BU_SG_REL_ Ladegeraet_Konzern SG_ 2600468636 NM_BMS_48V_CBV_CRI 2000;
BA_REL_ "GenSigTimeoutTime" BU_SG_REL_ LE1 SG_ 2600468636 NM_BMS_48V_CBV_CRI 2000;
BA_REL_ "GenSigTimeoutTime" BU_SG_REL_ LE2 SG_ 2600468636 NM_BMS_48V_CBV_CRI 2000;
BA_REL_ "GenSigTimeoutTime" BU_SG_REL_ LE2_3_MLBevo_LB SG_ 2600468636 NM_BMS_48V_CBV_CRI 2000;
BA_REL_ "GenSigTimeoutTime" BU_SG_REL_ LE_MLBevo SG_ 2600468636 NM_BMS_48V_CBV_CRI 2000;
BA_REL_ "GenSigTimeoutTime" BU_SG_REL_ Sub_Gateway SG_ 2600468636 NM_BMS_48V_CBV_CRI 2000;
BA_REL_ "GenSigTimeoutTime" BU_SG_REL_ TME SG_ 2600468636 NM_BMS_48V_CBV_CRI 2000;
BA_REL_ "GenSigTimeoutTime" BU_SG_REL_ Gateway SG_ 2600468636 NM_BMS_48V_Car_Wakeup 2000;
BA_REL_ "GenSigTimeoutTime" BU_SG_REL_ Gateway_PAG SG_ 2600468636 NM_BMS_48V_Car_Wakeup 2000;
BA_REL_ "GenSigTimeoutTime" BU_SG_REL_ AWC SG_ 2600468636 NM_BMS_48V_CAB 2000;
BA_REL_ "GenSigTimeoutTime" BU_SG_REL_ BMC_MLBevo SG_ 2600468636 NM_BMS_48V_CAB 2000;
BA_REL_ "GenSigTimeoutTime" BU_SG_REL_ BMS_NV SG_ 2600468636 NM_BMS_48V_CAB 2000;
BA_REL_ "GenSigTimeoutTime" BU_SG_REL_ DCDC_800V_PAG SG_ 2600468636 NM_BMS_48V_CAB 2000;
BA_REL_ "GenSigTimeoutTime" BU_SG_REL_ DCDC_HV SG_ 2600468636 NM_BMS_48V_CAB 2000;
BA_REL_ "GenSigTimeoutTime" BU_SG_REL_ DCDC_HV_02 SG_ 2600468636 NM_BMS_48V_CAB 2000;
BA_REL_ "GenSigTimeoutTime" BU_SG_REL_ DCDC_IHEV SG_ 2600468636 NM_BMS_48V_CAB 2000;
BA_REL_ "GenSigTimeoutTime" BU_SG_REL_ Gateway SG_ 2600468636 NM_BMS_48V_CAB 2000;
BA_REL_ "GenSigTimeoutTime" BU_SG_REL_ Gateway_PAG SG_ 2600468636 NM_BMS_48V_CAB 2000;
BA_REL_ "GenSigTimeoutTime" BU_SG_REL_ Ladegeraet_2 SG_ 2600468636 NM_BMS_48V_CAB 2000;
BA_REL_ "GenSigTimeoutTime" BU_SG_REL_ Ladegeraet_Konzern SG_ 2600468636 NM_BMS_48V_CAB 2000;
BA_REL_ "GenSigTimeoutTime" BU_SG_REL_ LE1 SG_ 2600468636 NM_BMS_48V_CAB 2000;
BA_REL_ "GenSigTimeoutTime" BU_SG_REL_ LE2 SG_ 2600468636 NM_BMS_48V_CAB 2000;
BA_REL_ "GenSigTimeoutTime" BU_SG_REL_ LE2_3_MLBevo_LB SG_ 2600468636 NM_BMS_48V_CAB 2000;
BA_REL_ "GenSigTimeoutTime" BU_SG_REL_ LE_MLBevo SG_ 2600468636 NM_BMS_48V_CAB 2000;
BA_REL_ "GenSigTimeoutTime" BU_SG_REL_ Sub_Gateway SG_ 2600468636 NM_BMS_48V_CAB 2000;
BA_REL_ "GenSigTimeoutTime" BU_SG_REL_ TME SG_ 2600468636 NM_BMS_48V_CAB 2000;
BA_REL_ "GenSigTimeoutTime" BU_SG_REL_ AWC SG_ 2600468545 NM_DCDC_SNI 2000;
BA_REL_ "GenSigTimeoutTime" BU_SG_REL_ BMC_MLBevo SG_ 2600468545 NM_DCDC_SNI 2000;
BA_REL_ "GenSigTimeoutTime" BU_SG_REL_ BMS_MV SG_ 2600468545 NM_DCDC_SNI 2000;
BA_REL_ "GenSigTimeoutTime" BU_SG_REL_ BMS_NV SG_ 2600468545 NM_DCDC_SNI 2000;
BA_REL_ "GenSigTimeoutTime" BU_SG_REL_ DCDC_HV SG_ 2600468545 NM_DCDC_SNI 2000;
BA_REL_ "GenSigTimeoutTime" BU_SG_REL_ DCDC_HV_02 SG_ 2600468545 NM_DCDC_SNI 2000;
BA_REL_ "GenSigTimeoutTime" BU_SG_REL_ FCU_MLBevo_FCEV SG_ 2600468545 NM_DCDC_SNI 2000;
BA_REL_ "GenSigTimeoutTime" BU_SG_REL_ Gateway SG_ 2600468545 NM_DCDC_SNI 2000;
BA_REL_ "GenSigTimeoutTime" BU_SG_REL_ Gateway_PAG SG_ 2600468545 NM_DCDC_SNI 2000;
BA_REL_ "GenSigTimeoutTime" BU_SG_REL_ Ladegeraet_2 SG_ 2600468545 NM_DCDC_SNI 2000;
BA_REL_ "GenSigTimeoutTime" BU_SG_REL_ Ladegeraet_Konzern SG_ 2600468545 NM_DCDC_SNI 2000;
BA_REL_ "GenSigTimeoutTime" BU_SG_REL_ LE1 SG_ 2600468545 NM_DCDC_SNI 2000;
BA_REL_ "GenSigTimeoutTime" BU_SG_REL_ LE2 SG_ 2600468545 NM_DCDC_SNI 2000;
BA_REL_ "GenSigTimeoutTime" BU_SG_REL_ LE2_3_MLBevo_LB SG_ 2600468545 NM_DCDC_SNI 2000;
BA_REL_ "GenSigTimeoutTime" BU_SG_REL_ LE_MLBevo SG_ 2600468545 NM_DCDC_SNI 2000;
BA_REL_ "GenSigTimeoutTime" BU_SG_REL_ Sub_Gateway SG_ 2600468545 NM_DCDC_SNI 2000;
BA_REL_ "GenSigTimeoutTime" BU_SG_REL_ TME SG_ 2600468545 NM_DCDC_SNI 2000;
BA_REL_ "GenSigTimeoutTime" BU_SG_REL_ Gateway SG_ 2600468545 NM_DCDC_CBV_AWB 2000;
BA_REL_ "GenSigTimeoutTime" BU_SG_REL_ Gateway_PAG SG_ 2600468545 NM_DCDC_CBV_AWB 2000;
BA_REL_ "GenSigTimeoutTime" BU_SG_REL_ AWC SG_ 2600468545 NM_DCDC_CBV_CRI 2000;
BA_REL_ "GenSigTimeoutTime" BU_SG_REL_ BMC_MLBevo SG_ 2600468545 NM_DCDC_CBV_CRI 2000;
BA_REL_ "GenSigTimeoutTime" BU_SG_REL_ BMS_MV SG_ 2600468545 NM_DCDC_CBV_CRI 2000;
BA_REL_ "GenSigTimeoutTime" BU_SG_REL_ BMS_NV SG_ 2600468545 NM_DCDC_CBV_CRI 2000;
BA_REL_ "GenSigTimeoutTime" BU_SG_REL_ DCDC_HV SG_ 2600468545 NM_DCDC_CBV_CRI 2000;
BA_REL_ "GenSigTimeoutTime" BU_SG_REL_ DCDC_HV_02 SG_ 2600468545 NM_DCDC_CBV_CRI 2000;
BA_REL_ "GenSigTimeoutTime" BU_SG_REL_ FCU_MLBevo_FCEV SG_ 2600468545 NM_DCDC_CBV_CRI 2000;
BA_REL_ "GenSigTimeoutTime" BU_SG_REL_ Gateway SG_ 2600468545 NM_DCDC_CBV_CRI 2000;
BA_REL_ "GenSigTimeoutTime" BU_SG_REL_ Gateway_PAG SG_ 2600468545 NM_DCDC_CBV_CRI 2000;
BA_REL_ "GenSigTimeoutTime" BU_SG_REL_ Ladegeraet_2 SG_ 2600468545 NM_DCDC_CBV_CRI 2000;
BA_REL_ "GenSigTimeoutTime" BU_SG_REL_ Ladegeraet_Konzern SG_ 2600468545 NM_DCDC_CBV_CRI 2000;
BA_REL_ "GenSigTimeoutTime" BU_SG_REL_ LE1 SG_ 2600468545 NM_DCDC_CBV_CRI 2000;
BA_REL_ "GenSigTimeoutTime" BU_SG_REL_ LE2 SG_ 2600468545 NM_DCDC_CBV_CRI 2000;
BA_REL_ "GenSigTimeoutTime" BU_SG_REL_ LE2_3_MLBevo_LB SG_ 2600468545 NM_DCDC_CBV_CRI 2000;
BA_REL_ "GenSigTimeoutTime" BU_SG_REL_ LE_MLBevo SG_ 2600468545 NM_DCDC_CBV_CRI 2000;
BA_REL_ "GenSigTimeoutTime" BU_SG_REL_ Sub_Gateway SG_ 2600468545 NM_DCDC_CBV_CRI 2000;
BA_REL_ "GenSigTimeoutTime" BU_SG_REL_ TME SG_ 2600468545 NM_DCDC_CBV_CRI 2000;
BA_REL_ "GenSigTimeoutTime" BU_SG_REL_ Gateway SG_ 2600468545 NM_DCDC_Car_Wakeup 2000;
BA_REL_ "GenSigTimeoutTime" BU_SG_REL_ AWC SG_ 2600468545 NM_DCDC_CAB 2000;
BA_REL_ "GenSigTimeoutTime" BU_SG_REL_ BMC_MLBevo SG_ 2600468545 NM_DCDC_CAB 2000;
BA_REL_ "GenSigTimeoutTime" BU_SG_REL_ BMS_MV SG_ 2600468545 NM_DCDC_CAB 2000;
BA_REL_ "GenSigTimeoutTime" BU_SG_REL_ BMS_NV SG_ 2600468545 NM_DCDC_CAB 2000;
BA_REL_ "GenSigTimeoutTime" BU_SG_REL_ DCDC_HV SG_ 2600468545 NM_DCDC_CAB 2000;
BA_REL_ "GenSigTimeoutTime" BU_SG_REL_ DCDC_HV_02 SG_ 2600468545 NM_DCDC_CAB 2000;
BA_REL_ "GenSigTimeoutTime" BU_SG_REL_ FCU_MLBevo_FCEV SG_ 2600468545 NM_DCDC_CAB 2000;
BA_REL_ "GenSigTimeoutTime" BU_SG_REL_ Gateway SG_ 2600468545 NM_DCDC_CAB 2000;
BA_REL_ "GenSigTimeoutTime" BU_SG_REL_ Gateway_PAG SG_ 2600468545 NM_DCDC_CAB 2000;
BA_REL_ "GenSigTimeoutTime" BU_SG_REL_ Ladegeraet_2 SG_ 2600468545 NM_DCDC_CAB 2000;
BA_REL_ "GenSigTimeoutTime" BU_SG_REL_ Ladegeraet_Konzern SG_ 2600468545 NM_DCDC_CAB 2000;
BA_REL_ "GenSigTimeoutTime" BU_SG_REL_ LE1 SG_ 2600468545 NM_DCDC_CAB 2000;
BA_REL_ "GenSigTimeoutTime" BU_SG_REL_ LE2 SG_ 2600468545 NM_DCDC_CAB 2000;
BA_REL_ "GenSigTimeoutTime" BU_SG_REL_ LE2_3_MLBevo_LB SG_ 2600468545 NM_DCDC_CAB 2000;
BA_REL_ "GenSigTimeoutTime" BU_SG_REL_ LE_MLBevo SG_ 2600468545 NM_DCDC_CAB 2000;
BA_REL_ "GenSigTimeoutTime" BU_SG_REL_ Sub_Gateway SG_ 2600468545 NM_DCDC_CAB 2000;
BA_REL_ "GenSigTimeoutTime" BU_SG_REL_ TME SG_ 2600468545 NM_DCDC_CAB 2000;
BA_REL_ "GenSigTimeoutTime" BU_SG_REL_ AWC SG_ 2600468663 NM_DCDC_HV_SNI 2000;
BA_REL_ "GenSigTimeoutTime" BU_SG_REL_ BMC_MLBevo SG_ 2600468663 NM_DCDC_HV_SNI 2000;
BA_REL_ "GenSigTimeoutTime" BU_SG_REL_ BMS_MV SG_ 2600468663 NM_DCDC_HV_SNI 2000;
BA_REL_ "GenSigTimeoutTime" BU_SG_REL_ BMS_NV SG_ 2600468663 NM_DCDC_HV_SNI 2000;
BA_REL_ "GenSigTimeoutTime" BU_SG_REL_ DCDC_HV_02 SG_ 2600468663 NM_DCDC_HV_SNI 2000;
BA_REL_ "GenSigTimeoutTime" BU_SG_REL_ DCDC_IHEV SG_ 2600468663 NM_DCDC_HV_SNI 2000;
BA_REL_ "GenSigTimeoutTime" BU_SG_REL_ Gateway SG_ 2600468663 NM_DCDC_HV_SNI 2000;
BA_REL_ "GenSigTimeoutTime" BU_SG_REL_ Gateway_PAG SG_ 2600468663 NM_DCDC_HV_SNI 2000;
BA_REL_ "GenSigTimeoutTime" BU_SG_REL_ Ladegeraet_2 SG_ 2600468663 NM_DCDC_HV_SNI 2000;
BA_REL_ "GenSigTimeoutTime" BU_SG_REL_ Ladegeraet_Konzern SG_ 2600468663 NM_DCDC_HV_SNI 2000;
BA_REL_ "GenSigTimeoutTime" BU_SG_REL_ LE1 SG_ 2600468663 NM_DCDC_HV_SNI 2000;
BA_REL_ "GenSigTimeoutTime" BU_SG_REL_ LE2 SG_ 2600468663 NM_DCDC_HV_SNI 2000;
BA_REL_ "GenSigTimeoutTime" BU_SG_REL_ LE2_3_MLBevo_LB SG_ 2600468663 NM_DCDC_HV_SNI 2000;
BA_REL_ "GenSigTimeoutTime" BU_SG_REL_ LE_MLBevo SG_ 2600468663 NM_DCDC_HV_SNI 2000;
BA_REL_ "GenSigTimeoutTime" BU_SG_REL_ Sub_Gateway SG_ 2600468663 NM_DCDC_HV_SNI 2000;
BA_REL_ "GenSigTimeoutTime" BU_SG_REL_ TME SG_ 2600468663 NM_DCDC_HV_SNI 2000;
BA_REL_ "GenSigTimeoutTime" BU_SG_REL_ Gateway SG_ 2600468663 NM_DCDC_HV_CBV_AWB 2000;
BA_REL_ "GenSigTimeoutTime" BU_SG_REL_ Gateway_PAG SG_ 2600468663 NM_DCDC_HV_CBV_AWB 2000;
BA_REL_ "GenSigTimeoutTime" BU_SG_REL_ AWC SG_ 2600468663 NM_DCDC_HV_CBV_CRI 2000;
BA_REL_ "GenSigTimeoutTime" BU_SG_REL_ BMC_MLBevo SG_ 2600468663 NM_DCDC_HV_CBV_CRI 2000;
BA_REL_ "GenSigTimeoutTime" BU_SG_REL_ BMS_MV SG_ 2600468663 NM_DCDC_HV_CBV_CRI 2000;
BA_REL_ "GenSigTimeoutTime" BU_SG_REL_ BMS_NV SG_ 2600468663 NM_DCDC_HV_CBV_CRI 2000;
BA_REL_ "GenSigTimeoutTime" BU_SG_REL_ DCDC_HV_02 SG_ 2600468663 NM_DCDC_HV_CBV_CRI 2000;
BA_REL_ "GenSigTimeoutTime" BU_SG_REL_ DCDC_IHEV SG_ 2600468663 NM_DCDC_HV_CBV_CRI 2000;
BA_REL_ "GenSigTimeoutTime" BU_SG_REL_ Gateway SG_ 2600468663 NM_DCDC_HV_CBV_CRI 2000;
BA_REL_ "GenSigTimeoutTime" BU_SG_REL_ Gateway_PAG SG_ 2600468663 NM_DCDC_HV_CBV_CRI 2000;
BA_REL_ "GenSigTimeoutTime" BU_SG_REL_ Ladegeraet_2 SG_ 2600468663 NM_DCDC_HV_CBV_CRI 2000;
BA_REL_ "GenSigTimeoutTime" BU_SG_REL_ Ladegeraet_Konzern SG_ 2600468663 NM_DCDC_HV_CBV_CRI 2000;
BA_REL_ "GenSigTimeoutTime" BU_SG_REL_ LE1 SG_ 2600468663 NM_DCDC_HV_CBV_CRI 2000;
BA_REL_ "GenSigTimeoutTime" BU_SG_REL_ LE2 SG_ 2600468663 NM_DCDC_HV_CBV_CRI 2000;
BA_REL_ "GenSigTimeoutTime" BU_SG_REL_ LE2_3_MLBevo_LB SG_ 2600468663 NM_DCDC_HV_CBV_CRI 2000;
BA_REL_ "GenSigTimeoutTime" BU_SG_REL_ LE_MLBevo SG_ 2600468663 NM_DCDC_HV_CBV_CRI 2000;
BA_REL_ "GenSigTimeoutTime" BU_SG_REL_ Sub_Gateway SG_ 2600468663 NM_DCDC_HV_CBV_CRI 2000;
BA_REL_ "GenSigTimeoutTime" BU_SG_REL_ TME SG_ 2600468663 NM_DCDC_HV_CBV_CRI 2000;
BA_REL_ "GenSigTimeoutTime" BU_SG_REL_ Gateway SG_ 2600468663 NM_DCDC_HV_Car_Wakeup 2000;
BA_REL_ "GenSigTimeoutTime" BU_SG_REL_ Gateway_PAG SG_ 2600468663 NM_DCDC_HV_Car_Wakeup 2000;
BA_REL_ "GenSigTimeoutTime" BU_SG_REL_ AWC SG_ 2600468663 NM_DCDC_HV_CAB 2000;
BA_REL_ "GenSigTimeoutTime" BU_SG_REL_ BMC_MLBevo SG_ 2600468663 NM_DCDC_HV_CAB 2000;
BA_REL_ "GenSigTimeoutTime" BU_SG_REL_ BMS_MV SG_ 2600468663 NM_DCDC_HV_CAB 2000;
BA_REL_ "GenSigTimeoutTime" BU_SG_REL_ BMS_NV SG_ 2600468663 NM_DCDC_HV_CAB 2000;
BA_REL_ "GenSigTimeoutTime" BU_SG_REL_ DCDC_HV_02 SG_ 2600468663 NM_DCDC_HV_CAB 2000;
BA_REL_ "GenSigTimeoutTime" BU_SG_REL_ DCDC_IHEV SG_ 2600468663 NM_DCDC_HV_CAB 2000;
BA_REL_ "GenSigTimeoutTime" BU_SG_REL_ Gateway SG_ 2600468663 NM_DCDC_HV_CAB 2000;
BA_REL_ "GenSigTimeoutTime" BU_SG_REL_ Gateway_PAG SG_ 2600468663 NM_DCDC_HV_CAB 2000;
BA_REL_ "GenSigTimeoutTime" BU_SG_REL_ Ladegeraet_2 SG_ 2600468663 NM_DCDC_HV_CAB 2000;
BA_REL_ "GenSigTimeoutTime" BU_SG_REL_ Ladegeraet_Konzern SG_ 2600468663 NM_DCDC_HV_CAB 2000;
BA_REL_ "GenSigTimeoutTime" BU_SG_REL_ LE1 SG_ 2600468663 NM_DCDC_HV_CAB 2000;
BA_REL_ "GenSigTimeoutTime" BU_SG_REL_ LE2 SG_ 2600468663 NM_DCDC_HV_CAB 2000;
BA_REL_ "GenSigTimeoutTime" BU_SG_REL_ LE2_3_MLBevo_LB SG_ 2600468663 NM_DCDC_HV_CAB 2000;
BA_REL_ "GenSigTimeoutTime" BU_SG_REL_ LE_MLBevo SG_ 2600468663 NM_DCDC_HV_CAB 2000;
BA_REL_ "GenSigTimeoutTime" BU_SG_REL_ Sub_Gateway SG_ 2600468663 NM_DCDC_HV_CAB 2000;
BA_REL_ "GenSigTimeoutTime" BU_SG_REL_ TME SG_ 2600468663 NM_DCDC_HV_CAB 2000;
BA_REL_ "GenSigTimeoutTime" BU_SG_REL_ AWC SG_ 2600468679 NM_DCDC_HV_02_SNI 2000;
BA_REL_ "GenSigTimeoutTime" BU_SG_REL_ BMC_MLBevo SG_ 2600468679 NM_DCDC_HV_02_SNI 2000;
BA_REL_ "GenSigTimeoutTime" BU_SG_REL_ BMS_MV SG_ 2600468679 NM_DCDC_HV_02_SNI 2000;
BA_REL_ "GenSigTimeoutTime" BU_SG_REL_ BMS_NV SG_ 2600468679 NM_DCDC_HV_02_SNI 2000;
BA_REL_ "GenSigTimeoutTime" BU_SG_REL_ DCDC_800V_PAG SG_ 2600468679 NM_DCDC_HV_02_SNI 2000;
BA_REL_ "GenSigTimeoutTime" BU_SG_REL_ DCDC_HV SG_ 2600468679 NM_DCDC_HV_02_SNI 2000;
BA_REL_ "GenSigTimeoutTime" BU_SG_REL_ DCDC_IHEV SG_ 2600468679 NM_DCDC_HV_02_SNI 2000;
BA_REL_ "GenSigTimeoutTime" BU_SG_REL_ FCU_MLBevo_FCEV SG_ 2600468679 NM_DCDC_HV_02_SNI 2000;
BA_REL_ "GenSigTimeoutTime" BU_SG_REL_ Gateway SG_ 2600468679 NM_DCDC_HV_02_SNI 2000;
BA_REL_ "GenSigTimeoutTime" BU_SG_REL_ Gateway_PAG SG_ 2600468679 NM_DCDC_HV_02_SNI 2000;
BA_REL_ "GenSigTimeoutTime" BU_SG_REL_ Ladegeraet_2 SG_ 2600468679 NM_DCDC_HV_02_SNI 2000;
BA_REL_ "GenSigTimeoutTime" BU_SG_REL_ Ladegeraet_Konzern SG_ 2600468679 NM_DCDC_HV_02_SNI 2000;
BA_REL_ "GenSigTimeoutTime" BU_SG_REL_ LE1 SG_ 2600468679 NM_DCDC_HV_02_SNI 2000;
BA_REL_ "GenSigTimeoutTime" BU_SG_REL_ LE2 SG_ 2600468679 NM_DCDC_HV_02_SNI 2000;
BA_REL_ "GenSigTimeoutTime" BU_SG_REL_ LE2_3_MLBevo_LB SG_ 2600468679 NM_DCDC_HV_02_SNI 2000;
BA_REL_ "GenSigTimeoutTime" BU_SG_REL_ LE_MLBevo SG_ 2600468679 NM_DCDC_HV_02_SNI 2000;
BA_REL_ "GenSigTimeoutTime" BU_SG_REL_ Sub_Gateway SG_ 2600468679 NM_DCDC_HV_02_SNI 2000;
BA_REL_ "GenSigTimeoutTime" BU_SG_REL_ TME SG_ 2600468679 NM_DCDC_HV_02_SNI 2000;
BA_REL_ "GenSigTimeoutTime" BU_SG_REL_ Gateway SG_ 2600468679 NM_DCDC_HV_02_CBV_AWB 2000;
BA_REL_ "GenSigTimeoutTime" BU_SG_REL_ Gateway_PAG SG_ 2600468679 NM_DCDC_HV_02_CBV_AWB 2000;
BA_REL_ "GenSigTimeoutTime" BU_SG_REL_ AWC SG_ 2600468679 NM_DCDC_HV_02_CBV_CRI 2000;
BA_REL_ "GenSigTimeoutTime" BU_SG_REL_ BMC_MLBevo SG_ 2600468679 NM_DCDC_HV_02_CBV_CRI 2000;
BA_REL_ "GenSigTimeoutTime" BU_SG_REL_ BMS_MV SG_ 2600468679 NM_DCDC_HV_02_CBV_CRI 2000;
BA_REL_ "GenSigTimeoutTime" BU_SG_REL_ BMS_NV SG_ 2600468679 NM_DCDC_HV_02_CBV_CRI 2000;
BA_REL_ "GenSigTimeoutTime" BU_SG_REL_ DCDC_800V_PAG SG_ 2600468679 NM_DCDC_HV_02_CBV_CRI 2000;
BA_REL_ "GenSigTimeoutTime" BU_SG_REL_ DCDC_HV SG_ 2600468679 NM_DCDC_HV_02_CBV_CRI 2000;
BA_REL_ "GenSigTimeoutTime" BU_SG_REL_ DCDC_IHEV SG_ 2600468679 NM_DCDC_HV_02_CBV_CRI 2000;
BA_REL_ "GenSigTimeoutTime" BU_SG_REL_ FCU_MLBevo_FCEV SG_ 2600468679 NM_DCDC_HV_02_CBV_CRI 2000;
BA_REL_ "GenSigTimeoutTime" BU_SG_REL_ Gateway SG_ 2600468679 NM_DCDC_HV_02_CBV_CRI 2000;
BA_REL_ "GenSigTimeoutTime" BU_SG_REL_ Gateway_PAG SG_ 2600468679 NM_DCDC_HV_02_CBV_CRI 2000;
BA_REL_ "GenSigTimeoutTime" BU_SG_REL_ Ladegeraet_2 SG_ 2600468679 NM_DCDC_HV_02_CBV_CRI 2000;
BA_REL_ "GenSigTimeoutTime" BU_SG_REL_ Ladegeraet_Konzern SG_ 2600468679 NM_DCDC_HV_02_CBV_CRI 2000;
BA_REL_ "GenSigTimeoutTime" BU_SG_REL_ LE1 SG_ 2600468679 NM_DCDC_HV_02_CBV_CRI 2000;
BA_REL_ "GenSigTimeoutTime" BU_SG_REL_ LE2 SG_ 2600468679 NM_DCDC_HV_02_CBV_CRI 2000;
BA_REL_ "GenSigTimeoutTime" BU_SG_REL_ LE2_3_MLBevo_LB SG_ 2600468679 NM_DCDC_HV_02_CBV_CRI 2000;
BA_REL_ "GenSigTimeoutTime" BU_SG_REL_ LE_MLBevo SG_ 2600468679 NM_DCDC_HV_02_CBV_CRI 2000;
BA_REL_ "GenSigTimeoutTime" BU_SG_REL_ Sub_Gateway SG_ 2600468679 NM_DCDC_HV_02_CBV_CRI 2000;
BA_REL_ "GenSigTimeoutTime" BU_SG_REL_ TME SG_ 2600468679 NM_DCDC_HV_02_CBV_CRI 2000;
BA_REL_ "GenSigTimeoutTime" BU_SG_REL_ Gateway SG_ 2600468679 NM_DCDC_HV_02_Car_Wakeup 2000;
BA_REL_ "GenSigTimeoutTime" BU_SG_REL_ Gateway_PAG SG_ 2600468679 NM_DCDC_HV_02_Car_Wakeup 2000;
BA_REL_ "GenSigTimeoutTime" BU_SG_REL_ AWC SG_ 2600468679 NM_DCDC_HV_02_CAB 2000;
BA_REL_ "GenSigTimeoutTime" BU_SG_REL_ BMC_MLBevo SG_ 2600468679 NM_DCDC_HV_02_CAB 2000;
BA_REL_ "GenSigTimeoutTime" BU_SG_REL_ BMS_MV SG_ 2600468679 NM_DCDC_HV_02_CAB 2000;
BA_REL_ "GenSigTimeoutTime" BU_SG_REL_ BMS_NV SG_ 2600468679 NM_DCDC_HV_02_CAB 2000;
BA_REL_ "GenSigTimeoutTime" BU_SG_REL_ DCDC_800V_PAG SG_ 2600468679 NM_DCDC_HV_02_CAB 2000;
BA_REL_ "GenSigTimeoutTime" BU_SG_REL_ DCDC_HV SG_ 2600468679 NM_DCDC_HV_02_CAB 2000;
BA_REL_ "GenSigTimeoutTime" BU_SG_REL_ DCDC_IHEV SG_ 2600468679 NM_DCDC_HV_02_CAB 2000;
BA_REL_ "GenSigTimeoutTime" BU_SG_REL_ FCU_MLBevo_FCEV SG_ 2600468679 NM_DCDC_HV_02_CAB 2000;
BA_REL_ "GenSigTimeoutTime" BU_SG_REL_ Gateway SG_ 2600468679 NM_DCDC_HV_02_CAB 2000;
BA_REL_ "GenSigTimeoutTime" BU_SG_REL_ Gateway_PAG SG_ 2600468679 NM_DCDC_HV_02_CAB 2000;
BA_REL_ "GenSigTimeoutTime" BU_SG_REL_ Ladegeraet_2 SG_ 2600468679 NM_DCDC_HV_02_CAB 2000;
BA_REL_ "GenSigTimeoutTime" BU_SG_REL_ Ladegeraet_Konzern SG_ 2600468679 NM_DCDC_HV_02_CAB 2000;
BA_REL_ "GenSigTimeoutTime" BU_SG_REL_ LE1 SG_ 2600468679 NM_DCDC_HV_02_CAB 2000;
BA_REL_ "GenSigTimeoutTime" BU_SG_REL_ LE2 SG_ 2600468679 NM_DCDC_HV_02_CAB 2000;
BA_REL_ "GenSigTimeoutTime" BU_SG_REL_ LE2_3_MLBevo_LB SG_ 2600468679 NM_DCDC_HV_02_CAB 2000;
BA_REL_ "GenSigTimeoutTime" BU_SG_REL_ LE_MLBevo SG_ 2600468679 NM_DCDC_HV_02_CAB 2000;
BA_REL_ "GenSigTimeoutTime" BU_SG_REL_ Sub_Gateway SG_ 2600468679 NM_DCDC_HV_02_CAB 2000;
BA_REL_ "GenSigTimeoutTime" BU_SG_REL_ TME SG_ 2600468679 NM_DCDC_HV_02_CAB 2000;
BA_REL_ "GenSigTimeoutTime" BU_SG_REL_ Gateway SG_ 2600468661 NM_FCU_SNI 2000;
BA_REL_ "GenSigTimeoutTime" BU_SG_REL_ Gateway SG_ 2600468661 NM_FCU_CBV_CRI 2000;
BA_REL_ "GenSigTimeoutTime" BU_SG_REL_ Gateway SG_ 2600468661 NM_FCU_Car_Wakeup 2000;
BA_REL_ "GenSigTimeoutTime" BU_SG_REL_ Gateway SG_ 2600468661 NM_FCU_CAB 2000;
BA_REL_ "GenSigTimeoutTime" BU_SG_REL_ AWC SG_ 2600468496 NM_Gateway_SNI 2000;
BA_REL_ "GenSigTimeoutTime" BU_SG_REL_ BMC_MLBevo SG_ 2600468496 NM_Gateway_SNI 2000;
BA_REL_ "GenSigTimeoutTime" BU_SG_REL_ BMS_MV SG_ 2600468496 NM_Gateway_SNI 2000;
BA_REL_ "GenSigTimeoutTime" BU_SG_REL_ BMS_NV SG_ 2600468496 NM_Gateway_SNI 2000;
BA_REL_ "GenSigTimeoutTime" BU_SG_REL_ DCDC_800V_PAG SG_ 2600468496 NM_Gateway_SNI 2000;
BA_REL_ "GenSigTimeoutTime" BU_SG_REL_ DCDC_HV SG_ 2600468496 NM_Gateway_SNI 2000;
BA_REL_ "GenSigTimeoutTime" BU_SG_REL_ DCDC_HV_02 SG_ 2600468496 NM_Gateway_SNI 2000;
BA_REL_ "GenSigTimeoutTime" BU_SG_REL_ DCDC_IHEV SG_ 2600468496 NM_Gateway_SNI 2000;
BA_REL_ "GenSigTimeoutTime" BU_SG_REL_ FCU_MLBevo_FCEV SG_ 2600468496 NM_Gateway_SNI 2000;
BA_REL_ "GenSigTimeoutTime" BU_SG_REL_ Ladegeraet_2 SG_ 2600468496 NM_Gateway_SNI 2000;
BA_REL_ "GenSigTimeoutTime" BU_SG_REL_ Ladegeraet_Konzern SG_ 2600468496 NM_Gateway_SNI 2000;
BA_REL_ "GenSigTimeoutTime" BU_SG_REL_ LE1 SG_ 2600468496 NM_Gateway_SNI 2000;
BA_REL_ "GenSigTimeoutTime" BU_SG_REL_ LE2 SG_ 2600468496 NM_Gateway_SNI 2000;
BA_REL_ "GenSigTimeoutTime" BU_SG_REL_ LE2_3_MLBevo_LB SG_ 2600468496 NM_Gateway_SNI 2000;
BA_REL_ "GenSigTimeoutTime" BU_SG_REL_ LE_MLBevo SG_ 2600468496 NM_Gateway_SNI 2000;
BA_REL_ "GenSigTimeoutTime" BU_SG_REL_ Sub_Gateway SG_ 2600468496 NM_Gateway_SNI 2000;
BA_REL_ "GenSigTimeoutTime" BU_SG_REL_ TME SG_ 2600468496 NM_Gateway_SNI 2000;
BA_REL_ "GenSigTimeoutTime" BU_SG_REL_ AWC SG_ 2600468496 NM_Gateway_CBV_CRI 2000;
BA_REL_ "GenSigTimeoutTime" BU_SG_REL_ BMC_MLBevo SG_ 2600468496 NM_Gateway_CBV_CRI 2000;
BA_REL_ "GenSigTimeoutTime" BU_SG_REL_ BMS_MV SG_ 2600468496 NM_Gateway_CBV_CRI 2000;
BA_REL_ "GenSigTimeoutTime" BU_SG_REL_ BMS_NV SG_ 2600468496 NM_Gateway_CBV_CRI 2000;
BA_REL_ "GenSigTimeoutTime" BU_SG_REL_ DCDC_800V_PAG SG_ 2600468496 NM_Gateway_CBV_CRI 2000;
BA_REL_ "GenSigTimeoutTime" BU_SG_REL_ DCDC_HV SG_ 2600468496 NM_Gateway_CBV_CRI 2000;
BA_REL_ "GenSigTimeoutTime" BU_SG_REL_ DCDC_HV_02 SG_ 2600468496 NM_Gateway_CBV_CRI 2000;
BA_REL_ "GenSigTimeoutTime" BU_SG_REL_ DCDC_IHEV SG_ 2600468496 NM_Gateway_CBV_CRI 2000;
BA_REL_ "GenSigTimeoutTime" BU_SG_REL_ FCU_MLBevo_FCEV SG_ 2600468496 NM_Gateway_CBV_CRI 2000;
BA_REL_ "GenSigTimeoutTime" BU_SG_REL_ Ladegeraet_2 SG_ 2600468496 NM_Gateway_CBV_CRI 2000;
BA_REL_ "GenSigTimeoutTime" BU_SG_REL_ Ladegeraet_Konzern SG_ 2600468496 NM_Gateway_CBV_CRI 2000;
BA_REL_ "GenSigTimeoutTime" BU_SG_REL_ LE1 SG_ 2600468496 NM_Gateway_CBV_CRI 2000;
BA_REL_ "GenSigTimeoutTime" BU_SG_REL_ LE2 SG_ 2600468496 NM_Gateway_CBV_CRI 2000;
BA_REL_ "GenSigTimeoutTime" BU_SG_REL_ LE2_3_MLBevo_LB SG_ 2600468496 NM_Gateway_CBV_CRI 2000;
BA_REL_ "GenSigTimeoutTime" BU_SG_REL_ LE_MLBevo SG_ 2600468496 NM_Gateway_CBV_CRI 2000;
BA_REL_ "GenSigTimeoutTime" BU_SG_REL_ Sub_Gateway SG_ 2600468496 NM_Gateway_CBV_CRI 2000;
BA_REL_ "GenSigTimeoutTime" BU_SG_REL_ TME SG_ 2600468496 NM_Gateway_CBV_CRI 2000;
BA_REL_ "GenSigTimeoutTime" BU_SG_REL_ AWC SG_ 2600468496 NM_Gateway_CAB 2000;
BA_REL_ "GenSigTimeoutTime" BU_SG_REL_ BMC_MLBevo SG_ 2600468496 NM_Gateway_CAB 2000;
BA_REL_ "GenSigTimeoutTime" BU_SG_REL_ BMS_MV SG_ 2600468496 NM_Gateway_CAB 2000;
BA_REL_ "GenSigTimeoutTime" BU_SG_REL_ BMS_NV SG_ 2600468496 NM_Gateway_CAB 2000;
BA_REL_ "GenSigTimeoutTime" BU_SG_REL_ DCDC_800V_PAG SG_ 2600468496 NM_Gateway_CAB 2000;
BA_REL_ "GenSigTimeoutTime" BU_SG_REL_ DCDC_HV SG_ 2600468496 NM_Gateway_CAB 2000;
BA_REL_ "GenSigTimeoutTime" BU_SG_REL_ DCDC_HV_02 SG_ 2600468496 NM_Gateway_CAB 2000;
BA_REL_ "GenSigTimeoutTime" BU_SG_REL_ DCDC_IHEV SG_ 2600468496 NM_Gateway_CAB 2000;
BA_REL_ "GenSigTimeoutTime" BU_SG_REL_ FCU_MLBevo_FCEV SG_ 2600468496 NM_Gateway_CAB 2000;
BA_REL_ "GenSigTimeoutTime" BU_SG_REL_ Ladegeraet_2 SG_ 2600468496 NM_Gateway_CAB 2000;
BA_REL_ "GenSigTimeoutTime" BU_SG_REL_ Ladegeraet_Konzern SG_ 2600468496 NM_Gateway_CAB 2000;
BA_REL_ "GenSigTimeoutTime" BU_SG_REL_ LE1 SG_ 2600468496 NM_Gateway_CAB 2000;
BA_REL_ "GenSigTimeoutTime" BU_SG_REL_ LE2 SG_ 2600468496 NM_Gateway_CAB 2000;
BA_REL_ "GenSigTimeoutTime" BU_SG_REL_ LE2_3_MLBevo_LB SG_ 2600468496 NM_Gateway_CAB 2000;
BA_REL_ "GenSigTimeoutTime" BU_SG_REL_ LE_MLBevo SG_ 2600468496 NM_Gateway_CAB 2000;
BA_REL_ "GenSigTimeoutTime" BU_SG_REL_ Sub_Gateway SG_ 2600468496 NM_Gateway_CAB 2000;
BA_REL_ "GenSigTimeoutTime" BU_SG_REL_ TME SG_ 2600468496 NM_Gateway_CAB 2000;
BA_REL_ "GenSigTimeoutTime" BU_SG_REL_ AWC SG_ 2600468603 NM_Hybrid_01_SNI 2000;
BA_REL_ "GenSigTimeoutTime" BU_SG_REL_ BMS_MV SG_ 2600468603 NM_Hybrid_01_SNI 2000;
BA_REL_ "GenSigTimeoutTime" BU_SG_REL_ BMS_NV SG_ 2600468603 NM_Hybrid_01_SNI 2000;
BA_REL_ "GenSigTimeoutTime" BU_SG_REL_ DCDC_800V_PAG SG_ 2600468603 NM_Hybrid_01_SNI 2000;
BA_REL_ "GenSigTimeoutTime" BU_SG_REL_ DCDC_HV SG_ 2600468603 NM_Hybrid_01_SNI 2000;
BA_REL_ "GenSigTimeoutTime" BU_SG_REL_ DCDC_HV_02 SG_ 2600468603 NM_Hybrid_01_SNI 2000;
BA_REL_ "GenSigTimeoutTime" BU_SG_REL_ DCDC_IHEV SG_ 2600468603 NM_Hybrid_01_SNI 2000;
BA_REL_ "GenSigTimeoutTime" BU_SG_REL_ FCU_MLBevo_FCEV SG_ 2600468603 NM_Hybrid_01_SNI 2000;
BA_REL_ "GenSigTimeoutTime" BU_SG_REL_ Gateway SG_ 2600468603 NM_Hybrid_01_SNI 2000;
BA_REL_ "GenSigTimeoutTime" BU_SG_REL_ Gateway_PAG SG_ 2600468603 NM_Hybrid_01_SNI 2000;
BA_REL_ "GenSigTimeoutTime" BU_SG_REL_ Ladegeraet_2 SG_ 2600468603 NM_Hybrid_01_SNI 2000;
BA_REL_ "GenSigTimeoutTime" BU_SG_REL_ Ladegeraet_Konzern SG_ 2600468603 NM_Hybrid_01_SNI 2000;
BA_REL_ "GenSigTimeoutTime" BU_SG_REL_ LE1 SG_ 2600468603 NM_Hybrid_01_SNI 2000;
BA_REL_ "GenSigTimeoutTime" BU_SG_REL_ LE2 SG_ 2600468603 NM_Hybrid_01_SNI 2000;
BA_REL_ "GenSigTimeoutTime" BU_SG_REL_ LE2_3_MLBevo_LB SG_ 2600468603 NM_Hybrid_01_SNI 2000;
BA_REL_ "GenSigTimeoutTime" BU_SG_REL_ LE_MLBevo SG_ 2600468603 NM_Hybrid_01_SNI 2000;
BA_REL_ "GenSigTimeoutTime" BU_SG_REL_ Sub_Gateway SG_ 2600468603 NM_Hybrid_01_SNI 2000;
BA_REL_ "GenSigTimeoutTime" BU_SG_REL_ TME SG_ 2600468603 NM_Hybrid_01_SNI 2000;
BA_REL_ "GenSigTimeoutTime" BU_SG_REL_ Gateway SG_ 2600468603 NM_Hybrid_01_CBV_AWB 2000;
BA_REL_ "GenSigTimeoutTime" BU_SG_REL_ Gateway_PAG SG_ 2600468603 NM_Hybrid_01_CBV_AWB 2000;
BA_REL_ "GenSigTimeoutTime" BU_SG_REL_ AWC SG_ 2600468603 NM_Hybrid_01_CBV_CRI 2000;
BA_REL_ "GenSigTimeoutTime" BU_SG_REL_ BMS_MV SG_ 2600468603 NM_Hybrid_01_CBV_CRI 2000;
BA_REL_ "GenSigTimeoutTime" BU_SG_REL_ BMS_NV SG_ 2600468603 NM_Hybrid_01_CBV_CRI 2000;
BA_REL_ "GenSigTimeoutTime" BU_SG_REL_ DCDC_800V_PAG SG_ 2600468603 NM_Hybrid_01_CBV_CRI 2000;
BA_REL_ "GenSigTimeoutTime" BU_SG_REL_ DCDC_HV SG_ 2600468603 NM_Hybrid_01_CBV_CRI 2000;
BA_REL_ "GenSigTimeoutTime" BU_SG_REL_ DCDC_HV_02 SG_ 2600468603 NM_Hybrid_01_CBV_CRI 2000;
BA_REL_ "GenSigTimeoutTime" BU_SG_REL_ DCDC_IHEV SG_ 2600468603 NM_Hybrid_01_CBV_CRI 2000;
BA_REL_ "GenSigTimeoutTime" BU_SG_REL_ FCU_MLBevo_FCEV SG_ 2600468603 NM_Hybrid_01_CBV_CRI 2000;
BA_REL_ "GenSigTimeoutTime" BU_SG_REL_ Gateway SG_ 2600468603 NM_Hybrid_01_CBV_CRI 2000;
BA_REL_ "GenSigTimeoutTime" BU_SG_REL_ Gateway_PAG SG_ 2600468603 NM_Hybrid_01_CBV_CRI 2000;
BA_REL_ "GenSigTimeoutTime" BU_SG_REL_ Ladegeraet_2 SG_ 2600468603 NM_Hybrid_01_CBV_CRI 2000;
BA_REL_ "GenSigTimeoutTime" BU_SG_REL_ Ladegeraet_Konzern SG_ 2600468603 NM_Hybrid_01_CBV_CRI 2000;
BA_REL_ "GenSigTimeoutTime" BU_SG_REL_ LE1 SG_ 2600468603 NM_Hybrid_01_CBV_CRI 2000;
BA_REL_ "GenSigTimeoutTime" BU_SG_REL_ LE2 SG_ 2600468603 NM_Hybrid_01_CBV_CRI 2000;
BA_REL_ "GenSigTimeoutTime" BU_SG_REL_ LE2_3_MLBevo_LB SG_ 2600468603 NM_Hybrid_01_CBV_CRI 2000;
BA_REL_ "GenSigTimeoutTime" BU_SG_REL_ LE_MLBevo SG_ 2600468603 NM_Hybrid_01_CBV_CRI 2000;
BA_REL_ "GenSigTimeoutTime" BU_SG_REL_ Sub_Gateway SG_ 2600468603 NM_Hybrid_01_CBV_CRI 2000;
BA_REL_ "GenSigTimeoutTime" BU_SG_REL_ TME SG_ 2600468603 NM_Hybrid_01_CBV_CRI 2000;
BA_REL_ "GenSigTimeoutTime" BU_SG_REL_ Gateway SG_ 2600468603 NM_Hybrid_01_Car_Wakeup 2000;
BA_REL_ "GenSigTimeoutTime" BU_SG_REL_ AWC SG_ 2600468603 NM_Hybrid_01_CAB 2000;
BA_REL_ "GenSigTimeoutTime" BU_SG_REL_ BMS_MV SG_ 2600468603 NM_Hybrid_01_CAB 2000;
BA_REL_ "GenSigTimeoutTime" BU_SG_REL_ BMS_NV SG_ 2600468603 NM_Hybrid_01_CAB 2000;
BA_REL_ "GenSigTimeoutTime" BU_SG_REL_ DCDC_800V_PAG SG_ 2600468603 NM_Hybrid_01_CAB 2000;
BA_REL_ "GenSigTimeoutTime" BU_SG_REL_ DCDC_HV SG_ 2600468603 NM_Hybrid_01_CAB 2000;
BA_REL_ "GenSigTimeoutTime" BU_SG_REL_ DCDC_HV_02 SG_ 2600468603 NM_Hybrid_01_CAB 2000;
BA_REL_ "GenSigTimeoutTime" BU_SG_REL_ DCDC_IHEV SG_ 2600468603 NM_Hybrid_01_CAB 2000;
BA_REL_ "GenSigTimeoutTime" BU_SG_REL_ FCU_MLBevo_FCEV SG_ 2600468603 NM_Hybrid_01_CAB 2000;
BA_REL_ "GenSigTimeoutTime" BU_SG_REL_ Gateway SG_ 2600468603 NM_Hybrid_01_CAB 2000;
BA_REL_ "GenSigTimeoutTime" BU_SG_REL_ Gateway_PAG SG_ 2600468603 NM_Hybrid_01_CAB 2000;
BA_REL_ "GenSigTimeoutTime" BU_SG_REL_ Ladegeraet_2 SG_ 2600468603 NM_Hybrid_01_CAB 2000;
BA_REL_ "GenSigTimeoutTime" BU_SG_REL_ Ladegeraet_Konzern SG_ 2600468603 NM_Hybrid_01_CAB 2000;
BA_REL_ "GenSigTimeoutTime" BU_SG_REL_ LE1 SG_ 2600468603 NM_Hybrid_01_CAB 2000;
BA_REL_ "GenSigTimeoutTime" BU_SG_REL_ LE2 SG_ 2600468603 NM_Hybrid_01_CAB 2000;
BA_REL_ "GenSigTimeoutTime" BU_SG_REL_ LE2_3_MLBevo_LB SG_ 2600468603 NM_Hybrid_01_CAB 2000;
BA_REL_ "GenSigTimeoutTime" BU_SG_REL_ LE_MLBevo SG_ 2600468603 NM_Hybrid_01_CAB 2000;
BA_REL_ "GenSigTimeoutTime" BU_SG_REL_ Sub_Gateway SG_ 2600468603 NM_Hybrid_01_CAB 2000;
BA_REL_ "GenSigTimeoutTime" BU_SG_REL_ TME SG_ 2600468603 NM_Hybrid_01_CAB 2000;
BA_REL_ "GenSigTimeoutTime" BU_SG_REL_ AWC SG_ 2600468548 NM_Ladegeraet_SNI 2000;
BA_REL_ "GenSigTimeoutTime" BU_SG_REL_ BMC_MLBevo SG_ 2600468548 NM_Ladegeraet_SNI 2000;
BA_REL_ "GenSigTimeoutTime" BU_SG_REL_ BMS_MV SG_ 2600468548 NM_Ladegeraet_SNI 2000;
BA_REL_ "GenSigTimeoutTime" BU_SG_REL_ BMS_NV SG_ 2600468548 NM_Ladegeraet_SNI 2000;
BA_REL_ "GenSigTimeoutTime" BU_SG_REL_ DCDC_800V_PAG SG_ 2600468548 NM_Ladegeraet_SNI 2000;
BA_REL_ "GenSigTimeoutTime" BU_SG_REL_ DCDC_HV SG_ 2600468548 NM_Ladegeraet_SNI 2000;
BA_REL_ "GenSigTimeoutTime" BU_SG_REL_ DCDC_HV_02 SG_ 2600468548 NM_Ladegeraet_SNI 2000;
BA_REL_ "GenSigTimeoutTime" BU_SG_REL_ DCDC_IHEV SG_ 2600468548 NM_Ladegeraet_SNI 2000;
BA_REL_ "GenSigTimeoutTime" BU_SG_REL_ FCU_MLBevo_FCEV SG_ 2600468548 NM_Ladegeraet_SNI 2000;
BA_REL_ "GenSigTimeoutTime" BU_SG_REL_ Gateway SG_ 2600468548 NM_Ladegeraet_SNI 2000;
BA_REL_ "GenSigTimeoutTime" BU_SG_REL_ Gateway_PAG SG_ 2600468548 NM_Ladegeraet_SNI 2000;
BA_REL_ "GenSigTimeoutTime" BU_SG_REL_ Ladegeraet_2 SG_ 2600468548 NM_Ladegeraet_SNI 2000;
BA_REL_ "GenSigTimeoutTime" BU_SG_REL_ LE1 SG_ 2600468548 NM_Ladegeraet_SNI 2000;
BA_REL_ "GenSigTimeoutTime" BU_SG_REL_ LE2 SG_ 2600468548 NM_Ladegeraet_SNI 2000;
BA_REL_ "GenSigTimeoutTime" BU_SG_REL_ LE2_3_MLBevo_LB SG_ 2600468548 NM_Ladegeraet_SNI 2000;
BA_REL_ "GenSigTimeoutTime" BU_SG_REL_ LE_MLBevo SG_ 2600468548 NM_Ladegeraet_SNI 2000;
BA_REL_ "GenSigTimeoutTime" BU_SG_REL_ Sub_Gateway SG_ 2600468548 NM_Ladegeraet_SNI 2000;
BA_REL_ "GenSigTimeoutTime" BU_SG_REL_ TME SG_ 2600468548 NM_Ladegeraet_SNI 2000;
BA_REL_ "GenSigTimeoutTime" BU_SG_REL_ Gateway SG_ 2600468548 NM_Ladegeraet_CBV_AWB 2000;
BA_REL_ "GenSigTimeoutTime" BU_SG_REL_ Gateway_PAG SG_ 2600468548 NM_Ladegeraet_CBV_AWB 2000;
BA_REL_ "GenSigTimeoutTime" BU_SG_REL_ AWC SG_ 2600468548 NM_Ladegeraet_CBV_CRI 2000;
BA_REL_ "GenSigTimeoutTime" BU_SG_REL_ BMC_MLBevo SG_ 2600468548 NM_Ladegeraet_CBV_CRI 2000;
BA_REL_ "GenSigTimeoutTime" BU_SG_REL_ BMS_MV SG_ 2600468548 NM_Ladegeraet_CBV_CRI 2000;
BA_REL_ "GenSigTimeoutTime" BU_SG_REL_ BMS_NV SG_ 2600468548 NM_Ladegeraet_CBV_CRI 2000;
BA_REL_ "GenSigTimeoutTime" BU_SG_REL_ DCDC_800V_PAG SG_ 2600468548 NM_Ladegeraet_CBV_CRI 2000;
BA_REL_ "GenSigTimeoutTime" BU_SG_REL_ DCDC_HV SG_ 2600468548 NM_Ladegeraet_CBV_CRI 2000;
BA_REL_ "GenSigTimeoutTime" BU_SG_REL_ DCDC_HV_02 SG_ 2600468548 NM_Ladegeraet_CBV_CRI 2000;
BA_REL_ "GenSigTimeoutTime" BU_SG_REL_ DCDC_IHEV SG_ 2600468548 NM_Ladegeraet_CBV_CRI 2000;
BA_REL_ "GenSigTimeoutTime" BU_SG_REL_ FCU_MLBevo_FCEV SG_ 2600468548 NM_Ladegeraet_CBV_CRI 2000;
BA_REL_ "GenSigTimeoutTime" BU_SG_REL_ Gateway SG_ 2600468548 NM_Ladegeraet_CBV_CRI 2000;
BA_REL_ "GenSigTimeoutTime" BU_SG_REL_ Gateway_PAG SG_ 2600468548 NM_Ladegeraet_CBV_CRI 2000;
BA_REL_ "GenSigTimeoutTime" BU_SG_REL_ Ladegeraet_2 SG_ 2600468548 NM_Ladegeraet_CBV_CRI 2000;
BA_REL_ "GenSigTimeoutTime" BU_SG_REL_ LE1 SG_ 2600468548 NM_Ladegeraet_CBV_CRI 2000;
BA_REL_ "GenSigTimeoutTime" BU_SG_REL_ LE2 SG_ 2600468548 NM_Ladegeraet_CBV_CRI 2000;
BA_REL_ "GenSigTimeoutTime" BU_SG_REL_ LE2_3_MLBevo_LB SG_ 2600468548 NM_Ladegeraet_CBV_CRI 2000;
BA_REL_ "GenSigTimeoutTime" BU_SG_REL_ LE_MLBevo SG_ 2600468548 NM_Ladegeraet_CBV_CRI 2000;
BA_REL_ "GenSigTimeoutTime" BU_SG_REL_ Sub_Gateway SG_ 2600468548 NM_Ladegeraet_CBV_CRI 2000;
BA_REL_ "GenSigTimeoutTime" BU_SG_REL_ TME SG_ 2600468548 NM_Ladegeraet_CBV_CRI 2000;
BA_REL_ "GenSigTimeoutTime" BU_SG_REL_ Gateway SG_ 2600468548 NM_Ladegeraet_Car_Wakeup 2000;
BA_REL_ "GenSigTimeoutTime" BU_SG_REL_ AWC SG_ 2600468548 NM_Ladegeraet_CAB 2000;
BA_REL_ "GenSigTimeoutTime" BU_SG_REL_ BMC_MLBevo SG_ 2600468548 NM_Ladegeraet_CAB 2000;
BA_REL_ "GenSigTimeoutTime" BU_SG_REL_ BMS_MV SG_ 2600468548 NM_Ladegeraet_CAB 2000;
BA_REL_ "GenSigTimeoutTime" BU_SG_REL_ BMS_NV SG_ 2600468548 NM_Ladegeraet_CAB 2000;
BA_REL_ "GenSigTimeoutTime" BU_SG_REL_ DCDC_800V_PAG SG_ 2600468548 NM_Ladegeraet_CAB 2000;
BA_REL_ "GenSigTimeoutTime" BU_SG_REL_ DCDC_HV SG_ 2600468548 NM_Ladegeraet_CAB 2000;
BA_REL_ "GenSigTimeoutTime" BU_SG_REL_ DCDC_HV_02 SG_ 2600468548 NM_Ladegeraet_CAB 2000;
BA_REL_ "GenSigTimeoutTime" BU_SG_REL_ DCDC_IHEV SG_ 2600468548 NM_Ladegeraet_CAB 2000;
BA_REL_ "GenSigTimeoutTime" BU_SG_REL_ FCU_MLBevo_FCEV SG_ 2600468548 NM_Ladegeraet_CAB 2000;
BA_REL_ "GenSigTimeoutTime" BU_SG_REL_ Gateway SG_ 2600468548 NM_Ladegeraet_CAB 2000;
BA_REL_ "GenSigTimeoutTime" BU_SG_REL_ Gateway_PAG SG_ 2600468548 NM_Ladegeraet_CAB 2000;
BA_REL_ "GenSigTimeoutTime" BU_SG_REL_ Ladegeraet_2 SG_ 2600468548 NM_Ladegeraet_CAB 2000;
BA_REL_ "GenSigTimeoutTime" BU_SG_REL_ LE1 SG_ 2600468548 NM_Ladegeraet_CAB 2000;
BA_REL_ "GenSigTimeoutTime" BU_SG_REL_ LE2 SG_ 2600468548 NM_Ladegeraet_CAB 2000;
BA_REL_ "GenSigTimeoutTime" BU_SG_REL_ LE2_3_MLBevo_LB SG_ 2600468548 NM_Ladegeraet_CAB 2000;
BA_REL_ "GenSigTimeoutTime" BU_SG_REL_ LE_MLBevo SG_ 2600468548 NM_Ladegeraet_CAB 2000;
BA_REL_ "GenSigTimeoutTime" BU_SG_REL_ Sub_Gateway SG_ 2600468548 NM_Ladegeraet_CAB 2000;
BA_REL_ "GenSigTimeoutTime" BU_SG_REL_ TME SG_ 2600468548 NM_Ladegeraet_CAB 2000;
BA_REL_ "GenSigTimeoutTime" BU_SG_REL_ AWC SG_ 2600468678 NM_Ladegeraet_2_SNI 2000;
BA_REL_ "GenSigTimeoutTime" BU_SG_REL_ BMC_MLBevo SG_ 2600468678 NM_Ladegeraet_2_SNI 2000;
BA_REL_ "GenSigTimeoutTime" BU_SG_REL_ BMS_MV SG_ 2600468678 NM_Ladegeraet_2_SNI 2000;
BA_REL_ "GenSigTimeoutTime" BU_SG_REL_ BMS_NV SG_ 2600468678 NM_Ladegeraet_2_SNI 2000;
BA_REL_ "GenSigTimeoutTime" BU_SG_REL_ DCDC_800V_PAG SG_ 2600468678 NM_Ladegeraet_2_SNI 2000;
BA_REL_ "GenSigTimeoutTime" BU_SG_REL_ DCDC_HV SG_ 2600468678 NM_Ladegeraet_2_SNI 2000;
BA_REL_ "GenSigTimeoutTime" BU_SG_REL_ DCDC_HV_02 SG_ 2600468678 NM_Ladegeraet_2_SNI 2000;
BA_REL_ "GenSigTimeoutTime" BU_SG_REL_ DCDC_IHEV SG_ 2600468678 NM_Ladegeraet_2_SNI 2000;
BA_REL_ "GenSigTimeoutTime" BU_SG_REL_ FCU_MLBevo_FCEV SG_ 2600468678 NM_Ladegeraet_2_SNI 2000;
BA_REL_ "GenSigTimeoutTime" BU_SG_REL_ Gateway SG_ 2600468678 NM_Ladegeraet_2_SNI 2000;
BA_REL_ "GenSigTimeoutTime" BU_SG_REL_ Gateway_PAG SG_ 2600468678 NM_Ladegeraet_2_SNI 2000;
BA_REL_ "GenSigTimeoutTime" BU_SG_REL_ Ladegeraet_2 SG_ 2600468678 NM_Ladegeraet_2_SNI 2000;
BA_REL_ "GenSigTimeoutTime" BU_SG_REL_ Ladegeraet_Konzern SG_ 2600468678 NM_Ladegeraet_2_SNI 2000;
BA_REL_ "GenSigTimeoutTime" BU_SG_REL_ LE1 SG_ 2600468678 NM_Ladegeraet_2_SNI 2000;
BA_REL_ "GenSigTimeoutTime" BU_SG_REL_ LE2 SG_ 2600468678 NM_Ladegeraet_2_SNI 2000;
BA_REL_ "GenSigTimeoutTime" BU_SG_REL_ LE2_3_MLBevo_LB SG_ 2600468678 NM_Ladegeraet_2_SNI 2000;
BA_REL_ "GenSigTimeoutTime" BU_SG_REL_ LE_MLBevo SG_ 2600468678 NM_Ladegeraet_2_SNI 2000;
BA_REL_ "GenSigTimeoutTime" BU_SG_REL_ Sub_Gateway SG_ 2600468678 NM_Ladegeraet_2_SNI 2000;
BA_REL_ "GenSigTimeoutTime" BU_SG_REL_ TME SG_ 2600468678 NM_Ladegeraet_2_SNI 2000;
BA_REL_ "GenSigTimeoutTime" BU_SG_REL_ Gateway SG_ 2600468678 NM_Ladegeraet_2_CBV_AWB 2000;
BA_REL_ "GenSigTimeoutTime" BU_SG_REL_ Gateway_PAG SG_ 2600468678 NM_Ladegeraet_2_CBV_AWB 2000;
BA_REL_ "GenSigTimeoutTime" BU_SG_REL_ AWC SG_ 2600468678 NM_Ladegeraet_2_CBV_CRI 2000;
BA_REL_ "GenSigTimeoutTime" BU_SG_REL_ BMC_MLBevo SG_ 2600468678 NM_Ladegeraet_2_CBV_CRI 2000;
BA_REL_ "GenSigTimeoutTime" BU_SG_REL_ BMS_MV SG_ 2600468678 NM_Ladegeraet_2_CBV_CRI 2000;
BA_REL_ "GenSigTimeoutTime" BU_SG_REL_ BMS_NV SG_ 2600468678 NM_Ladegeraet_2_CBV_CRI 2000;
BA_REL_ "GenSigTimeoutTime" BU_SG_REL_ DCDC_800V_PAG SG_ 2600468678 NM_Ladegeraet_2_CBV_CRI 2000;
BA_REL_ "GenSigTimeoutTime" BU_SG_REL_ DCDC_HV SG_ 2600468678 NM_Ladegeraet_2_CBV_CRI 2000;
BA_REL_ "GenSigTimeoutTime" BU_SG_REL_ DCDC_HV_02 SG_ 2600468678 NM_Ladegeraet_2_CBV_CRI 2000;
BA_REL_ "GenSigTimeoutTime" BU_SG_REL_ DCDC_IHEV SG_ 2600468678 NM_Ladegeraet_2_CBV_CRI 2000;
BA_REL_ "GenSigTimeoutTime" BU_SG_REL_ FCU_MLBevo_FCEV SG_ 2600468678 NM_Ladegeraet_2_CBV_CRI 2000;
BA_REL_ "GenSigTimeoutTime" BU_SG_REL_ Gateway SG_ 2600468678 NM_Ladegeraet_2_CBV_CRI 2000;
BA_REL_ "GenSigTimeoutTime" BU_SG_REL_ Gateway_PAG SG_ 2600468678 NM_Ladegeraet_2_CBV_CRI 2000;
BA_REL_ "GenSigTimeoutTime" BU_SG_REL_ Ladegeraet_2 SG_ 2600468678 NM_Ladegeraet_2_CBV_CRI 2000;
BA_REL_ "GenSigTimeoutTime" BU_SG_REL_ Ladegeraet_Konzern SG_ 2600468678 NM_Ladegeraet_2_CBV_CRI 2000;
BA_REL_ "GenSigTimeoutTime" BU_SG_REL_ LE1 SG_ 2600468678 NM_Ladegeraet_2_CBV_CRI 2000;
BA_REL_ "GenSigTimeoutTime" BU_SG_REL_ LE2 SG_ 2600468678 NM_Ladegeraet_2_CBV_CRI 2000;
BA_REL_ "GenSigTimeoutTime" BU_SG_REL_ LE2_3_MLBevo_LB SG_ 2600468678 NM_Ladegeraet_2_CBV_CRI 2000;
BA_REL_ "GenSigTimeoutTime" BU_SG_REL_ LE_MLBevo SG_ 2600468678 NM_Ladegeraet_2_CBV_CRI 2000;
BA_REL_ "GenSigTimeoutTime" BU_SG_REL_ Sub_Gateway SG_ 2600468678 NM_Ladegeraet_2_CBV_CRI 2000;
BA_REL_ "GenSigTimeoutTime" BU_SG_REL_ TME SG_ 2600468678 NM_Ladegeraet_2_CBV_CRI 2000;
BA_REL_ "GenSigTimeoutTime" BU_SG_REL_ Gateway SG_ 2600468678 NM_Ladegeraet_2_Car_Wakeup 2000;
BA_REL_ "GenSigTimeoutTime" BU_SG_REL_ Gateway_PAG SG_ 2600468678 NM_Ladegeraet_2_Car_Wakeup 2000;
BA_REL_ "GenSigTimeoutTime" BU_SG_REL_ Gateway SG_ 2600468678 NM_Ladegeraet_2_UDS_CC 2000;
BA_REL_ "GenSigTimeoutTime" BU_SG_REL_ Gateway_PAG SG_ 2600468678 NM_Ladegeraet_2_UDS_CC 2000;
BA_REL_ "GenSigTimeoutTime" BU_SG_REL_ Gateway_PAG SG_ 2600468678 NM_Ladegeraet_2_NM_aktiv_Tmin 2000;
BA_REL_ "GenSigTimeoutTime" BU_SG_REL_ AWC SG_ 2600468678 NM_Ladegeraet_2_CAB 2000;
BA_REL_ "GenSigTimeoutTime" BU_SG_REL_ BMC_MLBevo SG_ 2600468678 NM_Ladegeraet_2_CAB 2000;
BA_REL_ "GenSigTimeoutTime" BU_SG_REL_ BMS_MV SG_ 2600468678 NM_Ladegeraet_2_CAB 2000;
BA_REL_ "GenSigTimeoutTime" BU_SG_REL_ BMS_NV SG_ 2600468678 NM_Ladegeraet_2_CAB 2000;
BA_REL_ "GenSigTimeoutTime" BU_SG_REL_ DCDC_800V_PAG SG_ 2600468678 NM_Ladegeraet_2_CAB 2000;
BA_REL_ "GenSigTimeoutTime" BU_SG_REL_ DCDC_HV SG_ 2600468678 NM_Ladegeraet_2_CAB 2000;
BA_REL_ "GenSigTimeoutTime" BU_SG_REL_ DCDC_HV_02 SG_ 2600468678 NM_Ladegeraet_2_CAB 2000;
BA_REL_ "GenSigTimeoutTime" BU_SG_REL_ DCDC_IHEV SG_ 2600468678 NM_Ladegeraet_2_CAB 2000;
BA_REL_ "GenSigTimeoutTime" BU_SG_REL_ FCU_MLBevo_FCEV SG_ 2600468678 NM_Ladegeraet_2_CAB 2000;
BA_REL_ "GenSigTimeoutTime" BU_SG_REL_ Gateway SG_ 2600468678 NM_Ladegeraet_2_CAB 2000;
BA_REL_ "GenSigTimeoutTime" BU_SG_REL_ Gateway_PAG SG_ 2600468678 NM_Ladegeraet_2_CAB 2000;
BA_REL_ "GenSigTimeoutTime" BU_SG_REL_ Ladegeraet_2 SG_ 2600468678 NM_Ladegeraet_2_CAB 2000;
BA_REL_ "GenSigTimeoutTime" BU_SG_REL_ Ladegeraet_Konzern SG_ 2600468678 NM_Ladegeraet_2_CAB 2000;
BA_REL_ "GenSigTimeoutTime" BU_SG_REL_ LE1 SG_ 2600468678 NM_Ladegeraet_2_CAB 2000;
BA_REL_ "GenSigTimeoutTime" BU_SG_REL_ LE2 SG_ 2600468678 NM_Ladegeraet_2_CAB 2000;
BA_REL_ "GenSigTimeoutTime" BU_SG_REL_ LE2_3_MLBevo_LB SG_ 2600468678 NM_Ladegeraet_2_CAB 2000;
BA_REL_ "GenSigTimeoutTime" BU_SG_REL_ LE_MLBevo SG_ 2600468678 NM_Ladegeraet_2_CAB 2000;
BA_REL_ "GenSigTimeoutTime" BU_SG_REL_ Sub_Gateway SG_ 2600468678 NM_Ladegeraet_2_CAB 2000;
BA_REL_ "GenSigTimeoutTime" BU_SG_REL_ TME SG_ 2600468678 NM_Ladegeraet_2_CAB 2000;
BA_REL_ "GenSigTimeoutTime" BU_SG_REL_ AWC SG_ 2600468481 NM_Sekundaer_01_SNI 2000;
BA_REL_ "GenSigTimeoutTime" BU_SG_REL_ BMC_MLBevo SG_ 2600468481 NM_Sekundaer_01_SNI 2000;
BA_REL_ "GenSigTimeoutTime" BU_SG_REL_ BMS_MV SG_ 2600468481 NM_Sekundaer_01_SNI 2000;
BA_REL_ "GenSigTimeoutTime" BU_SG_REL_ BMS_NV SG_ 2600468481 NM_Sekundaer_01_SNI 2000;
BA_REL_ "GenSigTimeoutTime" BU_SG_REL_ DCDC_800V_PAG SG_ 2600468481 NM_Sekundaer_01_SNI 2000;
BA_REL_ "GenSigTimeoutTime" BU_SG_REL_ DCDC_HV SG_ 2600468481 NM_Sekundaer_01_SNI 2000;
BA_REL_ "GenSigTimeoutTime" BU_SG_REL_ DCDC_HV_02 SG_ 2600468481 NM_Sekundaer_01_SNI 2000;
BA_REL_ "GenSigTimeoutTime" BU_SG_REL_ DCDC_IHEV SG_ 2600468481 NM_Sekundaer_01_SNI 2000;
BA_REL_ "GenSigTimeoutTime" BU_SG_REL_ Gateway SG_ 2600468481 NM_Sekundaer_01_SNI 2000;
BA_REL_ "GenSigTimeoutTime" BU_SG_REL_ Gateway_PAG SG_ 2600468481 NM_Sekundaer_01_SNI 2000;
BA_REL_ "GenSigTimeoutTime" BU_SG_REL_ Ladegeraet_2 SG_ 2600468481 NM_Sekundaer_01_SNI 2000;
BA_REL_ "GenSigTimeoutTime" BU_SG_REL_ Ladegeraet_Konzern SG_ 2600468481 NM_Sekundaer_01_SNI 2000;
BA_REL_ "GenSigTimeoutTime" BU_SG_REL_ LE1 SG_ 2600468481 NM_Sekundaer_01_SNI 2000;
BA_REL_ "GenSigTimeoutTime" BU_SG_REL_ LE_MLBevo SG_ 2600468481 NM_Sekundaer_01_SNI 2000;
BA_REL_ "GenSigTimeoutTime" BU_SG_REL_ Sub_Gateway SG_ 2600468481 NM_Sekundaer_01_SNI 2000;
BA_REL_ "GenSigTimeoutTime" BU_SG_REL_ TME SG_ 2600468481 NM_Sekundaer_01_SNI 2000;
BA_REL_ "GenSigTimeoutTime" BU_SG_REL_ Gateway SG_ 2600468481 NM_Sekundaer_01_CBV_AWB 2000;
BA_REL_ "GenSigTimeoutTime" BU_SG_REL_ AWC SG_ 2600468481 NM_Sekundaer_01_CBV_CRI 2000;
BA_REL_ "GenSigTimeoutTime" BU_SG_REL_ BMC_MLBevo SG_ 2600468481 NM_Sekundaer_01_CBV_CRI 2000;
BA_REL_ "GenSigTimeoutTime" BU_SG_REL_ BMS_MV SG_ 2600468481 NM_Sekundaer_01_CBV_CRI 2000;
BA_REL_ "GenSigTimeoutTime" BU_SG_REL_ BMS_NV SG_ 2600468481 NM_Sekundaer_01_CBV_CRI 2000;
BA_REL_ "GenSigTimeoutTime" BU_SG_REL_ DCDC_800V_PAG SG_ 2600468481 NM_Sekundaer_01_CBV_CRI 2000;
BA_REL_ "GenSigTimeoutTime" BU_SG_REL_ DCDC_HV SG_ 2600468481 NM_Sekundaer_01_CBV_CRI 2000;
BA_REL_ "GenSigTimeoutTime" BU_SG_REL_ DCDC_HV_02 SG_ 2600468481 NM_Sekundaer_01_CBV_CRI 2000;
BA_REL_ "GenSigTimeoutTime" BU_SG_REL_ DCDC_IHEV SG_ 2600468481 NM_Sekundaer_01_CBV_CRI 2000;
BA_REL_ "GenSigTimeoutTime" BU_SG_REL_ Gateway SG_ 2600468481 NM_Sekundaer_01_CBV_CRI 2000;
BA_REL_ "GenSigTimeoutTime" BU_SG_REL_ Gateway_PAG SG_ 2600468481 NM_Sekundaer_01_CBV_CRI 2000;
BA_REL_ "GenSigTimeoutTime" BU_SG_REL_ Ladegeraet_2 SG_ 2600468481 NM_Sekundaer_01_CBV_CRI 2000;
BA_REL_ "GenSigTimeoutTime" BU_SG_REL_ Ladegeraet_Konzern SG_ 2600468481 NM_Sekundaer_01_CBV_CRI 2000;
BA_REL_ "GenSigTimeoutTime" BU_SG_REL_ LE1 SG_ 2600468481 NM_Sekundaer_01_CBV_CRI 2000;
BA_REL_ "GenSigTimeoutTime" BU_SG_REL_ LE_MLBevo SG_ 2600468481 NM_Sekundaer_01_CBV_CRI 2000;
BA_REL_ "GenSigTimeoutTime" BU_SG_REL_ Sub_Gateway SG_ 2600468481 NM_Sekundaer_01_CBV_CRI 2000;
BA_REL_ "GenSigTimeoutTime" BU_SG_REL_ TME SG_ 2600468481 NM_Sekundaer_01_CBV_CRI 2000;
BA_REL_ "GenSigTimeoutTime" BU_SG_REL_ Gateway SG_ 2600468481 NM_Sekundaer_01_Car_Wakeup 2000;
BA_REL_ "GenSigTimeoutTime" BU_SG_REL_ AWC SG_ 2600468481 NM_Sekundaer_01_CAB 2000;
BA_REL_ "GenSigTimeoutTime" BU_SG_REL_ BMC_MLBevo SG_ 2600468481 NM_Sekundaer_01_CAB 2000;
BA_REL_ "GenSigTimeoutTime" BU_SG_REL_ BMS_MV SG_ 2600468481 NM_Sekundaer_01_CAB 2000;
BA_REL_ "GenSigTimeoutTime" BU_SG_REL_ BMS_NV SG_ 2600468481 NM_Sekundaer_01_CAB 2000;
BA_REL_ "GenSigTimeoutTime" BU_SG_REL_ DCDC_800V_PAG SG_ 2600468481 NM_Sekundaer_01_CAB 2000;
BA_REL_ "GenSigTimeoutTime" BU_SG_REL_ DCDC_HV SG_ 2600468481 NM_Sekundaer_01_CAB 2000;
BA_REL_ "GenSigTimeoutTime" BU_SG_REL_ DCDC_HV_02 SG_ 2600468481 NM_Sekundaer_01_CAB 2000;
BA_REL_ "GenSigTimeoutTime" BU_SG_REL_ DCDC_IHEV SG_ 2600468481 NM_Sekundaer_01_CAB 2000;
BA_REL_ "GenSigTimeoutTime" BU_SG_REL_ Gateway SG_ 2600468481 NM_Sekundaer_01_CAB 2000;
BA_REL_ "GenSigTimeoutTime" BU_SG_REL_ Gateway_PAG SG_ 2600468481 NM_Sekundaer_01_CAB 2000;
BA_REL_ "GenSigTimeoutTime" BU_SG_REL_ Ladegeraet_2 SG_ 2600468481 NM_Sekundaer_01_CAB 2000;
BA_REL_ "GenSigTimeoutTime" BU_SG_REL_ Ladegeraet_Konzern SG_ 2600468481 NM_Sekundaer_01_CAB 2000;
BA_REL_ "GenSigTimeoutTime" BU_SG_REL_ LE1 SG_ 2600468481 NM_Sekundaer_01_CAB 2000;
BA_REL_ "GenSigTimeoutTime" BU_SG_REL_ LE_MLBevo SG_ 2600468481 NM_Sekundaer_01_CAB 2000;
BA_REL_ "GenSigTimeoutTime" BU_SG_REL_ Sub_Gateway SG_ 2600468481 NM_Sekundaer_01_CAB 2000;
BA_REL_ "GenSigTimeoutTime" BU_SG_REL_ TME SG_ 2600468481 NM_Sekundaer_01_CAB 2000;
BA_REL_ "GenSigTimeoutTime" BU_SG_REL_ AWC SG_ 2600468483 NM_Sekundaer_03_SNI 2000;
BA_REL_ "GenSigTimeoutTime" BU_SG_REL_ BMC_MLBevo SG_ 2600468483 NM_Sekundaer_03_SNI 2000;
BA_REL_ "GenSigTimeoutTime" BU_SG_REL_ BMS_MV SG_ 2600468483 NM_Sekundaer_03_SNI 2000;
BA_REL_ "GenSigTimeoutTime" BU_SG_REL_ BMS_NV SG_ 2600468483 NM_Sekundaer_03_SNI 2000;
BA_REL_ "GenSigTimeoutTime" BU_SG_REL_ DCDC_800V_PAG SG_ 2600468483 NM_Sekundaer_03_SNI 2000;
BA_REL_ "GenSigTimeoutTime" BU_SG_REL_ DCDC_HV SG_ 2600468483 NM_Sekundaer_03_SNI 2000;
BA_REL_ "GenSigTimeoutTime" BU_SG_REL_ DCDC_HV_02 SG_ 2600468483 NM_Sekundaer_03_SNI 2000;
BA_REL_ "GenSigTimeoutTime" BU_SG_REL_ DCDC_IHEV SG_ 2600468483 NM_Sekundaer_03_SNI 2000;
BA_REL_ "GenSigTimeoutTime" BU_SG_REL_ Gateway SG_ 2600468483 NM_Sekundaer_03_SNI 2000;
BA_REL_ "GenSigTimeoutTime" BU_SG_REL_ Gateway_PAG SG_ 2600468483 NM_Sekundaer_03_SNI 2000;
BA_REL_ "GenSigTimeoutTime" BU_SG_REL_ Ladegeraet_2 SG_ 2600468483 NM_Sekundaer_03_SNI 2000;
BA_REL_ "GenSigTimeoutTime" BU_SG_REL_ Ladegeraet_Konzern SG_ 2600468483 NM_Sekundaer_03_SNI 2000;
BA_REL_ "GenSigTimeoutTime" BU_SG_REL_ LE2 SG_ 2600468483 NM_Sekundaer_03_SNI 2000;
BA_REL_ "GenSigTimeoutTime" BU_SG_REL_ LE2_3_MLBevo_LB SG_ 2600468483 NM_Sekundaer_03_SNI 2000;
BA_REL_ "GenSigTimeoutTime" BU_SG_REL_ Sub_Gateway SG_ 2600468483 NM_Sekundaer_03_SNI 2000;
BA_REL_ "GenSigTimeoutTime" BU_SG_REL_ TME SG_ 2600468483 NM_Sekundaer_03_SNI 2000;
BA_REL_ "GenSigTimeoutTime" BU_SG_REL_ Gateway SG_ 2600468483 NM_Sekundaer_03_CBV_AWB 2000;
BA_REL_ "GenSigTimeoutTime" BU_SG_REL_ Gateway_PAG SG_ 2600468483 NM_Sekundaer_03_CBV_AWB 2000;
BA_REL_ "GenSigTimeoutTime" BU_SG_REL_ AWC SG_ 2600468483 NM_Sekundaer_03_CBV_CRI 2000;
BA_REL_ "GenSigTimeoutTime" BU_SG_REL_ BMC_MLBevo SG_ 2600468483 NM_Sekundaer_03_CBV_CRI 2000;
BA_REL_ "GenSigTimeoutTime" BU_SG_REL_ BMS_MV SG_ 2600468483 NM_Sekundaer_03_CBV_CRI 2000;
BA_REL_ "GenSigTimeoutTime" BU_SG_REL_ BMS_NV SG_ 2600468483 NM_Sekundaer_03_CBV_CRI 2000;
BA_REL_ "GenSigTimeoutTime" BU_SG_REL_ DCDC_800V_PAG SG_ 2600468483 NM_Sekundaer_03_CBV_CRI 2000;
BA_REL_ "GenSigTimeoutTime" BU_SG_REL_ DCDC_HV SG_ 2600468483 NM_Sekundaer_03_CBV_CRI 2000;
BA_REL_ "GenSigTimeoutTime" BU_SG_REL_ DCDC_HV_02 SG_ 2600468483 NM_Sekundaer_03_CBV_CRI 2000;
BA_REL_ "GenSigTimeoutTime" BU_SG_REL_ DCDC_IHEV SG_ 2600468483 NM_Sekundaer_03_CBV_CRI 2000;
BA_REL_ "GenSigTimeoutTime" BU_SG_REL_ Gateway SG_ 2600468483 NM_Sekundaer_03_CBV_CRI 2000;
BA_REL_ "GenSigTimeoutTime" BU_SG_REL_ Gateway_PAG SG_ 2600468483 NM_Sekundaer_03_CBV_CRI 2000;
BA_REL_ "GenSigTimeoutTime" BU_SG_REL_ Ladegeraet_2 SG_ 2600468483 NM_Sekundaer_03_CBV_CRI 2000;
BA_REL_ "GenSigTimeoutTime" BU_SG_REL_ Ladegeraet_Konzern SG_ 2600468483 NM_Sekundaer_03_CBV_CRI 2000;
BA_REL_ "GenSigTimeoutTime" BU_SG_REL_ LE2 SG_ 2600468483 NM_Sekundaer_03_CBV_CRI 2000;
BA_REL_ "GenSigTimeoutTime" BU_SG_REL_ LE2_3_MLBevo_LB SG_ 2600468483 NM_Sekundaer_03_CBV_CRI 2000;
BA_REL_ "GenSigTimeoutTime" BU_SG_REL_ Sub_Gateway SG_ 2600468483 NM_Sekundaer_03_CBV_CRI 2000;
BA_REL_ "GenSigTimeoutTime" BU_SG_REL_ TME SG_ 2600468483 NM_Sekundaer_03_CBV_CRI 2000;
BA_REL_ "GenSigTimeoutTime" BU_SG_REL_ AWC SG_ 2600468483 NM_Sekundaer_03_CAB 2000;
BA_REL_ "GenSigTimeoutTime" BU_SG_REL_ BMC_MLBevo SG_ 2600468483 NM_Sekundaer_03_CAB 2000;
BA_REL_ "GenSigTimeoutTime" BU_SG_REL_ BMS_MV SG_ 2600468483 NM_Sekundaer_03_CAB 2000;
BA_REL_ "GenSigTimeoutTime" BU_SG_REL_ BMS_NV SG_ 2600468483 NM_Sekundaer_03_CAB 2000;
BA_REL_ "GenSigTimeoutTime" BU_SG_REL_ DCDC_800V_PAG SG_ 2600468483 NM_Sekundaer_03_CAB 2000;
BA_REL_ "GenSigTimeoutTime" BU_SG_REL_ DCDC_HV SG_ 2600468483 NM_Sekundaer_03_CAB 2000;
BA_REL_ "GenSigTimeoutTime" BU_SG_REL_ DCDC_HV_02 SG_ 2600468483 NM_Sekundaer_03_CAB 2000;
BA_REL_ "GenSigTimeoutTime" BU_SG_REL_ DCDC_IHEV SG_ 2600468483 NM_Sekundaer_03_CAB 2000;
BA_REL_ "GenSigTimeoutTime" BU_SG_REL_ Gateway SG_ 2600468483 NM_Sekundaer_03_CAB 2000;
BA_REL_ "GenSigTimeoutTime" BU_SG_REL_ Gateway_PAG SG_ 2600468483 NM_Sekundaer_03_CAB 2000;
BA_REL_ "GenSigTimeoutTime" BU_SG_REL_ Ladegeraet_2 SG_ 2600468483 NM_Sekundaer_03_CAB 2000;
BA_REL_ "GenSigTimeoutTime" BU_SG_REL_ Ladegeraet_Konzern SG_ 2600468483 NM_Sekundaer_03_CAB 2000;
BA_REL_ "GenSigTimeoutTime" BU_SG_REL_ LE2 SG_ 2600468483 NM_Sekundaer_03_CAB 2000;
BA_REL_ "GenSigTimeoutTime" BU_SG_REL_ LE2_3_MLBevo_LB SG_ 2600468483 NM_Sekundaer_03_CAB 2000;
BA_REL_ "GenSigTimeoutTime" BU_SG_REL_ Sub_Gateway SG_ 2600468483 NM_Sekundaer_03_CAB 2000;
BA_REL_ "GenSigTimeoutTime" BU_SG_REL_ TME SG_ 2600468483 NM_Sekundaer_03_CAB 2000;
BA_REL_ "GenSigTimeoutTime" BU_SG_REL_ AWC SG_ 2600468553 NM_Sub_Gateway_SNI 2000;
BA_REL_ "GenSigTimeoutTime" BU_SG_REL_ BMC_MLBevo SG_ 2600468553 NM_Sub_Gateway_SNI 2000;
BA_REL_ "GenSigTimeoutTime" BU_SG_REL_ BMS_MV SG_ 2600468553 NM_Sub_Gateway_SNI 2000;
BA_REL_ "GenSigTimeoutTime" BU_SG_REL_ BMS_NV SG_ 2600468553 NM_Sub_Gateway_SNI 2000;
BA_REL_ "GenSigTimeoutTime" BU_SG_REL_ DCDC_800V_PAG SG_ 2600468553 NM_Sub_Gateway_SNI 2000;
BA_REL_ "GenSigTimeoutTime" BU_SG_REL_ DCDC_HV SG_ 2600468553 NM_Sub_Gateway_SNI 2000;
BA_REL_ "GenSigTimeoutTime" BU_SG_REL_ DCDC_HV_02 SG_ 2600468553 NM_Sub_Gateway_SNI 2000;
BA_REL_ "GenSigTimeoutTime" BU_SG_REL_ DCDC_IHEV SG_ 2600468553 NM_Sub_Gateway_SNI 2000;
BA_REL_ "GenSigTimeoutTime" BU_SG_REL_ FCU_MLBevo_FCEV SG_ 2600468553 NM_Sub_Gateway_SNI 2000;
BA_REL_ "GenSigTimeoutTime" BU_SG_REL_ Gateway SG_ 2600468553 NM_Sub_Gateway_SNI 2000;
BA_REL_ "GenSigTimeoutTime" BU_SG_REL_ Ladegeraet_2 SG_ 2600468553 NM_Sub_Gateway_SNI 2000;
BA_REL_ "GenSigTimeoutTime" BU_SG_REL_ Ladegeraet_Konzern SG_ 2600468553 NM_Sub_Gateway_SNI 2000;
BA_REL_ "GenSigTimeoutTime" BU_SG_REL_ LE1 SG_ 2600468553 NM_Sub_Gateway_SNI 2000;
BA_REL_ "GenSigTimeoutTime" BU_SG_REL_ LE2 SG_ 2600468553 NM_Sub_Gateway_SNI 2000;
BA_REL_ "GenSigTimeoutTime" BU_SG_REL_ LE2_3_MLBevo_LB SG_ 2600468553 NM_Sub_Gateway_SNI 2000;
BA_REL_ "GenSigTimeoutTime" BU_SG_REL_ LE_MLBevo SG_ 2600468553 NM_Sub_Gateway_SNI 2000;
BA_REL_ "GenSigTimeoutTime" BU_SG_REL_ TME SG_ 2600468553 NM_Sub_Gateway_SNI 2000;
BA_REL_ "GenSigTimeoutTime" BU_SG_REL_ Gateway SG_ 2600468553 NM_Sub_Gateway_CBV_AWB 2000;
BA_REL_ "GenSigTimeoutTime" BU_SG_REL_ AWC SG_ 2600468553 NM_Sub_Gateway_CBV_CRI 2000;
BA_REL_ "GenSigTimeoutTime" BU_SG_REL_ BMC_MLBevo SG_ 2600468553 NM_Sub_Gateway_CBV_CRI 2000;
BA_REL_ "GenSigTimeoutTime" BU_SG_REL_ BMS_MV SG_ 2600468553 NM_Sub_Gateway_CBV_CRI 2000;
BA_REL_ "GenSigTimeoutTime" BU_SG_REL_ BMS_NV SG_ 2600468553 NM_Sub_Gateway_CBV_CRI 2000;
BA_REL_ "GenSigTimeoutTime" BU_SG_REL_ DCDC_800V_PAG SG_ 2600468553 NM_Sub_Gateway_CBV_CRI 2000;
BA_REL_ "GenSigTimeoutTime" BU_SG_REL_ DCDC_HV SG_ 2600468553 NM_Sub_Gateway_CBV_CRI 2000;
BA_REL_ "GenSigTimeoutTime" BU_SG_REL_ DCDC_HV_02 SG_ 2600468553 NM_Sub_Gateway_CBV_CRI 2000;
BA_REL_ "GenSigTimeoutTime" BU_SG_REL_ DCDC_IHEV SG_ 2600468553 NM_Sub_Gateway_CBV_CRI 2000;
BA_REL_ "GenSigTimeoutTime" BU_SG_REL_ FCU_MLBevo_FCEV SG_ 2600468553 NM_Sub_Gateway_CBV_CRI 2000;
BA_REL_ "GenSigTimeoutTime" BU_SG_REL_ Gateway SG_ 2600468553 NM_Sub_Gateway_CBV_CRI 2000;
BA_REL_ "GenSigTimeoutTime" BU_SG_REL_ Ladegeraet_2 SG_ 2600468553 NM_Sub_Gateway_CBV_CRI 2000;
BA_REL_ "GenSigTimeoutTime" BU_SG_REL_ Ladegeraet_Konzern SG_ 2600468553 NM_Sub_Gateway_CBV_CRI 2000;
BA_REL_ "GenSigTimeoutTime" BU_SG_REL_ LE1 SG_ 2600468553 NM_Sub_Gateway_CBV_CRI 2000;
BA_REL_ "GenSigTimeoutTime" BU_SG_REL_ LE2 SG_ 2600468553 NM_Sub_Gateway_CBV_CRI 2000;
BA_REL_ "GenSigTimeoutTime" BU_SG_REL_ LE2_3_MLBevo_LB SG_ 2600468553 NM_Sub_Gateway_CBV_CRI 2000;
BA_REL_ "GenSigTimeoutTime" BU_SG_REL_ LE_MLBevo SG_ 2600468553 NM_Sub_Gateway_CBV_CRI 2000;
BA_REL_ "GenSigTimeoutTime" BU_SG_REL_ TME SG_ 2600468553 NM_Sub_Gateway_CBV_CRI 2000;
BA_REL_ "GenSigTimeoutTime" BU_SG_REL_ Gateway SG_ 2600468553 NM_Sub_Gateway_Car_Wakeup 2000;
BA_REL_ "GenSigTimeoutTime" BU_SG_REL_ AWC SG_ 2600468553 NM_Sub_Gateway_CAB 2000;
BA_REL_ "GenSigTimeoutTime" BU_SG_REL_ BMC_MLBevo SG_ 2600468553 NM_Sub_Gateway_CAB 2000;
BA_REL_ "GenSigTimeoutTime" BU_SG_REL_ BMS_MV SG_ 2600468553 NM_Sub_Gateway_CAB 2000;
BA_REL_ "GenSigTimeoutTime" BU_SG_REL_ BMS_NV SG_ 2600468553 NM_Sub_Gateway_CAB 2000;
BA_REL_ "GenSigTimeoutTime" BU_SG_REL_ DCDC_800V_PAG SG_ 2600468553 NM_Sub_Gateway_CAB 2000;
BA_REL_ "GenSigTimeoutTime" BU_SG_REL_ DCDC_HV SG_ 2600468553 NM_Sub_Gateway_CAB 2000;
BA_REL_ "GenSigTimeoutTime" BU_SG_REL_ DCDC_HV_02 SG_ 2600468553 NM_Sub_Gateway_CAB 2000;
BA_REL_ "GenSigTimeoutTime" BU_SG_REL_ DCDC_IHEV SG_ 2600468553 NM_Sub_Gateway_CAB 2000;
BA_REL_ "GenSigTimeoutTime" BU_SG_REL_ FCU_MLBevo_FCEV SG_ 2600468553 NM_Sub_Gateway_CAB 2000;
BA_REL_ "GenSigTimeoutTime" BU_SG_REL_ Gateway SG_ 2600468553 NM_Sub_Gateway_CAB 2000;
BA_REL_ "GenSigTimeoutTime" BU_SG_REL_ Ladegeraet_2 SG_ 2600468553 NM_Sub_Gateway_CAB 2000;
BA_REL_ "GenSigTimeoutTime" BU_SG_REL_ Ladegeraet_Konzern SG_ 2600468553 NM_Sub_Gateway_CAB 2000;
BA_REL_ "GenSigTimeoutTime" BU_SG_REL_ LE1 SG_ 2600468553 NM_Sub_Gateway_CAB 2000;
BA_REL_ "GenSigTimeoutTime" BU_SG_REL_ LE2 SG_ 2600468553 NM_Sub_Gateway_CAB 2000;
BA_REL_ "GenSigTimeoutTime" BU_SG_REL_ LE2_3_MLBevo_LB SG_ 2600468553 NM_Sub_Gateway_CAB 2000;
BA_REL_ "GenSigTimeoutTime" BU_SG_REL_ LE_MLBevo SG_ 2600468553 NM_Sub_Gateway_CAB 2000;
BA_REL_ "GenSigTimeoutTime" BU_SG_REL_ TME SG_ 2600468553 NM_Sub_Gateway_CAB 2000;
VAL_ 339 MO_HVEM_Eskalation 0 "keine_Eskalation_HVEM" 1 "Eskalation_HVEM" ;
VAL_ 339 MO_ErwGrenzen_Anf 0 "normal" 1 "erweitert" ;
VAL_ 339 MO_Fehler_Notentladung_Anf 0 "Init" ;
VAL_ 339 MO_HVEM_MaxLeistung 510 "Init" ;
VAL_ 339 MO_HVK_EmIstzustand 0 "HvOff" 1 "HvStbyReq" 2 "HvStbyOk" 3 "HvBattOnReq" 4 "HvBattOnOk" 10 "HvOnIdle" 18 "HvOnDrvReq" 19 "HvOnDrvOk" 20 "HvOnDrvRdy" 28 "HvStepUpReq" 29 "HvStepUpOk" 30 "HvStepUp" 38 "HvStepDownReq" 39 "HvStepDownOk" 40 "HvStepDown" 46 "HvAcChPreReq" 47 "HvAcChPreOk" 48 "HvAcChReq" 49 "HvAcChOk" 50 "HvAcCh" 56 "HvDcChPreReq" 57 "HvDcChPreOk" 58 "HvDcChReq" 59 "HvDcChOk" 60 "HvDcCh" 67 "HvChOffReq" 68 "HvChOffOk" 69 "HvOnIdleReq" 70 "HvOnIdleOk" 96 "HvCpntOffReq" 97 "HvCpntOffOk" 98 "HvBattOffReq" 99 "HvBattOffOk" 109 "HvDcDcFailOffReq" 110 "HvDcDcFail" 119 "HvElmOffReq" 120 "HvElmOff" 126 "HvFailCpntOffReq" 127 "HvFailCpntOffOk" 128 "HvFailBattOffReq" 129 "HvFailBattOffOk" 130 "HvFailBattOff" 138 "HvFailUCtlReq" 139 "HvFailUCtlOk" 140 "HvFailUCtl" 150 "HvEmgcyOff" 255 "Init" ;
VAL_ 339 MO_HVK_AntriebFehlerstatus 0 "Komponente_IO" 6 "Keine_Komponentenfunktion" 7 "Init" ;
VAL_ 339 MO_MVK_Bordnetz_Anf 0 "keine_Anforderung" 1 "Bordnetzaktivitaet_gefordert" ;
VAL_ 339 MO_HVK_AntriebZustand 0 "Antrieb_AUS" 1 "Antrieb_Startphase" 2 "E_Fahren" 3 "Hybrid_Fahren" 7 "Init" ;
VAL_ 339 MO_HVK_EmFehlerstatus 0 "Komponente_IO" 1 "Eingeschr_KompFkt_Teilbetrieb" 3 "Eingeschr_KompFkt_Interlock" 6 "Keine_Komponentenfunktion" 7 "Init" ;
VAL_ 339 MO_MVK_AntriebFehlerstatus 0 "Komponente_IO" 6 "Keine_Komponentenfunktion" 7 "Init" ;
VAL_ 339 MO_MVK_AntriebZustand 0 "Antrieb_AUS" 1 "Antrieb_Startphase" 2 "FreilaufMotorAus" 7 "Init" ;
VAL_ 339 MO_MVK_EmFehlerstatus 0 "Komponente_IO" 1 "Eingeschr_KompFkt_Teilbetrieb" 6 "Keine_Komponentenfunktion" 7 "Init" ;
VAL_ 339 MO_MVK_EmIstzustand 0 "MvOff" 1 "MvStbyReq" 2 "MvStbyOk" 3 "MvBattOnReq" 4 "MvBattOnOk" 10 "MvOnIdle" 18 "MvOnDrvReq" 19 "MvOnDrvOk" 20 "MvOnDrv" 28 "MvStepUpReq" 29 "MvStepUpOk" 30 "MvStepUp" 38 "MvStepDownReq" 39 "MvStepDownOk" 40 "MvStepDown" 96 "MvCpntOffReq" 97 "MvCpntOffOk" 98 "MvBattOffReq" 99 "MvBattOffOk" 109 "MvDcDcFailOffReq" 110 "MvDcDcFail" 119 "MvElmFailOffReq" 120 "MvElmFail" 126 "MvFailCpntOffReq" 127 "MvFailCpntOffOk" 128 "MvFailBattOffReq" 129 "MvFailBattOffOk" 130 "MvFailBattOff" 138 "MvFailUCtlReq" 139 "MvFailUCtlOk" 140 "MvFailUCtl" 150 "MvEmgcyOff" 255 "Init" ;
VAL_ 1434 TME_Dauer_Vorkond_innen 61 "Berechnungsphase" 62 "Init" 63 "Fehler" ;
VAL_ 1434 TME_Eskalation 0 "keine_Anfrage__Reduzierung_mgl" 1 "Leistungsanf__keine_Leistungsred" 2 "Init" 3 "Fehler" ;
VAL_ 1434 TME_Leistungsanf_ThermoKuehlen 254 "Init" 255 "Fehler" ;
VAL_ 1434 TME_Leistungsanf_ThermoHeizen 254 "Init" 255 "Fehler" ;
VAL_ 1434 TME_Leistungsanf_Komfort 254 "Init" 255 "Fehler" ;
VAL_ 1434 KL_IstLeistung 254 "Init" 255 "Fehler" ;
VAL_ 689 TME_PlanAntw_Zaehler 14 "Init" 15 "Fehler" ;
VAL_ 689 TME_Verbrauch_gesamt_Ueberlauf 0 "kein_Ueberlauf" 1 "Ueberlauf" ;
VAL_ 689 TME_Energie_Thermo 16382 "Init" 16383 "Fehler" ;
VAL_ 689 TME_Energie_Komfort 16382 "Init" 16383 "Fehler" ;
VAL_ 931 MVEM_MO_RSG_Startleistung 254 "Init" 255 "Fehler" ;
VAL_ 931 MVEM_Umin_Funktionsgruppe_C_02 254 "Init" 255 "Fehler" ;
VAL_ 931 MVEM_IstStrom_MVVerbraucher 1022 "Init" 1023 "Fehler" ;
VAL_ 931 MVEM_DC_SollSpannung_MV 254 "Init" 255 "Fehler" ;
VAL_ 931 MVEM_DC_SollLeistung_MV 254 "Init" 255 "Fehler" ;
VAL_ 931 MVEM_EMG_MaxGenStrom 254 "Init" 255 "Fehler" ;
VAL_ 931 MVEM_EMG_MaxGenSpannung 254 "Init" 255 "Fehler" ;
VAL_ 2589283456 MVEM_MO_Sollspannung_Notbetrieb 254 "Init" 255 "Fehler" ;
VAL_ 2589283456 MVEM_Umax_Rueckspeisung 254 "Init" 255 "Fehler" ;
VAL_ 2589283456 MVEM_Umin_Funktionsgruppe_C 254 "Init" 255 "Fehler" ;
VAL_ 2589283456 MVEM_Umin_Funktionsgruppe_B 254 "Init" 255 "Fehler" ;
VAL_ 2589283456 MVEM_Umin_Funktionsgruppe_A 254 "Init" 255 "Fehler" ;
VAL_ 1284 MVK_DCDC_Sollmodus_02 0 "Standby" 1 "MV_On" 2 "Tiefsetzen" 3 "Hochsetzen" 4 "Startunterstuetzung_48V" 6 "Startunterstuetzung_12V" 7 "Init" 9 "MV_On_Notbetrieb" 10 "Tiefsetzen_Notbetrieb" 11 "Pruefpuls_12V" ;
VAL_ 1284 MV_Bordnetz_aktiv 0 "inaktiv" 1 "aktiv" ;
VAL_ 1284 MVK_BOOST_Sollmodus 0 "Keine_Freigabe" 1 "Freigabe" 7 "Init" ;
VAL_ 1284 MVK_eABC_Sollmodus 0 "Keine_Freigabe" 1 "Freigabe" 7 "Init" ;
VAL_ 1284 MVK_eAWS_Sollmodus 0 "Keine_Freigabe" 1 "Freigabe" 7 "Init" ;
VAL_ 1284 MV_Bordnetz_Fehler 0 "kein_Fehler" 1 "Fehler" ;
VAL_ 1284 MVK_MVPTC_Sollmodus 0 "Keine_Freigabe" 1 "Freigabe" 7 "Init" ;
VAL_ 1284 MVK_Istmodus_Anf 0 "nicht_angefordert" 1 "angefordert" ;
VAL_ 1284 MVK_MO_EmSollzustand 0 "MvOff" 1 "MvStbyReq" 2 "MvStbyWait" 3 "MvBattOnReq" 4 "MvBattOnWait" 10 "MvOnIdle" 18 "MvOnDrvReq" 19 "MvOnDrvWait" 20 "MvOnDrv" 28 "MvStepUpReq" 29 "MvStepUpWait" 30 "MvStepUp" 38 "MvStepDownReq" 39 "MvStepDownWait" 40 "MvStepDown" 96 "MvCpntOffReq" 97 "MvCpntOffWait" 98 "MvBattOffReq" 99 "MvBattOffWait" 109 "MvDcDcFailOffReq" 110 "MvDcDcFail" 119 "MvElmFailOffReq" 120 "MvElmFail" 126 "MvFailCpntOffReq" 127 "MvFailCpntOffWait" 128 "MvFailBattOffReq" 129 "MvFailBattOffWait" 130 "MvFailBattOff" 138 "MvFailUCtlReq" 139 "MvFailUCtlWait" 140 "MvFailUCtl" 150 "MvEmgcyOff" 255 "Init" ;
VAL_ 1284 MVK_BMS_Sollmodus 0 "MV_Off" 1 "MV_On" 7 "Init" ;
VAL_ 1284 MVK_DCDC_Sollmodus 0 "Standby" 1 "MV_On" 2 "Tiefsetzen" 3 "Hochsetzen" 4 "Startunterstuetzung_48V" 6 "Startunterstuetzung_12V" 7 "Init" ;
VAL_ 1284 MVK_MV_Netz_Warnungen 0 "Keine_Warnung" 1 "Warntext_MV_Netz_Anf" 2 "Fehlertext_MV_Netz_Anf" 3 "Warnung_Kein_Wiederstart_moeglic" ;
VAL_ 1157 ND_SatInUse 30 "Init" 31 "Fehler" ;
VAL_ 1157 POS_Guete_horizontal_verfuegbar 0 "nicht_verfuegbar" 1 "verfuegbar" ;
VAL_ 1157 ND_SatInView 30 "Init" 31 "Fehler" ;
VAL_ 1157 POS_Guete_horizontal 124 "von_248m_bis_400m" 125 "mehr_als_400m" 126 "Init" 127 "Fehler" ;
VAL_ 1157 NP_Altitude 4094 "Init" 4095 "Fehler" ;
VAL_ 1158 NP_LatDegree 134217726 "Init" 134217727 "Fehler" ;
VAL_ 1158 NP_LongDegree 268435454 "Init" 268435455 "Fehler" ;
VAL_ 1158 NP_LatDirection 0 "Nord" 1 "Sued" ;
VAL_ 1158 NP_LongDirection 0 "Ost" 1 "West" ;
VAL_ 1158 NP_Sat 30 "Init" 31 "Fehler" ;
VAL_ 1158 NP_Fix 0 "Init" 1 "No_Fix" 2 "2D_Fix" 3 "3D_Fix" ;
VAL_ 2589283496 POS_MUX 0 "MUX_0" 1 "MUX_1" 2 "reserved" 3 "Init" ;
VAL_ 2589283496 POS_ODD_EVEN 0 "ODD" 1 "EVEN" ;
VAL_ 2589283496 POS_PosStati 0 "Init" 1 "NoNavAvailable" 2 "NoMapAvailable" 3 "NavBooting" 4 "NavError" 5 "NavCalibrating" 6 "NavNoGpsResyncSince1h" 7 "NavOffroadParkgarageRampOffset2" 8 "DeadReckoningWithoutGps" 9 "DeadReckoningWithGps" 10 "MapMatchedLowConfidence" 11 "MapMatchedLimitedConfidence" 12 "OffroadHighConfidence" 13 "MapMatchedHighConfidence" 14 "PosInSyncWithGpsAndMAP" ;
VAL_ 2589283496 POS_LatDirection 0 "North" 1 "South" ;
VAL_ 2589283496 POS_LatDegree 134217726 "Init" 134217727 "Fehler" ;
VAL_ 2589283496 POS_Heading_Trust 0 "Init" 1 "TrustLevel01" 2 "TrustLevel02" 3 "Fehler" ;
VAL_ 2589283496 POS_LongDirection 0 "East" 1 "West" ;
VAL_ 2589283496 POS_LongDegree 268435454 "Init" 268435455 "Fehler" ;
VAL_ 2600468623 NM_AWC_SNI 143 "AWC" ;
VAL_ 2600468623 NM_AWC_CBV_AWB 0 "Passiver_WakeUp" 1 "Aktiver_WakeUp" ;
VAL_ 2600468623 NM_AWC_CBV_CRI 0 "Standard_Layout" 1 "TNB_Layout" ;
VAL_ 2600468623 NM_AWC_NM_State 1 "NM_RM_aus_BSM" 2 "NM_RM_aus_PBSM" 4 "NM_NO_aus_RM" 8 "NM_NO_aus_RS" 16 "NM_RM_aus_RS" 32 "NM_RM_aus_NO" ;
VAL_ 2600468623 NM_AWC_Car_Wakeup 0 "Inaktiv" 1 "Car_Wakeup" ;
VAL_ 2600468623 NM_AWC_UDS_CC 0 "Init" 1 "CC_aktiv" ;
VAL_ 2600468623 NM_AWC_NM_aktiv_KL15 0 "Inaktiv" 1 "KL15_EIN" ;
VAL_ 2600468623 NM_AWC_NM_aktiv_Diagnose 0 "Init" 1 "Diagnose_aktiv" ;
VAL_ 2600468623 NM_AWC_NM_aktiv_Tmin 0 "Inaktiv" 1 "Mindestaktivzeit" ;
VAL_ 2600468623 NM_AWC_CAB 0 "inaktiv" 1 "CAB_01__Tueren" 2 "CAB_02__Anhaenger_KCAN" 4 "CAB_03__Nightvision" 8 "CAB_04__Sitzverstellung" 16 "CAB_05__Klappen" 32 "CAB_06__Infotainment" 64 "CAB_07__Sub_Infotainment" 128 "CAB_08__Anzeige" 256 "CAB_09__Laden_HCAN" 512 "CAB_10__Klima" 1024 "CAB_11__FlexRay" 262144 "CAB_19__VLAN_RemoteFC" 524288 "CAB_20__VLAN_Komfort" 1048576 "CAB_21__VLAN_Internet" 2097152 "CAB_22__VLAN_Connect" 4194304 "CAB_23__VLAN_Infotainment" 8388608 "CAB_24__VLAN_FAS" ;
VAL_ 2600468654 NM_BattRegelung_SNI 174 "BattRegelung" ;
VAL_ 2600468654 NM_BattRegelung_CBV_AWB 0 "Passiver_WakeUp" 1 "Aktiver_WakeUp" ;
VAL_ 2600468654 NM_BattRegelung_CBV_CRI 0 "Standard_Layout" 1 "TNB_Layout" ;
VAL_ 2600468654 NM_Battregelung_NM_State 0 "Init" 1 "NM_RM_aus_BSM" 2 "NM_RM_aus_PBSM" 4 "NM_NO_aus_RM" 8 "NM_NO_aus_RS" 16 "reserved" 32 "reserved" ;
VAL_ 2600468654 NM_BattRegelung_Car_Wakeup 0 "Inaktiv" 1 "Car_Wakeup" ;
VAL_ 2600468654 NM_BattRegelung_UDS_CC 0 "Init" 1 "CC_aktiv" ;
VAL_ 2600468654 NM_BattRegelung_NM_aktiv_KL15 0 "Inaktiv" 1 "KL15_EIN" ;
VAL_ 2600468654 NM_BattRegelungNM_aktiv_Diagnose 0 "Init" 1 "Diagnose_aktiv" ;
VAL_ 2600468654 NM_BattRegelung_NM_aktiv_Tmin 0 "Inaktiv" 1 "Mindestaktivzeit" ;
VAL_ 2600468654 NM_BattRegelung_NM_aktiv_NV 0 "Inaktiv" 1 "Niedervoltspeicher_angefordert" ;
VAL_ 2600468654 NM_BattRegelung_CAB 0 "inaktiv" 1 "CAB_01__Tueren" 2 "CAB_02__Anhaenger_KCAN" 4 "CAB_03__Nightvision" 8 "CAB_04__Sitzverstellung" 16 "CAB_05__Klappen" 32 "CAB_06__Infotainment" 64 "CAB_07__Sub_Infotainment" 128 "CAB_08__Anzeige" 256 "CAB_09__Laden_HCAN" 512 "CAB_10__Klima" 1024 "CAB_11__FlexRay" 262144 "CAB_19__VLAN_RemoteFC" 524288 "CAB_20__VLAN_Komfort" 1048576 "CAB_21__VLAN_Internet" 2097152 "CAB_22__VLAN_Connect" 4194304 "CAB_23__VLAN_Infotainment" 8388608 "CAB_24__VLAN_FAS" ;
VAL_ 2600468636 NM_BMS_48V_SNI 156 "BMS_MV" ;
VAL_ 2600468636 NM_BMS_48V_CBV_AWB 0 "Passiver_WakeUp" 1 "Aktiver_WakeUp" ;
VAL_ 2600468636 NM_BMS_48V_CBV_CRI 0 "Standard_Layout" 1 "TNB_Layout" ;
VAL_ 2600468636 NM_BMS_48V_NM_State 0 "Init" 1 "NM_RM_aus_BSM" 2 "NM_RM_aus_PBSM" 4 "NM_NO_aus_RM" 8 "NM_NO_aus_RS" 16 "reserved" 32 "reserved" ;
VAL_ 2600468636 NM_BMS_48V_Car_Wakeup 0 "Inaktiv" 1 "Car_Wakeup" ;
VAL_ 2600468636 NM_BMS_48V_UDS_CC 0 "Init" 1 "CC_aktiv" ;
VAL_ 2600468636 NM_BMS_48V_NM_aktiv_KL15 0 "Inaktiv" 1 "KL15_EIN" ;
VAL_ 2600468636 NM_BMS_48V_NM_aktiv_Diagnose 0 "Init" 1 "Diagnose_aktiv" ;
VAL_ 2600468636 NM_BMS_48V_NM_aktiv_Tmin 0 "Inaktiv" 1 "Mindestaktivzeit" ;
VAL_ 2600468636 NM_BMS_48V_NM_aktiv_Hochvolt 0 "kein_Nachlauf" 1 "Hochvolt_aktiv" ;
VAL_ 2600468636 NM_BMS_48V_CAB 0 "inaktiv" 1 "CAB_01__Tueren" 2 "CAB_02__Anhaenger_KCAN" 4 "CAB_03__Nightvision" 8 "CAB_04__Sitzverstellung" 16 "CAB_05__Klappen" 32 "CAB_06__Infotainment" 64 "CAB_07__Sub_Infotainment" 128 "CAB_08__Anzeige" 256 "CAB_09__Laden_HCAN" 512 "CAB_10__Klima" 1024 "CAB_11__FlexRay" 262144 "CAB_19__VLAN_RemoteFC" 524288 "CAB_20__VLAN_Komfort" 1048576 "CAB_21__VLAN_Internet" 2097152 "CAB_22__VLAN_Connect" 4194304 "CAB_23__VLAN_Infotainment" 8388608 "CAB_24__VLAN_FAS" ;
VAL_ 2600468545 NM_DCDC_SNI 65 "DCDC" ;
VAL_ 2600468545 NM_DCDC_CBV_AWB 0 "Passiver_WakeUp" 1 "Aktiver_WakeUp" ;
VAL_ 2600468545 NM_DCDC_CBV_CRI 0 "Standard_Layout" 1 "TNB_Layout" ;
VAL_ 2600468545 NM_DCDC_NM_State 1 "NM_RM_aus_BSM" 2 "NM_RM_aus_PBSM" 4 "NM_NO_aus_RM" 8 "NM_NO_aus_RS" 16 "NM_RM_aus_RS" 32 "NM_RM_aus_NO" ;
VAL_ 2600468545 NM_DCDC_Car_Wakeup 0 "Inaktiv" 1 "Car_Wakeup" ;
VAL_ 2600468545 NM_DCDC_UDS_CC 0 "Init" 1 "CC_aktiv" ;
VAL_ 2600468545 NM_DCDC_NM_aktiv_KL15 0 "Inaktiv" 1 "KL15_EIN" ;
VAL_ 2600468545 NM_DCDC_NM_aktiv_Diagnose 0 "Init" 1 "Diagnose_aktiv" ;
VAL_ 2600468545 NM_DCDC_NM_aktiv_Tmin 0 "Inaktiv" 1 "Mindestaktivzeit" ;
VAL_ 2600468545 NM_DCDC_NM_aktiv_Anf_MVK 0 "Inaktiv" 1 "12Volt_Versorgung_angefordert" ;
VAL_ 2600468545 NM_DCDC_CAB 0 "inaktiv" 1 "CAB_01__Tueren" 2 "CAB_02__Anhaenger_KCAN" 4 "CAB_03__Nightvision" 8 "CAB_04__Sitzverstellung" 16 "CAB_05__Klappen" 32 "CAB_06__Infotainment" 64 "CAB_07__Sub_Infotainment" 128 "CAB_08__Anzeige" 256 "CAB_09__Laden_HCAN" 512 "CAB_10__Klima" 1024 "CAB_11__FlexRay" 262144 "CAB_19__VLAN_RemoteFC" 524288 "CAB_20__VLAN_Komfort" 1048576 "CAB_21__VLAN_Internet" 2097152 "CAB_22__VLAN_Connect" 4194304 "CAB_23__VLAN_Infotainment" 8388608 "CAB_24__VLAN_FAS" ;
VAL_ 2600468663 NM_DCDC_HV_SNI 183 "DCDC_HV" ;
VAL_ 2600468663 NM_DCDC_HV_CBV_AWB 0 "Passiver_WakeUp" 1 "Aktiver_WakeUp" ;
VAL_ 2600468663 NM_DCDC_HV_CBV_CRI 0 "Standard_Layout" 1 "TNB_Layout" ;
VAL_ 2600468663 NM_DCDC_HV_NM_State 0 "Init" 1 "NM_RM_aus_BSM" 2 "NM_RM_aus_PBSM" 4 "NM_NO_aus_RM" 8 "NM_NO_aus_RS" ;
VAL_ 2600468663 NM_DCDC_HV_Car_Wakeup 0 "Inaktiv" 1 "Car_Wakeup" ;
VAL_ 2600468663 NM_DCDC_HV_UDS_CC 0 "Inaktiv" 1 "CC_aktiv" ;
VAL_ 2600468663 NM_DCDC_HV_NM_aktiv_KL15 0 "Inaktiv" 1 "KL15_EIN" ;
VAL_ 2600468663 NM_DCDC_HV_NM_aktiv_Diagnose 0 "Inaktiv" 1 "Diagnose_aktiv" ;
VAL_ 2600468663 NM_DCDC_HV_NM_aktiv_Tmin 0 "Inaktiv" 1 "Mindestaktivzeit" ;
VAL_ 2600468663 NM_DCDC_HV_NM_aktiv_Anf_HVK 0 "Inaktiv" 1 "HV_angefordert" ;
VAL_ 2600468663 NM_DCDC_HV_CAB 0 "inaktiv" 1 "CAB_01__Tueren" 2 "CAB_02__Anhaenger_KCAN" 4 "CAB_03__Nightvision" 8 "CAB_04__Sitzverstellung" 16 "CAB_05__Klappen" 32 "CAB_06__Infotainment" 64 "CAB_07__Sub_Infotainment" 128 "CAB_08__Anzeige" 256 "CAB_09__Laden_HCAN" 512 "CAB_10__Klima" 1024 "CAB_11__FlexRay" 262144 "CAB_19__VLAN_RemoteFC" 524288 "CAB_20__VLAN_Komfort" 1048576 "CAB_21__VLAN_Internet" 2097152 "CAB_22__VLAN_Connect" 4194304 "CAB_23__VLAN_Infotainment" 8388608 "CAB_24__VLAN_FAS" ;
VAL_ 2600468679 NM_DCDC_HV_02_SNI 199 "DCDC_HV_02" ;
VAL_ 2600468679 NM_DCDC_HV_02_CBV_AWB 0 "Passiver_WakeUp" 1 "Aktiver_WakeUp" ;
VAL_ 2600468679 NM_DCDC_HV_02_CBV_CRI 0 "Standard_Layout" 1 "TNB_Layout" ;
VAL_ 2600468679 NM_DCDC_HV_02_NM_State 0 "Init" 1 "NM_RM_aus_BSM" 2 "NM_RM_aus_PBSM" 4 "NM_NO_aus_RM" 8 "NM_NO_aus_RS" 16 "reserved" 32 "reserved" ;
VAL_ 2600468679 NM_DCDC_HV_02_Car_Wakeup 0 "Inaktiv" 1 "Car_Wakeup" ;
VAL_ 2600468679 NM_DCDC_HV_02_UDS_CC 0 "Inaktiv" 1 "CC_aktiv" ;
VAL_ 2600468679 NM_DCDC_HV_02_NM_aktiv_KL15 0 "Inaktiv" 1 "KL15_EIN" ;
VAL_ 2600468679 NM_DCDC_HV_02_NM_aktiv_Diag 0 "Init" 1 "Diagnose_aktiv" ;
VAL_ 2600468679 NM_DCDC_HV_02_NM_aktiv_Tmin 0 "Inaktiv" 1 "Mindestaktivzeit" ;
VAL_ 2600468679 NM_DCDC_HV_02_NM_aktiv_Anf_HVK 0 "Inaktiv" 1 "HV_angefordert" ;
VAL_ 2600468679 NM_DCDC_HV_02_CAB 0 "inaktiv" 1 "CAB_01__Tueren" 2 "CAB_02__Anhaenger_KCAN" 4 "CAB_03__Nightvision" 8 "CAB_04__Sitzverstellung" 16 "CAB_05__Klappen" 32 "CAB_06__Infotainment" 64 "CAB_07__Sub_Infotainment" 128 "CAB_08__Anzeige" 256 "CAB_09__Laden_HCAN" 512 "CAB_10__Klima" 1024 "CAB_11__FlexRay" 262144 "CAB_19__VLAN_RemoteFC" 524288 "CAB_20__VLAN_Komfort" 1048576 "CAB_21__VLAN_Internet" 2097152 "CAB_22__VLAN_Connect" 4194304 "CAB_23__VLAN_Infotainment" 8388608 "CAB_24__VLAN_FAS" ;
VAL_ 2600468661 NM_FCU_SNI 181 "FCU" ;
VAL_ 2600468661 NM_FCU_CBV_AWB 0 "Passiver_WakeUp" 1 "Aktiver_WakeUp" ;
VAL_ 2600468661 NM_FCU_CBV_CRI 0 "Standard_Layout" 1 "TNB_Layout" ;
VAL_ 2600468661 NM_FCU_NM_State 0 "Init" 1 "NM_RM_aus_BSM" 2 "NM_RM_aus_PBSM" 4 "NM_NO_aus_RM" 8 "NM_NO_aus_RS" 16 "reserved" 32 "reserved" ;
VAL_ 2600468661 NM_FCU_Car_Wakeup 0 "Inaktiv" 1 "Car_Wakeup" ;
VAL_ 2600468661 NM_FCU_UDS_CC 0 "Inaktiv" 1 "CC_aktiv" ;
VAL_ 2600468661 NM_FCU_NM_aktiv_KL15 0 "Inaktiv" 1 "KL15_EIN" ;
VAL_ 2600468661 NM_FCU_NM_aktiv_Diag 0 "Init" 1 "Diagnose_aktiv" ;
VAL_ 2600468661 NM_FCU_NM_aktiv_Tmin 0 "Inaktiv" 1 "Mindestaktivzeit" ;
VAL_ 2600468661 NM_FCU_NM_aktiv_Shutdown 0 "Inaktiv" 1 "Shutdown_eingeleitet" ;
VAL_ 2600468661 NM_FCU_NM_aktiv_HCAN 0 "Inaktiv" 1 "HCAN_aktiv" ;
VAL_ 2600468661 NM_FCU_NM_aktiv_Tankvorgang 0 "Inaktiv" 1 "Aktiver_Tankvorgang" ;
VAL_ 2600468661 NM_FCU_CAB 0 "inaktiv" 1 "CAB_01__Tueren" 2 "CAB_02__Anhaenger_KCAN" 4 "CAB_03__Nightvision" 8 "CAB_04__Sitzverstellung" 16 "CAB_05__Klappen" 32 "CAB_06__Infotainment" 64 "CAB_07__Sub_Infotainment" 128 "CAB_08__Anzeige" 256 "CAB_09__Laden_HCAN" 512 "CAB_10__Klima" 1024 "CAB_11__FlexRay" 262144 "CAB_19__VLAN_RemoteFC" 524288 "CAB_20__VLAN_Komfort" 1048576 "CAB_21__VLAN_Internet" 2097152 "CAB_22__VLAN_Connect" 4194304 "CAB_23__VLAN_Infotainment" 8388608 "CAB_24__VLAN_FAS" ;
VAL_ 2600468496 NM_Gateway_SNI 16 "Gateway" ;
VAL_ 2600468496 NM_Gateway_CBV_AWB 0 "Passiver_WakeUp" 1 "Aktiver_WakeUp" ;
VAL_ 2600468496 NM_Gateway_CBV_CRI 0 "Standard_Layout" 1 "TNB_Layout" ;
VAL_ 2600468496 NM_Gateway_NM_State 0 "Init" 1 "NM_RM_aus_BSM" 2 "NM_RM_aus_PBSM" 4 "NM_NO_aus_RM" 8 "NM_NO_aus_RS" 16 "NM_RM_aus_RS" 32 "NM_RM_aus_NO" ;
VAL_ 2600468496 NM_Gateway_Car_Wakeup 0 "Inaktiv" 1 "Car_Wakeup" ;
VAL_ 2600468496 NM_Gateway_UDS_CC 0 "Init" 1 "CC_aktiv" ;
VAL_ 2600468496 NM_Gateway_NM_aktiv_KL15 0 "Inaktiv" 1 "KL15_EIN" ;
VAL_ 2600468496 NM_Gateway_NM_aktiv_Diagnose 0 "Init" 1 "Diagnose_aktiv" ;
VAL_ 2600468496 NM_Gateway_NM_aktiv_Tmin 0 "Inaktiv" 1 "Mindestaktivzeit" ;
VAL_ 2600468496 NM_Gateway_NM_aktiv_CWU 0 "kein_CWU_gesetzt" 1 "CWU_gesetzt" ;
VAL_ 2600468496 NM_Gateway_NM_aktiv_FC 0 "kein_FC_gesetzt" 1 "FC_gesetzt" ;
VAL_ 2600468496 NM_Gateway_NM_aktiv_Connect 0 "inaktiv" 1 "Nachlauf_aufgrund_Connect" ;
VAL_ 2600468496 NM_Gateway_NM_aktiv_EM 0 "inaktiv" 1 "Nachlauf_aufgrund_Energiemanagement" ;
VAL_ 2600468496 NM_Gateway_NM_aktiv_OBDC 0 "kein_Nachlauf" 1 "Nachlauf_aufgrund_OBDC" ;
VAL_ 2600468496 NM_Gateway_NM_aktiv_Buskopplung 0 "inaktiv" 1 "Nachlauf_aufgrund_Buskopplung" ;
VAL_ 2600468496 NM_Gateway_NM_aktiv_LIN2 0 "Inaktiv" 1 "LIN2_aktiv" ;
VAL_ 2600468496 NM_Gateway_CAB 0 "inaktiv" 1 "CAB_01__Tueren" 2 "CAB_02__Anhaenger_KCAN" 4 "CAB_03__Nightvision" 8 "CAB_04__Sitzverstellung" 16 "CAB_05__Klappen" 32 "CAB_06__Infotainment" 64 "CAB_07__Sub_Infotainment" 128 "CAB_08__Anzeige" 256 "CAB_09__Laden_HCAN" 512 "CAB_10__Klima" 1024 "CAB_11__FlexRay" 262144 "CAB_19__VLAN_RemoteFC" 524288 "CAB_20__VLAN_Komfort" 1048576 "CAB_21__VLAN_Internet" 2097152 "CAB_22__VLAN_Connect" 4194304 "CAB_23__VLAN_Infotainment" 8388608 "CAB_24__VLAN_FAS" ;
VAL_ 2600468603 NM_Hybrid_01_SNI 123 "Hybrid_01" ;
VAL_ 2600468603 NM_Hybrid_01_CBV_AWB 0 "Passiver_WakeUp" 1 "Aktiver_WakeUp" ;
VAL_ 2600468603 NM_Hybrid_01_CBV_CRI 0 "Standard_Layout" 1 "TNB_Layout" ;
VAL_ 2600468603 NM_Hybrid_01_NM_State 0 "Init" 1 "NM_RM_aus_BSM" 2 "NM_RM_aus_PBSM" 4 "NM_NO_aus_RM" 8 "NM_NO_aus_RS" 16 "NM_RM_aus_RS" 32 "NM_RM_aus_NO" ;
VAL_ 2600468603 NM_Hybrid_01_Car_Wakeup 0 "Inaktiv" 1 "Car_Wakeup" ;
VAL_ 2600468603 NM_Hybrid_01_UDS_CC 0 "Init" 1 "CC_aktiv" ;
VAL_ 2600468603 NM_Hybrid_01_NM_aktiv_KL15 0 "Inaktiv" 1 "KL15_EIN" ;
VAL_ 2600468603 NM_Hybrid_01_NM_aktiv_Diagnose 0 "Init" 1 "Diagnose_aktiv" ;
VAL_ 2600468603 NM_Hybrid_01_NM_aktiv_Tmin 0 "Inaktiv" 1 "Mindestaktivzeit" ;
VAL_ 2600468603 NM_Hybrid_01_NM_aktiv_Hochvolt 0 "kein_Nachlauf" 1 "Hochvolt_aktiv" ;
VAL_ 2600468603 NM_BMC_NM_aktiv_HCAN 0 "Inaktiv" 1 "H_CAN_aktiv" ;
VAL_ 2600468603 NM_Hybrid_01_CAB 0 "inaktiv" 1 "CAB_01__Tueren" 2 "CAB_02__Anhaenger_KCAN" 4 "CAB_03__Nightvision" 8 "CAB_04__Sitzverstellung" 16 "CAB_05__Klappen" 32 "CAB_06__Infotainment" 64 "CAB_07__Sub_Infotainment" 128 "CAB_08__Anzeige" 256 "CAB_09__Laden_HCAN" 512 "CAB_10__Klima" 1024 "CAB_11__FlexRay" 262144 "CAB_19__VLAN_RemoteFC" 524288 "CAB_20__VLAN_Komfort" 1048576 "CAB_21__VLAN_Internet" 2097152 "CAB_22__VLAN_Connect" 4194304 "CAB_23__VLAN_Infotainment" 8388608 "CAB_24__VLAN_FAS" ;
VAL_ 2600468548 NM_Ladegeraet_SNI 68 "Ladegeraet" ;
VAL_ 2600468548 NM_Ladegeraet_CBV_AWB 0 "Passiver_WakeUp" 1 "Aktiver_WakeUp" ;
VAL_ 2600468548 NM_Ladegeraet_CBV_CRI 0 "Standard_Layout" 1 "TNB_Layout" ;
VAL_ 2600468548 NM_Ladegeraet_NM_State 0 "Init" 1 "NM_RM_aus_BSM" 2 "NM_RM_aus_PBSM" 4 "NM_NO_aus_RM" 8 "NM_NO_aus_RS" 16 "reserved" 32 "reserved" ;
VAL_ 2600468548 NM_Ladegeraet_Car_Wakeup 0 "Inaktiv" 1 "Car_Wakeup" ;
VAL_ 2600468548 NM_Ladegeraet_UDS_CC 0 "Init" 1 "CC_aktiv" ;
VAL_ 2600468548 NM_Ladegeraet_NM_aktiv_KL15 0 "Inaktiv" 1 "KL15_EIN" ;
VAL_ 2600468548 NM_Ladegeraet_NM_aktiv_Diagnose 0 "Init" 1 "Diagnose_aktiv" ;
VAL_ 2600468548 NM_Ladegeraet_NM_aktiv_Tmin 0 "Inaktiv" 1 "Mindestaktivzeit" ;
VAL_ 2600468548 NM_Ladegeraet_NM_aktiv_Bere_CVN 0 "Init" 1 "CVN_Berechnung_aktiv" ;
VAL_ 2600468548 NM_Ladegeraet_NM_aktiv_Vorkondit 0 "kein_Nachlauf" 1 "Vorkonditionierung_aktiv" ;
VAL_ 2600468548 NM_Ladegeraet_NM_aktiv_CVN_Berec 0 "kein_Nachlauf" 1 "CVN_Berechnung_aktiv" ;
VAL_ 2600468548 NM_Ladegeraet_NM_aktiv_NotlaufSt 0 "Init" 1 "Stecker_Notlauf_aktiv" ;
VAL_ 2600468548 NM_Ladegeraet_NM_aktiv_Ladezeit 0 "Init" 1 "Ladezeitberechnung" ;
VAL_ 2600468548 NM_Ladegeraet_NM_aktiv_Laden 0 "Init" 1 "Ladevorgang_aktiv" ;
VAL_ 2600468548 NM_Ladegeraet_CAB 0 "inaktiv" 1 "CAB_01__Tueren" 2 "CAB_02__Anhaenger_KCAN" 4 "CAB_03__Nightvision" 8 "CAB_04__Sitzverstellung" 16 "CAB_05__Klappen" 32 "CAB_06__Infotainment" 64 "CAB_07__Sub_Infotainment" 128 "CAB_08__Anzeige" 256 "CAB_09__Laden_HCAN" 512 "CAB_10__Klima" 1024 "CAB_11__FlexRay" 262144 "CAB_19__VLAN_RemoteFC" 524288 "CAB_20__VLAN_Komfort" 1048576 "CAB_21__VLAN_Internet" 2097152 "CAB_22__VLAN_Connect" 4194304 "CAB_23__VLAN_Infotainment" 8388608 "CAB_24__VLAN_FAS" ;
VAL_ 2600468678 NM_Ladegeraet_2_SNI 198 "Ladegeraet_2" ;
VAL_ 2600468678 NM_Ladegeraet_2_CBV_AWB 0 "Passiver_WakeUp" 1 "Aktiver_WakeUp" ;
VAL_ 2600468678 NM_Ladegeraet_2_CBV_CRI 0 "Standard_Layout" 1 "TNB_Layout" ;
VAL_ 2600468678 NM_Ladegeraet_2_NM_State 0 "Init" 1 "NM_RM_aus_BSM" 2 "NM_RM_aus_PBSM" 4 "NM_NO_aus_RM" 8 "NM_NO_aus_RS" 16 "reserved" 32 "reserved" ;
VAL_ 2600468678 NM_Ladegeraet_2_Car_Wakeup 0 "Inaktiv" 1 "Car_Wakeup" ;
VAL_ 2600468678 NM_Ladegeraet_2_UDS_CC 0 "Inaktiv" 1 "CC_aktiv" ;
VAL_ 2600468678 NM_Ladegeraet_2_NM_aktiv_KL15 0 "Inaktiv" 1 "KL15_EIN" ;
VAL_ 2600468678 NM_Ladegeraet_2_NM_aktiv_Diag 0 "Init" 1 "Diagnose_aktiv" ;
VAL_ 2600468678 NM_Ladegeraet_2_NM_aktiv_Tmin 0 "Inaktiv" 1 "Mindestaktivzeit" ;
VAL_ 2600468678 NM_Ladegeraet_2_NM_aktiv_Laden 0 "Init" 1 "Ladevorgang_aktiv" ;
VAL_ 2600468678 NM_Ladegeraet_2_CAB 0 "inaktiv" 1 "CAB_01__Tueren" 2 "CAB_02__Anhaenger_KCAN" 4 "CAB_03__Nightvision" 8 "CAB_04__Sitzverstellung" 16 "CAB_05__Klappen" 32 "CAB_06__Infotainment" 64 "CAB_07__Sub_Infotainment" 128 "CAB_08__Anzeige" 256 "CAB_09__Laden_HCAN" 512 "CAB_10__Klima" 1024 "CAB_11__FlexRay" 262144 "CAB_19__VLAN_RemoteFC" 524288 "CAB_20__VLAN_Komfort" 1048576 "CAB_21__VLAN_Internet" 2097152 "CAB_22__VLAN_Connect" 4194304 "CAB_23__VLAN_Infotainment" 8388608 "CAB_24__VLAN_FAS" ;
VAL_ 2600468481 NM_Sekundaer_01_SNI 1 "Sekundaer_01" ;
VAL_ 2600468481 NM_Sekundaer_01_CBV_AWB 0 "Passiver_WakeUp" 1 "Aktiver_WakeUp" ;
VAL_ 2600468481 NM_Sekundaer_01_CBV_CRI 0 "Standard_Layout" 1 "TNB_Layout" ;
VAL_ 2600468481 NM_Sekundaer_01_NM_State 0 "Inaktiv" 1 "NM_RM_aus_BSM" 2 "NM_RM_aus_PBSM" 4 "NM_NO_aus_RM" 8 "NM_NO_aus_RS" 16 "NM_RM_aus_NO" 32 "NM_RM_aus_RS" ;
VAL_ 2600468481 NM_Sekundaer_01_Car_Wakeup 0 "Inaktiv" 1 "Car_Wakeup" ;
VAL_ 2600468481 NM_Sekundaer_01_UDS_CC 0 "Inaktiv" 1 "CC_aktiv" ;
VAL_ 2600468481 NM_Sekundaer_01_NM_aktiv_KL15 0 "Inaktiv" 1 "KL15_EIN" ;
VAL_ 2600468481 NM_Sekundaer_01_NM_aktiv_Diag 0 "Inaktiv" 1 "Diagnose_aktiv" ;
VAL_ 2600468481 NM_Sekundaer_01_NM_aktiv_Tmin 0 "Inaktiv" 1 "Mindestaktivzeit" ;
VAL_ 2600468481 NM_Sekundaer_01_NM_aktiv_Anf_HVK 0 "Inaktiv" 1 "12Volt_Versorgung_angefordert" ;
VAL_ 2600468481 NM_Sekundaer_01_CAB 0 "inaktiv" 1 "CAB_01__Tueren" 2 "CAB_02__Anhaenger_KCAN" 4 "CAB_03__Nightvision" 8 "CAB_04__Sitzverstellung" 16 "CAB_05__Klappen" 32 "CAB_06__Infotainment" 64 "CAB_07__Sub_Infotainment" 128 "CAB_08__Anzeige" 256 "CAB_09__Laden_HCAN" 512 "CAB_10__Klima" 1024 "CAB_11__FlexRay" 262144 "CAB_19__VLAN_RemoteFC" 524288 "CAB_20__VLAN_Komfort" 1048576 "CAB_21__VLAN_Internet" 2097152 "CAB_22__VLAN_Connect" 4194304 "CAB_23__VLAN_Infotainment" 8388608 "CAB_24__VLAN_FAS" ;
VAL_ 2600468483 NM_Sekundaer_03_SNI 3 "Sekundaer_03" ;
VAL_ 2600468483 NM_Sekundaer_03_CBV_AWB 0 "Passiver_WakeUp" 1 "Aktiver_WakeUp" ;
VAL_ 2600468483 NM_Sekundaer_03_CBV_CRI 0 "Standard_Layout" 1 "TNB_Layout" ;
VAL_ 2600468483 NM_Sekundaer_03_NM_State 0 "Inaktiv" 1 "NM_RM_aus_BSM" 2 "NM_RM_aus_PBSM" 4 "NM_NO_aus_RM" 8 "NM_NO_aus_RS" 16 "NM_RM_aus_NO" 32 "NM_RM_aus_RS" ;
VAL_ 2600468483 NM_Sekundaer_03_Car_Wakeup 0 "Inaktiv" 1 "Car_Wakeup" ;
VAL_ 2600468483 NM_Sekundaer_03_UDS_CC 0 "Inaktiv" 1 "CC_aktiv" ;
VAL_ 2600468483 NM_Sekundaer_03_NM_aktiv_KL15 0 "Inaktiv" 1 "KL15_EIN" ;
VAL_ 2600468483 NM_Sekundaer_03_NM_aktiv_Diagnos 0 "Inaktiv" 1 "Diagnose_aktiv" ;
VAL_ 2600468483 NM_Sekundaer_03_NM_aktiv_Tmin 0 "Inaktiv" 1 "Mindestaktivzeit" ;
VAL_ 2600468483 NM_Sekundaer_03_NM_aktiv_Anf_HVK 0 "Inaktiv" 1 "12Volt_Versorgung_angefordert" ;
VAL_ 2600468483 NM_Sekundaer_03_CAB 0 "inaktiv" 1 "CAB_01__Tueren" 2 "CAB_02__Anhaenger_KCAN" 4 "CAB_03__Nightvision" 8 "CAB_04__Sitzverstellung" 16 "CAB_05__Klappen" 32 "CAB_06__Infotainment" 64 "CAB_07__Sub_Infotainment" 128 "CAB_08__Anzeige" 256 "CAB_09__Laden_HCAN" 512 "CAB_10__Klima" 1024 "CAB_11__FlexRay" 262144 "CAB_19__VLAN_RemoteFC" 524288 "CAB_20__VLAN_Komfort" 1048576 "CAB_21__VLAN_Internet" 2097152 "CAB_22__VLAN_Connect" 4194304 "CAB_23__VLAN_Infotainment" 8388608 "CAB_24__VLAN_FAS" ;
VAL_ 2600468553 NM_Sub_Gateway_SNI 73 "Sub_Gateway" ;
VAL_ 2600468553 NM_Sub_Gateway_CBV_AWB 0 "Passiver_WakeUp" 1 "Aktiver_WakeUp" ;
VAL_ 2600468553 NM_Sub_Gateway_CBV_CRI 0 "Standard_Layout" 1 "TNB_Layout" ;
VAL_ 2600468553 NM_Sub_Gateway_NM_State 1 "NM_RM_aus_BSM" 2 "NM_RM_aus_PBSM" 4 "NM_NO_aus_RM" 8 "NM_NO_aus_RS" 16 "NM_RM_aus_RS" 32 "NM_RM_aus_NO" ;
VAL_ 2600468553 NM_Sub_Gateway_Car_Wakeup 0 "Inaktiv" 1 "Car_Wakeup" ;
VAL_ 2600468553 NM_Sub_Gateway_UDS_CC 0 "Init" 1 "CC_aktiv" ;
VAL_ 2600468553 NM_Sub_Gateway_NM_aktiv_KL15 0 "Inaktiv" 1 "KL15_EIN" ;
VAL_ 2600468553 NM_Sub_Gateway_NM_aktiv_Diagnose 0 "Inaktiv" 1 "Diagnose_aktiv" ;
VAL_ 2600468553 NM_Sub_Gateway_NM_aktiv_Tmin 0 "Inaktiv" 1 "Mindestaktivzeit" ;
VAL_ 2600468553 NM_Sub_Gateway_CAB 0 "inaktiv" 1 "CAB_01__Tueren" 2 "CAB_02__Anhaenger_KCAN" 4 "CAB_03__Nightvision" 8 "CAB_04__Sitzverstellung" 16 "CAB_05__Klappen" 32 "CAB_06__Infotainment" 64 "CAB_07__Sub_Infotainment" 128 "CAB_08__Anzeige" 256 "CAB_09__Laden_HCAN" 512 "CAB_10__Klima" 1024 "CAB_11__FlexRay" 262144 "CAB_19__VLAN_RemoteFC" 524288 "CAB_20__VLAN_Komfort" 1048576 "CAB_21__VLAN_Internet" 2097152 "CAB_22__VLAN_Connect" 4194304 "CAB_23__VLAN_Infotainment" 8388608 "CAB_24__VLAN_FAS" ;
